VERSION ""

NS_ :

BS_:

BU_: ETH

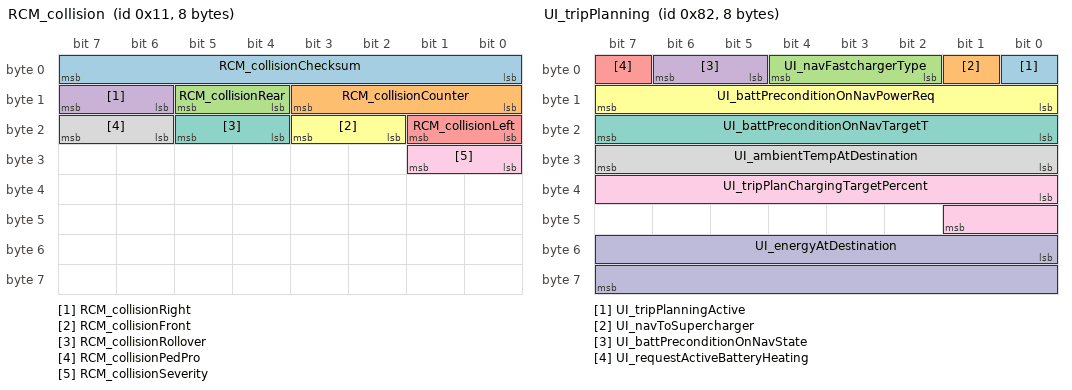
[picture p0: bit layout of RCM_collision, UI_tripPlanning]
BO_ 17 RCM_collision: 8 Vector__XXX
 SG_ RCM_collisionChecksum : 0|8@1+ (1,0) [0|0] "" Vector__XXX
 SG_ RCM_collisionCounter : 8|4@1+ (1,0) [0|0] "" Vector__XXX
 SG_ RCM_collisionRear : 12|2@1+ (1,0) [0|0] "" Vector__XXX
 SG_ RCM_collisionRight : 14|2@1+ (1,0) [0|0] "" Vector__XXX
 SG_ RCM_collisionLeft : 16|2@1+ (1,0) [0|0] "" Vector__XXX
 SG_ RCM_collisionFront : 18|2@1+ (1,0) [0|0] "" Vector__XXX
 SG_ RCM_collisionRollover : 20|2@1+ (1,0) [0|0] "" Vector__XXX
 SG_ RCM_collisionPedPro : 22|2@1+ (1,0) [0|0] "" Vector__XXX
 SG_ RCM_collisionSeverity : 24|2@1+ (1,0) [0|0] "" Vector__XXX

BO_ 79 UI_locationStatus: 8 Vector__XXX
 SG_ UI_latitude : 0|28@1- (1e-06,0) [0|0] "" Vector__XXX
 SG_ UI_longitude : 28|29@1- (1e-06,0) [0|0] "" Vector__XXX
 SG_ UI_gpsAccuracy : 57|7@1+ (0.2,0) [0|0] "" Vector__XXX

BO_ 130 UI_tripPlanning: 8 Vector__XXX
 SG_ UI_tripPlanningActive : 0|1@1+ (1,0) [0|0] "" Vector__XXX
 SG_ UI_navToSupercharger : 1|1@1+ (1,0) [0|0] "" Vector__XXX
 SG_ UI_navFastchargerType : 2|3@1+ (1,0) [0|0] "" Vector__XXX
 SG_ UI_battPreconditionOnNavState : 5|2@1+ (1,0) [0|0] "" Vector__XXX
 SG_ UI_requestActiveBatteryHeating : 7|1@1+ (1,0) [0|0] "" Vector__XXX
 SG_ UI_battPreconditionOnNavPowerReq : 8|8@1- (125,0) [0|0] "" Vector__XXX
 SG_ UI_battPreconditionOnNavTargetT : 16|8@1+ (0.25,0) [0|0] "" Vector__XXX
 SG_ UI_ambientTempAtDestination : 24|8@1- (0.5,0) [0|0] "" Vector__XXX
 SG_ UI_tripPlanChargingTargetPercent : 32|10@1+ (0.1,0) [0|0] "" Vector__XXX
 SG_ UI_energyAtDestination : 48|16@1- (0.01,0) [0|0] "" Vector__XXX

BO_ 258 VCLEFT_doorStatus: 8 Vector__XXX
 SG_ VCLEFT_doorClosureStatusFront : 0|4@1+ (1,0) [0|0] "" Vector__XXX
 SG_ VCLEFT_doorClosureStatusRear : 4|4@1+ (1,0) [0|0] "" Vector__XXX
 SG_ VCLEFT_frontLatchSwitch : 8|1@1+ (1,0) [0|0] "" Vector__XXX
 SG_ VCLEFT_rearLatchSwitch : 9|1@1+ (1,0) [0|0] "" Vector__XXX
 SG_ VCLEFT_frontHandlePulled : 10|1@1+ (1,0) [0|0] "" Vector__XXX
 SG_ VCLEFT_rearHandlePulled : 11|1@1+ (1,0) [0|0] "" Vector__XXX
 SG_ VCLEFT_frontRelActuatorSwitch : 12|1@1+ (1,0) [0|0] "" Vector__XXX
 SG_ VCLEFT_rearRelActuatorSwitch : 13|1@1+ (1,0) [0|0] "" Vector__XXX
 SG_ VCLEFT_frontLatchStatus : 14|4@1+ (1,0) [0|0] "" Vector__XXX
 SG_ VCLEFT_rearLatchStatus : 18|4@1+ (1,0) [0|0] "" Vector__XXX
 SG_ VCLEFT_lastDoorReqSourceFront : 22|3@1+ (1,0) [0|0] "" Vector__XXX
 SG_ VCLEFT_lastDoorReqSourceRear : 25|3@1+ (1,0) [0|0] "" Vector__XXX
 SG_ VCLEFT_frontIntSwitchFaulted : 28|1@1+ (1,0) [0|0] "" Vector__XXX
 SG_ VCLEFT_rearIntSwitchFaulted : 29|1@1+ (1,0) [0|0] "" Vector__XXX
 SG_ VCLEFT_frontIntSwitchPressed : 31|1@1+ (1,0) [0|0] "" Vector__XXX
 SG_ VCLEFT_rearIntSwitchPressed : 32|1@1+ (1,0) [0|0] "" Vector__XXX
 SG_ VCLEFT_mirrorTiltXPosition : 33|8@1+ (0.02,0) [0|0] "" Vector__XXX
 SG_ VCLEFT_mirrorTiltYPosition : 41|8@1+ (0.02,0) [0|0] "" Vector__XXX
 SG_ VCLEFT_mirrorState : 49|3@1+ (1,0) [0|0] "" Vector__XXX
 SG_ VCLEFT_mirrorFoldState : 52|3@1+ (1,0) [0|0] "" Vector__XXX
 SG_ VCLEFT_mirrorRecallState : 55|3@1+ (1,0) [0|0] "" Vector__XXX
 SG_ VCLEFT_mirrorHeatState : 58|3@1+ (1,0) [0|0] "" Vector__XXX
 SG_ VCLEFT_rearHandlePulledPersist : 61|1@1+ (1,0) [0|0] "" Vector__XXX
 SG_ VCLEFT_frontHandlePulledPersist : 62|1@1+ (1,0) [0|0] "" Vector__XXX
 SG_ VCLEFT_mirrorDipped : 63|1@1+ (1,0) [0|0] "" Vector__XXX

BO_ 259 VCRIGHT_doorStatus: 8 Vector__XXX
 SG_ VCRIGHT_doorClosureStatusFront : 0|4@1+ (1,0) [0|0] "" Vector__XXX
 SG_ VCRIGHT_doorClosureStatusRear : 4|4@1+ (1,0) [0|0] "" Vector__XXX
 SG_ VCRIGHT_frontLatchSwitch : 8|1@1+ (1,0) [0|0] "" Vector__XXX
 SG_ VCRIGHT_rearLatchSwitch : 9|1@1+ (1,0) [0|0] "" Vector__XXX
 SG_ VCRIGHT_frontHandlePulled : 10|1@1+ (1,0) [0|0] "" Vector__XXX
 SG_ VCRIGHT_rearHandlePulled : 11|1@1+ (1,0) [0|0] "" Vector__XXX
 SG_ VCRIGHT_frontRelActuatorSwitch : 12|1@1+ (1,0) [0|0] "" Vector__XXX
 SG_ VCRIGHT_rearRelActuatorSwitch : 13|1@1+ (1,0) [0|0] "" Vector__XXX
 SG_ VCRIGHT_frontLatchStatus : 14|4@1+ (1,0) [0|0] "" Vector__XXX
 SG_ VCRIGHT_rearLatchStatus : 18|4@1+ (1,0) [0|0] "" Vector__XXX
 SG_ VCRIGHT_lastDoorReqSourceFront : 22|3@1+ (1,0) [0|0] "" Vector__XXX
 SG_ VCRIGHT_lastDoorReqSourceRear : 25|3@1+ (1,0) [0|0] "" Vector__XXX
 SG_ VCRIGHT_frontIntSwitchFaulted : 28|1@1+ (1,0) [0|0] "" Vector__XXX
 SG_ VCRIGHT_rearIntSwitchFaulted : 29|1@1+ (1,0) [0|0] "" Vector__XXX
 SG_ VCRIGHT_frontHandlePulledPersist : 30|1@1+ (1,0) [0|0] "" Vector__XXX
 SG_ VCRIGHT_frontIntSwitchPressed : 31|1@1+ (1,0) [0|0] "" Vector__XXX
 SG_ VCRIGHT_rearIntSwitchPressed : 32|1@1+ (1,0) [0|0] "" Vector__XXX
 SG_ VCRIGHT_mirrorTiltXPosition : 33|8@1+ (0.02,0) [0|0] "" Vector__XXX
 SG_ VCRIGHT_mirrorTiltYPosition : 41|8@1+ (0.02,0) [0|0] "" Vector__XXX
 SG_ VCRIGHT_mirrorState : 49|3@1+ (1,0) [0|0] "" Vector__XXX
 SG_ VCRIGHT_mirrorFoldState : 52|3@1+ (1,0) [0|0] "" Vector__XXX
 SG_ VCRIGHT_mirrorDipped : 55|1@1+ (1,0) [0|0] "" Vector__XXX
 SG_ VCRIGHT_trunkLatchStatus : 56|4@1+ (1,0) [0|0] "" Vector__XXX
 SG_ VCRIGHT_mirrorRecallState : 60|3@1+ (1,0) [0|0] "" Vector__XXX
 SG_ VCRIGHT_rearHandlePulledPersist : 63|1@1+ (1,0) [0|0] "" Vector__XXX

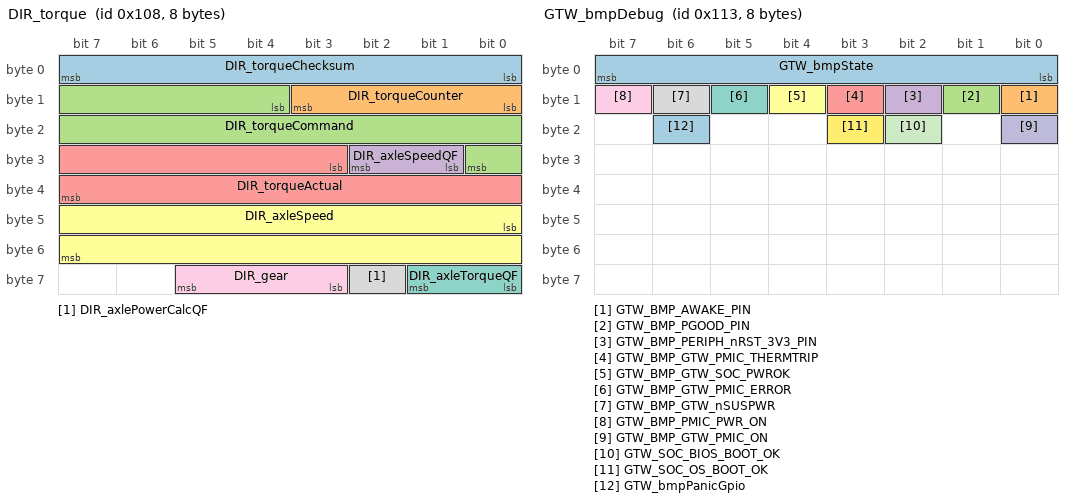
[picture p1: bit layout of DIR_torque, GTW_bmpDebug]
BO_ 264 DIR_torque: 8 Vector__XXX
 SG_ DIR_torqueChecksum : 0|8@1+ (1,0) [0|0] "" Vector__XXX
 SG_ DIR_torqueCounter : 8|4@1+ (1,0) [0|0] "" Vector__XXX
 SG_ DIR_torqueCommand : 12|13@1- (2,0) [0|0] "" Vector__XXX
 SG_ DIR_axleSpeedQF : 25|2@1+ (1,0) [0|0] "" Vector__XXX
 SG_ DIR_torqueActual : 27|13@1- (2,0) [0|0] "" Vector__XXX
 SG_ DIR_axleSpeed : 40|16@1- (0.1,0) [0|0] "" Vector__XXX
 SG_ DIR_axleTorqueQF : 56|2@1+ (1,0) [0|0] "" Vector__XXX
 SG_ DIR_axlePowerCalcQF : 58|1@1+ (1,0) [0|0] "" Vector__XXX
 SG_ DIR_gear : 59|3@1+ (1,0) [0|0] "" Vector__XXX

BO_ 275 GTW_bmpDebug: 8 Vector__XXX
 SG_ GTW_bmpState : 7|8@0+ (1,0) [0|0] "" Vector__XXX
 SG_ GTW_BMP_AWAKE_PIN : 8|1@1+ (1,0) [0|0] "" Vector__XXX
 SG_ GTW_BMP_PGOOD_PIN : 9|1@1+ (1,0) [0|0] "" Vector__XXX
 SG_ GTW_BMP_PERIPH_nRST_3V3_PIN : 10|1@1+ (1,0) [0|0] "" Vector__XXX
 SG_ GTW_BMP_GTW_PMIC_THERMTRIP : 11|1@1+ (1,0) [0|0] "" Vector__XXX
 SG_ GTW_BMP_GTW_SOC_PWROK : 12|1@1+ (1,0) [0|0] "" Vector__XXX
 SG_ GTW_BMP_GTW_PMIC_ERROR : 13|1@1+ (1,0) [0|0] "" Vector__XXX
 SG_ GTW_BMP_GTW_nSUSPWR : 14|1@1+ (1,0) [0|0] "" Vector__XXX
 SG_ GTW_BMP_PMIC_PWR_ON : 15|1@1+ (1,0) [0|0] "" Vector__XXX
 SG_ GTW_BMP_GTW_PMIC_ON : 16|1@1+ (1,0) [0|0] "" Vector__XXX
 SG_ GTW_SOC_BIOS_BOOT_OK : 18|1@1+ (1,0) [0|0] "" Vector__XXX
 SG_ GTW_SOC_OS_BOOT_OK : 19|1@1+ (1,0) [0|0] "" Vector__XXX
 SG_ GTW_bmpPanicGpio : 22|1@0+ (1,0) [0|0] "" Vector__XXX

BO_ 280 DI_systemStatus: 8 Vector__XXX
 SG_ DI_systemStatusChecksum : 0|8@1+ (1,0) [0|0] "" Vector__XXX
 SG_ DI_systemStatusCounter : 8|4@1+ (1,0) [0|0] "" Vector__XXX
 SG_ DI_immobilizerState : 13|3@1+ (1,0) [0|0] "" Vector__XXX
 SG_ DI_systemState : 16|3@1+ (1,0) [0|0] "" Vector__XXX
 SG_ DI_brakePedalState : 19|2@1+ (1,0) [0|0] "" Vector__XXX
 SG_ DI_gear : 21|3@1+ (1,0) [0|0] "" Vector__XXX
 SG_ DI_driveBlocked : 24|3@1+ (1,0) [0|0] "" Vector__XXX
 SG_ DI_hvilSystemStatus : 27|2@1+ (1,0) [0|0] "" Vector__XXX
 SG_ DI_accelPedalPos : 32|8@1+ (0.4,0) [0|0] "" Vector__XXX
 SG_ DI_tractionControlMode : 40|3@1+ (1,0) [0|0] "" Vector__XXX
 SG_ DI_dynoModeAvailable : 43|1@1+ (1,0) [0|0] "" Vector__XXX
 SG_ DI_epbRequest : 44|2@1+ (1,0) [0|0] "" Vector__XXX
 SG_ DI_brakeSource : 46|1@1+ (1,0) [0|0] "" Vector__XXX
 SG_ DI_keepDrivePowerStateRequest : 47|1@1+ (1,0) [0|0] "" Vector__XXX
 SG_ DI_trackModeState : 48|2@1+ (1,0) [0|0] "" Vector__XXX
 SG_ DI_autonomyControlActive : 50|1@1+ (1,0) [0|0] "" Vector__XXX
 SG_ DI_regenLight : 51|1@1+ (1,0) [0|0] "" Vector__XXX
 SG_ DI_vehicleAcceleration : 52|12@1- (0.01,0) [0|0] "" Vector__XXX

BO_ 281 VCSEC_requests2: 8 Vector__XXX
 SG_ VCSEC_hvacRunScreenProtectOnly : 15|1@1+ (1,0) [0|0] "" Vector__XXX
 SG_ VCSEC_chargeHandleRequestModel : 16|4@1+ (1,0) [0|0] "" Vector__XXX
 SG_ VCSEC_recoveryModeRequested : 21|1@1+ (1,0) [0|0] "" Vector__XXX
 SG_ VCSEC_infotainmentResetRequested : 22|1@1+ (1,0) [0|0] "" Vector__XXX
 SG_ VCSEC_mobileToAPRequest : 23|3@1+ (1,0) [0|0] "" Vector__XXX
 SG_ VCSEC_riderKeyPresent : 26|1@1+ (1,0) [0|0] "" Vector__XXX

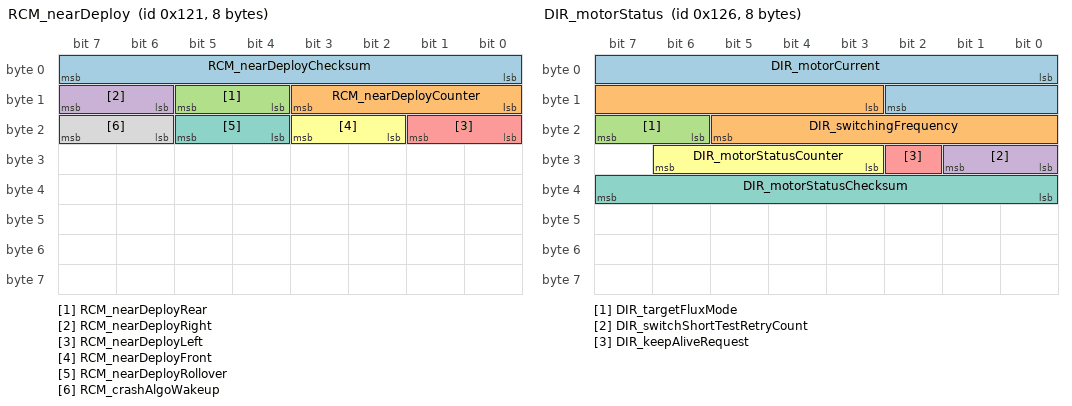
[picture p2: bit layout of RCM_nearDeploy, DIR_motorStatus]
BO_ 289 RCM_nearDeploy: 8 Vector__XXX
 SG_ RCM_nearDeployChecksum : 0|8@1+ (1,0) [0|0] "" Vector__XXX
 SG_ RCM_nearDeployCounter : 8|4@1+ (1,0) [0|0] "" Vector__XXX
 SG_ RCM_nearDeployRear : 12|2@1+ (1,0) [0|0] "" Vector__XXX
 SG_ RCM_nearDeployRight : 14|2@1+ (1,0) [0|0] "" Vector__XXX
 SG_ RCM_nearDeployLeft : 16|2@1+ (1,0) [0|0] "" Vector__XXX
 SG_ RCM_nearDeployFront : 18|2@1+ (1,0) [0|0] "" Vector__XXX
 SG_ RCM_nearDeployRollover : 20|2@1+ (1,0) [0|0] "" Vector__XXX
 SG_ RCM_crashAlgoWakeup : 22|2@1+ (1,0) [0|0] "" Vector__XXX

BO_ 290 VCLEFT_doorStatus2: 8 Vector__XXX
 SG_ VCLEFT_doorStatus2Index M : 0|1@1+ (1,0) [0|0] "" Vector__XXX
 SG_ VCLEFT_frontLatchRelDuty m1 : 8|8@1+ (1,0) [0|0] "" Vector__XXX
 SG_ VCLEFT_rearLatchRelDuty m0 : 8|8@1+ (1,0) [0|0] "" Vector__XXX
 SG_ VCLEFT_BPillarCameraHeaterState m1 : 16|3@1+ (1,0) [0|0] "" Vector__XXX
 SG_ VCLEFT_vehicleInMotion m0 : 16|1@1+ (1,0) [0|0] "" Vector__XXX
 SG_ VCLEFT_frontDoorState m0 : 17|3@1+ (1,0) [0|0] "" Vector__XXX
 SG_ VCLEFT_rearDoorState m0 : 20|3@1+ (1,0) [0|0] "" Vector__XXX
 SG_ VCLEFT_frontHandleRawStatus m0 : 24|3@1+ (1,0) [0|0] "" Vector__XXX
 SG_ VCLEFT_rearHandleRawStatus m0 : 27|3@1+ (1,0) [0|0] "" Vector__XXX
 SG_ VCLEFT_mirrorFoldType m0 : 30|2@1+ (1,0) [0|0] "" Vector__XXX
 SG_ VCLEFT_frontHandleDebounceStatus m0 : 32|3@1+ (1,0) [0|0] "" Vector__XXX
 SG_ VCLEFT_rearHandleDebounceStatus m0 : 35|3@1+ (1,0) [0|0] "" Vector__XXX
 SG_ VCLEFT_frontHandle5vEnable m0 : 38|1@1+ (1,0) [0|0] "" Vector__XXX
 SG_ VCLEFT_rearHandle5vEnable m0 : 39|1@1+ (1,0) [0|0] "" Vector__XXX
 SG_ VCLEFT_BPillarCameraHeaterCurrent m1 : 40|6@1+ (0.02,0) [0|0] "" Vector__XXX
 SG_ VCLEFT_mirrorFoldCurrent m0 : 40|7@1- (0.05,0) [0|0] "" Vector__XXX
 SG_ VCLEFT_mirrorDimmed m0 : 47|1@1+ (1,0) [0|0] "" Vector__XXX
 SG_ VCLEFT_frontHandlePWM m0 : 48|7@1+ (1,0) [0|0] "" Vector__XXX
 SG_ VCLEFT_mirrorTiltXOffset m1 : 48|8@1- (0.02,0) [0|0] "" Vector__XXX
 SG_ VCLEFT_mirrorTiltYOffset m1 : 56|8@1- (0.02,0) [0|0] "" Vector__XXX
 SG_ VCLEFT_rearHandlePWM m0 : 56|7@1+ (1,0) [0|0] "" Vector__XXX

BO_ 291 VCRIGHT_doorStatus2: 8 Vector__XXX
 SG_ VCRIGHT_doorStatus2Index M : 0|1@1+ (1,0) [0|0] "" Vector__XXX
 SG_ VCRIGHT_frontLatchRelDuty m1 : 8|8@1+ (1,0) [0|0] "" Vector__XXX
 SG_ VCRIGHT_rearLatchRelDuty m0 : 8|8@1+ (1,0) [0|0] "" Vector__XXX
 SG_ VCRIGHT_BPillarCameraHeaterState m1 : 16|3@1+ (1,0) [0|0] "" Vector__XXX
 SG_ VCRIGHT_vehicleInMotion m0 : 16|1@1+ (1,0) [0|0] "" Vector__XXX
 SG_ VCRIGHT_frontDoorState m0 : 17|3@1+ (1,0) [0|0] "" Vector__XXX
 SG_ VCRIGHT_rearDoorState m0 : 20|3@1+ (1,0) [0|0] "" Vector__XXX
 SG_ VCRIGHT_mirrorDimmed m0 : 23|1@1+ (1,0) [0|0] "" Vector__XXX
 SG_ VCRIGHT_frontHandleRawStatus m0 : 24|3@1+ (1,0) [0|0] "" Vector__XXX
 SG_ VCRIGHT_rearHandleRawStatus m0 : 27|3@1+ (1,0) [0|0] "" Vector__XXX
 SG_ VCRIGHT_mirrorFoldType m0 : 30|2@1+ (1,0) [0|0] "" Vector__XXX
 SG_ VCRIGHT_frontHandleDebounceStatus m0 : 32|3@1+ (1,0) [0|0] "" Vector__XXX
 SG_ VCRIGHT_rearHandleDebounceStatus m0 : 35|3@1+ (1,0) [0|0] "" Vector__XXX
 SG_ VCRIGHT_frontHandle5vEnable m0 : 38|1@1+ (1,0) [0|0] "" Vector__XXX
 SG_ VCRIGHT_rearHandle5vEnable m0 : 39|1@1+ (1,0) [0|0] "" Vector__XXX
 SG_ VCRIGHT_BPillarCameraHeaterCurrent m1 : 40|6@1+ (0.02,0) [0|0] "" Vector__XXX
 SG_ VCRIGHT_mirrorFoldCurrent m0 : 40|7@1- (0.05,0) [0|0] "" Vector__XXX
 SG_ VCRIGHT_gloveboxOutput m0 : 47|1@1+ (1,0) [0|0] "" Vector__XXX
 SG_ VCRIGHT_mirrorTiltXOffset m1 : 48|8@1- (0.02,0) [0|0] "" Vector__XXX
 SG_ VCRIGHT_rearDefrostCurrentFiltered m0 : 48|7@1+ (1,0) [0|0] "" Vector__XXX
 SG_ VCRIGHT_mirrorTiltYOffset m1 : 56|8@1- (0.02,0) [0|0] "" Vector__XXX
 SG_ VCRIGHT_trunkRatchetSwitch m0 : 61|1@1+ (1,0) [0|0] "" Vector__XXX
 SG_ VCRIGHT_trunkPawlSwitch m0 : 62|1@1+ (1,0) [0|0] "" Vector__XXX
 SG_ VCRIGHT_trunkHomeSwitch m0 : 63|1@1+ (1,0) [0|0] "" Vector__XXX

BO_ 294 DIR_motorStatus: 8 Vector__XXX
 SG_ DIR_motorCurrent : 0|11@1+ (1,0) [0|0] "" Vector__XXX
 SG_ DIR_switchingFrequency : 11|11@1+ (0.01,0) [0|0] "" Vector__XXX
 SG_ DIR_targetFluxMode : 22|2@1+ (1,0) [0|0] "" Vector__XXX
 SG_ DIR_switchShortTestRetryCount : 24|2@1+ (1,0) [0|0] "" Vector__XXX
 SG_ DIR_keepAliveRequest : 26|1@1+ (1,0) [0|0] "" Vector__XXX
 SG_ DIR_motorStatusCounter : 27|4@1+ (1,0) [0|0] "" Vector__XXX
 SG_ DIR_motorStatusChecksum : 32|8@1+ (1,0) [0|0] "" Vector__XXX

BO_ 296 DI_systemLimits: 8 Vector__XXX
 SG_ DI_limitRegenPower : 0|1@1+ (1,0) [0|0] "" Vector__XXX
 SG_ DI_limitIBat : 1|1@1+ (1,0) [0|0] "" Vector__XXX
 SG_ DI_limitVBatLow : 2|1@1+ (1,0) [0|0] "" Vector__XXX
 SG_ DI_limitVBatHigh : 3|1@1+ (1,0) [0|0] "" Vector__XXX
 SG_ DI_limitObstacleDetection : 4|1@1+ (1,0) [0|0] "" Vector__XXX
 SG_ DI_limitSystemLimp : 5|1@1+ (1,0) [0|0] "" Vector__XXX
 SG_ DI_limitSystemGPO : 6|1@1+ (1,0) [0|0] "" Vector__XXX
 SG_ DI_limitShift : 7|1@1+ (1,0) [0|0] "" Vector__XXX
 SG_ DI_limitDriveTorque : 8|1@1+ (1,0) [0|0] "" Vector__XXX
 SG_ DI_limitRegenTorque : 9|1@1+ (1,0) [0|0] "" Vector__XXX
 SG_ DI_limitVehicleSpeed : 10|1@1+ (1,0) [0|0] "" Vector__XXX
 SG_ DI_limitBmsMiaFreeze : 11|1@1+ (1,0) [0|0] "" Vector__XXX
 SG_ DI_limitSystemSpinDownLearning : 12|1@1+ (1,0) [0|0] "" Vector__XXX
 SG_ DI_limitCdp : 13|1@1+ (1,0) [0|0] "" Vector__XXX
 SG_ DI_vehicleSpeedLimitType : 14|2@1+ (1,0) [0|0] "" Vector__XXX
 SG_ DI_vehicleSpeedLimit : 16|9@1+ (1,0) [0|0] "" Vector__XXX
 SG_ DI_vehicleSpeedLimitReason : 25|5@1+ (1,0) [0|0] "" Vector__XXX
 SG_ DI_proximity : 30|1@1+ (1,0) [0|0] "" Vector__XXX
 SG_ DI_limitClosureNotClosed : 31|1@1+ (1,0) [0|0] "" Vector__XXX
 SG_ DI_undersideAbuse : 32|1@1+ (1,0) [0|0] "" Vector__XXX
 SG_ DI_immobilizerAuthLevel : 33|2@1+ (1,0) [0|0] "" Vector__XXX

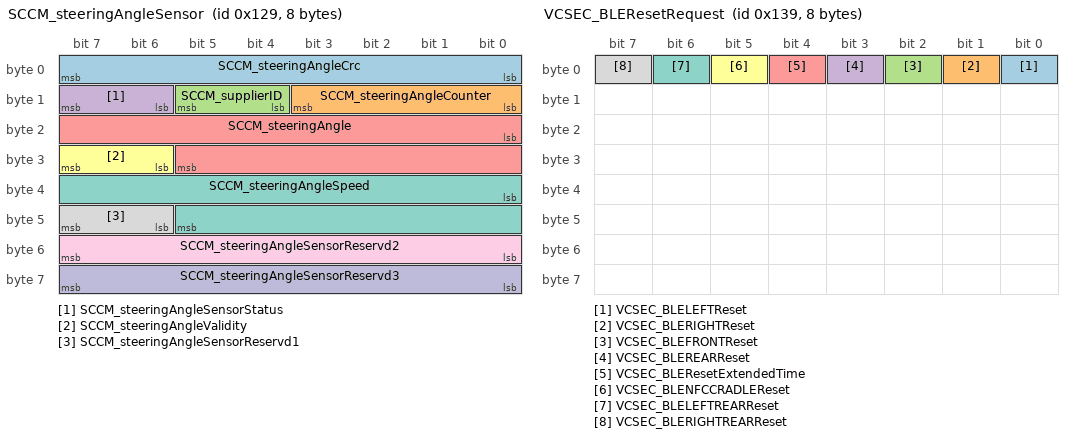
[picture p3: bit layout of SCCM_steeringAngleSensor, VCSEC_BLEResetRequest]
BO_ 297 SCCM_steeringAngleSensor: 8 Vector__XXX
 SG_ SCCM_steeringAngleCrc : 0|8@1+ (1,0) [0|0] "" Vector__XXX
 SG_ SCCM_steeringAngleCounter : 8|4@1+ (1,0) [0|0] "" Vector__XXX
 SG_ SCCM_supplierID : 12|2@1+ (1,0) [0|0] "" Vector__XXX
 SG_ SCCM_steeringAngleSensorStatus : 14|2@1+ (1,0) [0|0] "" Vector__XXX
 SG_ SCCM_steeringAngle : 16|14@1+ (0.1,-819.2) [0|0] "" Vector__XXX
 SG_ SCCM_steeringAngleValidity : 30|2@1+ (1,0) [0|0] "" Vector__XXX
 SG_ SCCM_steeringAngleSpeed : 32|14@1+ (0.5,-4096) [0|0] "" Vector__XXX
 SG_ SCCM_steeringAngleSensorReservd1 : 46|2@1+ (1,0) [0|0] "" Vector__XXX
 SG_ SCCM_steeringAngleSensorReservd2 : 48|8@1+ (1,0) [0|0] "" Vector__XXX
 SG_ SCCM_steeringAngleSensorReservd3 : 56|8@1+ (1,0) [0|0] "" Vector__XXX

BO_ 306 BMS_hvBusStatus: 8 Vector__XXX
 SG_ BMS_dcLinkVoltage : 0|16@1+ (0.01,0) [0|0] "" Vector__XXX
 SG_ BMS_packCurrent : 16|16@1- (0.1,0) [0|0] "" Vector__XXX
 SG_ BMS_currentUnfiltered : 32|16@1- (0.05,-822) [0|0] "" Vector__XXX

BO_ 313 VCSEC_BLEResetRequest: 8 Vector__XXX
 SG_ VCSEC_BLELEFTReset : 0|1@1+ (1,0) [0|0] "" Vector__XXX
 SG_ VCSEC_BLERIGHTReset : 1|1@1+ (1,0) [0|0] "" Vector__XXX
 SG_ VCSEC_BLEFRONTReset : 2|1@1+ (1,0) [0|0] "" Vector__XXX
 SG_ VCSEC_BLEREARReset : 3|1@1+ (1,0) [0|0] "" Vector__XXX
 SG_ VCSEC_BLEResetExtendedTime : 4|1@1+ (1,0) [0|0] "" Vector__XXX
 SG_ VCSEC_BLENFCCRADLEReset : 5|1@1+ (1,0) [0|0] "" Vector__XXX
 SG_ VCSEC_BLELEFTREARReset : 6|1@1+ (1,0) [0|0] "" Vector__XXX
 SG_ VCSEC_BLERIGHTREARReset : 7|1@1+ (1,0) [0|0] "" Vector__XXX

BO_ 322 VCLEFT_liftgateStatus: 8 Vector__XXX
 SG_ VCLEFT_liftgateStatusIndex M : 0|2@1+ (1,0) [0|0] "" Vector__XXX
 SG_ VCLEFT_liftgateState m0 : 3|4@1+ (1,0) [0|0] "" Vector__XXX
 SG_ VCLEFT_liftgateStrutDutyCycle m1 : 3|8@1- (1,0) [0|0] "" Vector__XXX
 SG_ VCLEFT_liftgateStoppingCondition m0 : 10|4@1+ (1,0) [0|0] "" Vector__XXX
 SG_ VCLEFT_liftgateStrutCurrent m1 : 11|10@1- (0.1,0) [0|0] "" Vector__XXX
 SG_ VCLEFT_liftgateMvmntNotAllowedCondition m0 : 14|3@1+ (1,0) [0|0] "" Vector__XXX
 SG_ VCLEFT_liftgatePositionCalibrated m0 : 17|1@1+ (1,0) [0|0] "" Vector__XXX
 SG_ VCLEFT_liftgateUIChimeRequest m0 : 18|3@1+ (1,0) [0|0] "" Vector__XXX
 SG_ VCLEFT_liftgatePhysicalChimeRequest m0 : 21|3@1+ (1,0) [0|0] "" Vector__XXX
 SG_ VCLEFT_liftgatePosition m1 : 21|7@1- (1,46) [0|0] "" Vector__XXX
 SG_ VCLEFT_liftgateEstimatedStrutTemp m0 : 24|8@1+ (1,-60) [0|0] "" Vector__XXX
 SG_ VCLEFT_liftgateSpeed m1 : 28|10@1- (0.1,0) [0|0] "" Vector__XXX
 SG_ VCLEFT_liftgateStaticStrutMode m0 : 32|3@1+ (1,0) [0|0] "" Vector__XXX
 SG_ VCLEFT_liftgateRequestSource m0 : 35|4@1+ (1,0) [0|0] "" Vector__XXX
 SG_ VCLEFT_liftgateHeight m1 : 38|8@1+ (1,0) [0|0] "" Vector__XXX
 SG_ VCLEFT_liftgateNewHeightNudge m0 : 39|1@1+ (1,0) [0|0] "" Vector__XXX
 SG_ VCLEFT_liftgateNewSaveHeight m0 : 40|8@1+ (1,0) [0|0] "" Vector__XXX
 SG_ VCLEFT_liftgateGeofenceState m0 : 48|2@1+ (1,0) [0|0] "" Vector__XXX
 SG_ VCLEFT_liftgateCloseWarnChimeRequest m0 : 56|1@1+ (1,0) [0|0] "" Vector__XXX
 SG_ VCLEFT_liftgateAboveCrossoverAngle m0 : 59|1@1+ (1,0) [0|0] "" Vector__XXX
 SG_ VCLEFT_liftgateLatchRequest m0 : 61|3@1+ (1,0) [0|0] "" Vector__XXX

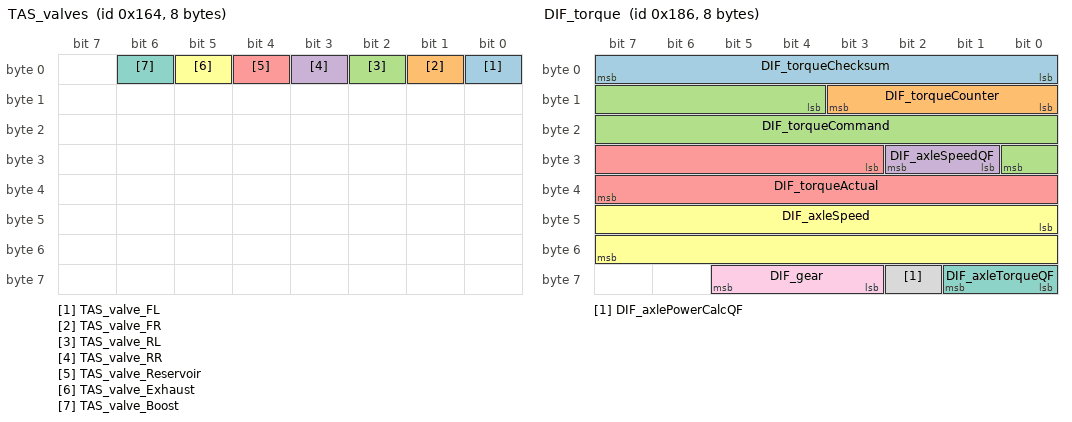
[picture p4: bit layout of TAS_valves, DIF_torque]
BO_ 356 TAS_valves: 8 Vector__XXX
 SG_ TAS_valve_FL : 0|1@1+ (1,0) [0|0] "" Vector__XXX
 SG_ TAS_valve_FR : 1|1@1+ (1,0) [0|0] "" Vector__XXX
 SG_ TAS_valve_RL : 2|1@1+ (1,0) [0|0] "" Vector__XXX
 SG_ TAS_valve_RR : 3|1@1+ (1,0) [0|0] "" Vector__XXX
 SG_ TAS_valve_Reservoir : 4|1@1+ (1,0) [0|0] "" Vector__XXX
 SG_ TAS_valve_Exhaust : 5|1@1+ (1,0) [0|0] "" Vector__XXX
 SG_ TAS_valve_Boost : 6|1@1+ (1,0) [0|0] "" Vector__XXX

BO_ 357 TAS_voltages: 8 Vector__XXX
 SG_ TAS_12V_supply : 0|8@1+ (0.075,0) [0|0] "" Vector__XXX
 SG_ TAS_12V_switched : 8|8@1+ (0.075,0) [0|0] "" Vector__XXX
 SG_ TAS_5V_heightSensors : 16|8@1+ (0.025,0) [0|0] "" Vector__XXX
 SG_ TAS_5V_analogSensors : 24|8@1+ (0.025,0) [0|0] "" Vector__XXX
 SG_ TAS_5V_onboard : 32|8@1+ (0.025,0) [0|0] "" Vector__XXX

BO_ 358 TAS_temperatures: 8 Vector__XXX
 SG_ TAS_tempIndex M : 0|2@1+ (1,0) [0|0] "" Vector__XXX
 SG_ TAS_temp_FL_C m0 : 8|8@1+ (1,-40) [0|0] "" Vector__XXX
 SG_ TAS_temp_K_HSD m2 : 8|8@1+ (1,-40) [0|0] "" Vector__XXX
 SG_ TAS_temp_RL_C m1 : 8|8@1+ (1,-40) [0|0] "" Vector__XXX
 SG_ TAS_temp_FL_R m0 : 16|8@1+ (1,-40) [0|0] "" Vector__XXX
 SG_ TAS_temp_RL_R m1 : 16|8@1+ (1,-40) [0|0] "" Vector__XXX
 SG_ TAS_temp_VBAT_SW m2 : 16|8@1+ (1,-40) [0|0] "" Vector__XXX
 SG_ TAS_temp_FL_K m0 : 24|8@1+ (1,-40) [0|0] "" Vector__XXX
 SG_ TAS_temp_RL_K m1 : 24|8@1+ (1,-40) [0|0] "" Vector__XXX
 SG_ TAS_temp_FR_C m0 : 32|8@1+ (1,-40) [0|0] "" Vector__XXX
 SG_ TAS_temp_RR_C m1 : 32|8@1+ (1,-40) [0|0] "" Vector__XXX
 SG_ TAS_temp_FR_R m0 : 40|8@1+ (1,-40) [0|0] "" Vector__XXX
 SG_ TAS_temp_RR_R m1 : 40|8@1+ (1,-40) [0|0] "" Vector__XXX
 SG_ TAS_temp_FR_K m0 : 48|8@1+ (1,-40) [0|0] "" Vector__XXX
 SG_ TAS_temp_RR_K m1 : 48|8@1+ (1,-40) [0|0] "" Vector__XXX
 SG_ TAS_temp_F_CR_HSD m0 : 56|8@1+ (1,-40) [0|0] "" Vector__XXX
 SG_ TAS_temp_R_CR_HSD m1 : 56|8@1+ (1,-40) [0|0] "" Vector__XXX

BO_ 359 TAS_currentsSpring: 8 Vector__XXX
 SG_ TAS_current_FL_K : 0|8@1+ (0.01,0) [0|0] "" Vector__XXX
 SG_ TAS_current_FR_K : 8|8@1+ (0.01,0) [0|0] "" Vector__XXX
 SG_ TAS_current_RL_K : 16|8@1+ (0.01,0) [0|0] "" Vector__XXX
 SG_ TAS_current_RR_K : 24|8@1+ (0.01,0) [0|0] "" Vector__XXX

BO_ 390 DIF_torque: 8 Vector__XXX
 SG_ DIF_torqueChecksum : 0|8@1+ (1,0) [0|0] "" Vector__XXX
 SG_ DIF_torqueCounter : 8|4@1+ (1,0) [0|0] "" Vector__XXX
 SG_ DIF_torqueCommand : 12|13@1- (2,0) [0|0] "" Vector__XXX
 SG_ DIF_axleSpeedQF : 25|2@1+ (1,0) [0|0] "" Vector__XXX
 SG_ DIF_torqueActual : 27|13@1- (2,0) [0|0] "" Vector__XXX
 SG_ DIF_axleSpeed : 40|16@1- (0.1,0) [0|0] "" Vector__XXX
 SG_ DIF_axleTorqueQF : 56|2@1+ (1,0) [0|0] "" Vector__XXX
 SG_ DIF_axlePowerCalcQF : 58|1@1+ (1,0) [0|0] "" Vector__XXX
 SG_ DIF_gear : 59|3@1+ (1,0) [0|0] "" Vector__XXX

BO_ 405 DIF_limits: 8 Vector__XXX
 SG_ DIF_limitPCBTemp : 0|1@1+ (1,0) [0|0] "" Vector__XXX
 SG_ DIF_limitInverterTemp : 1|1@1+ (1,0) [0|0] "" Vector__XXX
 SG_ DIF_limitStatorTemp : 2|1@1+ (1,0) [0|0] "" Vector__XXX
 SG_ DIF_limitPoleTemp : 3|1@1+ (1,0) [0|0] "" Vector__XXX
 SG_ DIF_limitUnitLimp : 4|1@1+ (1,0) [0|0] "" Vector__XXX
 SG_ DIF_limitDeltaFluidTemp : 5|1@1+ (1,0) [0|0] "" Vector__XXX
 SG_ DIF_limitDischargePower : 6|1@1+ (1,0) [0|0] "" Vector__XXX
 SG_ DIF_limitMotorCurrent : 7|1@1+ (1,0) [0|0] "" Vector__XXX
 SG_ DIF_limitMotorVoltage : 8|1@1+ (1,0) [0|0] "" Vector__XXX
 SG_ DIF_limitTCDrive : 9|1@1+ (1,0) [0|0] "" Vector__XXX
 SG_ DIF_limitTCRegen : 10|1@1+ (1,0) [0|0] "" Vector__XXX
 SG_ DIF_limitBaseSpeed : 11|1@1+ (1,0) [0|0] "" Vector__XXX
 SG_ DIF_limitDcCapTemp : 12|1@1+ (1,0) [0|0] "" Vector__XXX
 SG_ DIF_limitMotorSpeed : 13|1@1+ (1,0) [0|0] "" Vector__XXX
 SG_ DIF_limitDiff : 14|1@1+ (1,0) [0|0] "" Vector__XXX
 SG_ DIF_limitUnitGPO : 15|1@1+ (1,0) [0|0] "" Vector__XXX
 SG_ DIF_limitShockTorque : 16|1@1+ (1,0) [0|0] "" Vector__XXX
 SG_ DIF_limitOilPumpFluidTemp : 17|1@1+ (1,0) [0|0] "" Vector__XXX
 SG_ DIF_limitStatorFrequency : 18|1@1+ (1,0) [0|0] "" Vector__XXX
 SG_ DIF_limitClutch : 19|1@1+ (1,0) [0|0] "" Vector__XXX
 SG_ DIF_limitphaseOutBusbarTemp : 20|1@1+ (1,0) [0|0] "" Vector__XXX
 SG_ DIF_limitphaseOutBusBarWeldTemp : 21|1@1+ (1,0) [0|0] "" Vector__XXX
 SG_ DIF_limitphaseOutLugTemp : 22|1@1+ (1,0) [0|0] "" Vector__XXX
 SG_ DIF_limitdcLinkCapTemp : 23|1@1+ (1,0) [0|0] "" Vector__XXX
 SG_ DIF_limitnegDcBusbarTemp : 24|1@1+ (1,0) [0|0] "" Vector__XXX
 SG_ DIF_limitposDcBusbarTemp : 25|1@1+ (1,0) [0|0] "" Vector__XXX
 SG_ DIF_limitRotorTemp : 26|1@1+ (1,0) [0|0] "" Vector__XXX
 SG_ DIF_limithvDcCableTemp : 27|1@1+ (1,0) [0|0] "" Vector__XXX
 SG_ DIF_limitUnitSpinDownLearning : 28|1@1+ (1,0) [0|0] "" Vector__XXX
 SG_ DIF_limitStatorHousingTemp : 29|1@1+ (1,0) [0|0] "" Vector__XXX
 SG_ DIF_statorTempFromResist : 30|8@1+ (1,-40) [0|0] "" Vector__XXX
 SG_ DIF_magnetFluxError : 38|8@1- (8e-05,0) [0|0] "" Vector__XXX
 SG_ DIF_currentLimit : 46|16@1+ (0.1,0) [0|0] "" Vector__XXX
 SG_ DIF_pstgDisableHW3PS : 62|1@1+ (1,0) [0|0] "" Vector__XXX
 SG_ DIF_pstgDisableSW3PS : 63|1@1+ (1,0) [0|0] "" Vector__XXX

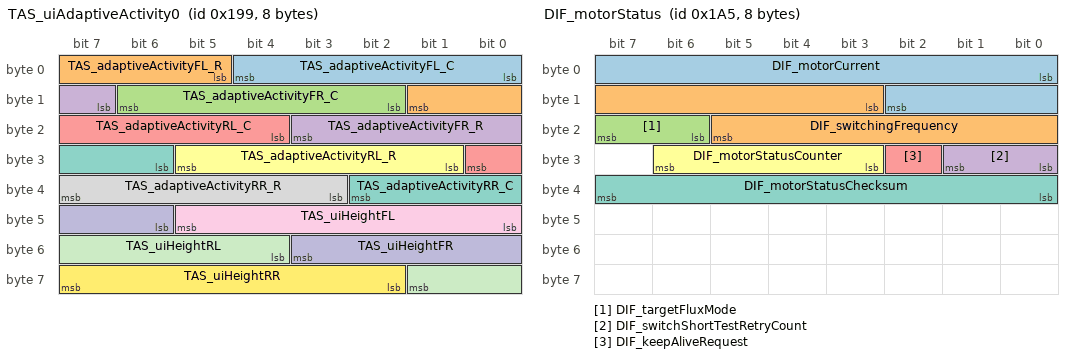
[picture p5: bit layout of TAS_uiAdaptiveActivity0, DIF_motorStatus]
BO_ 409 TAS_uiAdaptiveActivity0: 8 Vector__XXX
 SG_ TAS_adaptiveActivityFL_C : 0|5@1+ (0.04,0) [0|0] "" Vector__XXX
 SG_ TAS_adaptiveActivityFL_R : 5|5@1+ (0.04,0) [0|0] "" Vector__XXX
 SG_ TAS_adaptiveActivityFR_C : 10|5@1+ (0.04,0) [0|0] "" Vector__XXX
 SG_ TAS_adaptiveActivityFR_R : 15|5@1+ (0.04,0) [0|0] "" Vector__XXX
 SG_ TAS_adaptiveActivityRL_C : 20|5@1+ (0.04,0) [0|0] "" Vector__XXX
 SG_ TAS_adaptiveActivityRL_R : 25|5@1+ (0.04,0) [0|0] "" Vector__XXX
 SG_ TAS_adaptiveActivityRR_C : 30|5@1+ (0.04,0) [0|0] "" Vector__XXX
 SG_ TAS_adaptiveActivityRR_R : 35|5@1+ (0.04,0) [0|0] "" Vector__XXX
 SG_ TAS_uiHeightFL : 40|6@1+ (4,-128) [0|0] "" Vector__XXX
 SG_ TAS_uiHeightFR : 46|6@1+ (4,-128) [0|0] "" Vector__XXX
 SG_ TAS_uiHeightRL : 52|6@1+ (4,-128) [0|0] "" Vector__XXX
 SG_ TAS_uiHeightRR : 58|6@1+ (4,-128) [0|0] "" Vector__XXX

BO_ 410 TAS_uiAdaptiveActivity1: 8 Vector__XXX
 SG_ TAS_bodyAccelFL : 0|8@1+ (0.05,-5) [0|0] "" Vector__XXX
 SG_ TAS_bodyAccelFR : 8|8@1+ (0.05,-5) [0|0] "" Vector__XXX
 SG_ TAS_bodyAccelRL : 16|8@1+ (0.05,-5) [0|0] "" Vector__XXX
 SG_ TAS_bodyAccelRR : 24|8@1+ (0.05,-5) [0|0] "" Vector__XXX

BO_ 421 DIF_motorStatus: 8 Vector__XXX
 SG_ DIF_motorCurrent : 0|11@1+ (1,0) [0|0] "" Vector__XXX
 SG_ DIF_switchingFrequency : 11|11@1+ (0.01,0) [0|0] "" Vector__XXX
 SG_ DIF_targetFluxMode : 22|2@1+ (1,0) [0|0] "" Vector__XXX
 SG_ DIF_switchShortTestRetryCount : 24|2@1+ (1,0) [0|0] "" Vector__XXX
 SG_ DIF_keepAliveRequest : 26|1@1+ (1,0) [0|0] "" Vector__XXX
 SG_ DIF_motorStatusCounter : 27|4@1+ (1,0) [0|0] "" Vector__XXX
 SG_ DIF_motorStatusChecksum : 32|8@1+ (1,0) [0|0] "" Vector__XXX

BO_ 443 UI_peripheralPowerRequests: 8 Vector__XXX
 SG_ UI_usbFrontHubPowerStateRequest : 0|2@1+ (1,0) [0|0] "" Vector__XXX

BO_ 455 TASDBG_currentsDamper: 8 Vector__XXX
 SG_ TASDBG_current_FL_C : 0|8@1+ (0.0075,0) [0|0] "" Vector__XXX
 SG_ TASDBG_current_FL_R : 8|8@1+ (0.0075,0) [0|0] "" Vector__XXX
 SG_ TASDBG_current_FR_C : 16|8@1+ (0.0075,0) [0|0] "" Vector__XXX
 SG_ TASDBG_current_FR_R : 24|8@1+ (0.0075,0) [0|0] "" Vector__XXX
 SG_ TASDBG_current_RL_C : 32|8@1+ (0.0075,0) [0|0] "" Vector__XXX
 SG_ TASDBG_current_RL_R : 40|8@1+ (0.0075,0) [0|0] "" Vector__XXX
 SG_ TASDBG_current_RR_C : 48|8@1+ (0.0075,0) [0|0] "" Vector__XXX
 SG_ TASDBG_current_RR_R : 56|8@1+ (0.0075,0) [0|0] "" Vector__XXX

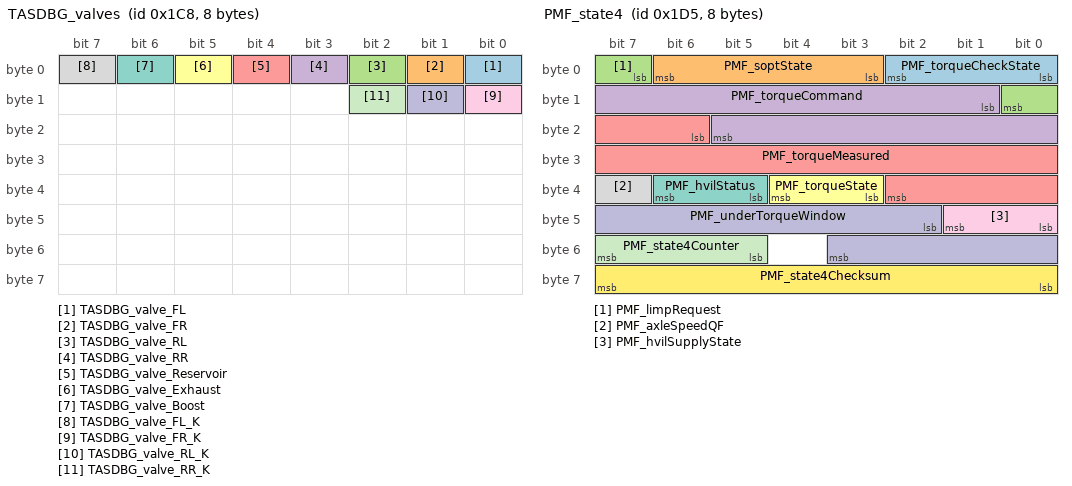
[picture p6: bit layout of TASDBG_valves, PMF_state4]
BO_ 456 TASDBG_valves: 8 Vector__XXX
 SG_ TASDBG_valve_FL : 0|1@1+ (1,0) [0|0] "" Vector__XXX
 SG_ TASDBG_valve_FR : 1|1@1+ (1,0) [0|0] "" Vector__XXX
 SG_ TASDBG_valve_RL : 2|1@1+ (1,0) [0|0] "" Vector__XXX
 SG_ TASDBG_valve_RR : 3|1@1+ (1,0) [0|0] "" Vector__XXX
 SG_ TASDBG_valve_Reservoir : 4|1@1+ (1,0) [0|0] "" Vector__XXX
 SG_ TASDBG_valve_Exhaust : 5|1@1+ (1,0) [0|0] "" Vector__XXX
 SG_ TASDBG_valve_Boost : 6|1@1+ (1,0) [0|0] "" Vector__XXX
 SG_ TASDBG_valve_FL_K : 7|1@1+ (1,0) [0|0] "" Vector__XXX
 SG_ TASDBG_valve_FR_K : 8|1@1+ (1,0) [0|0] "" Vector__XXX
 SG_ TASDBG_valve_RL_K : 9|1@1+ (1,0) [0|0] "" Vector__XXX
 SG_ TASDBG_valve_RR_K : 10|1@1+ (1,0) [0|0] "" Vector__XXX

BO_ 469 PMF_state4: 8 Vector__XXX
 SG_ PMF_torqueCheckState : 0|3@1+ (1,0) [0|0] "" Vector__XXX
 SG_ PMF_soptState : 3|4@1+ (1,0) [0|0] "" Vector__XXX
 SG_ PMF_limpRequest : 7|2@1+ (1,0) [0|0] "" Vector__XXX
 SG_ PMF_torqueCommand : 9|13@1- (2,0) [0|0] "" Vector__XXX
 SG_ PMF_torqueMeasured : 22|13@1- (2,0) [0|0] "" Vector__XXX
 SG_ PMF_torqueState : 35|2@1+ (1,0) [0|0] "" Vector__XXX
 SG_ PMF_hvilStatus : 37|2@1+ (1,0) [0|0] "" Vector__XXX
 SG_ PMF_axleSpeedQF : 39|1@1+ (1,0) [0|0] "" Vector__XXX
 SG_ PMF_hvilSupplyState : 40|2@1+ (1,0) [0|0] "" Vector__XXX
 SG_ PMF_underTorqueWindow : 42|10@1+ (0.005,0) [0|0] "" Vector__XXX
 SG_ PMF_state4Counter : 53|3@1+ (1,0) [0|0] "" Vector__XXX
 SG_ PMF_state4Checksum : 56|8@1+ (1,0) [0|0] "" Vector__XXX

BO_ 470 DIR_limits: 8 Vector__XXX
 SG_ DIR_limitPCBTemp : 0|1@1+ (1,0) [0|0] "" Vector__XXX
 SG_ DIR_limitInverterTemp : 1|1@1+ (1,0) [0|0] "" Vector__XXX
 SG_ DIR_limitStatorTemp : 2|1@1+ (1,0) [0|0] "" Vector__XXX
 SG_ DIR_limitPoleTemp : 3|1@1+ (1,0) [0|0] "" Vector__XXX
 SG_ DIR_limitUnitLimp : 4|1@1+ (1,0) [0|0] "" Vector__XXX
 SG_ DIR_limitDeltaFluidTemp : 5|1@1+ (1,0) [0|0] "" Vector__XXX
 SG_ DIR_limitDischargePower : 6|1@1+ (1,0) [0|0] "" Vector__XXX
 SG_ DIR_limitMotorCurrent : 7|1@1+ (1,0) [0|0] "" Vector__XXX
 SG_ DIR_limitMotorVoltage : 8|1@1+ (1,0) [0|0] "" Vector__XXX
 SG_ DIR_limitTCDrive : 9|1@1+ (1,0) [0|0] "" Vector__XXX
 SG_ DIR_limitTCRegen : 10|1@1+ (1,0) [0|0] "" Vector__XXX
 SG_ DIR_limitBaseSpeed : 11|1@1+ (1,0) [0|0] "" Vector__XXX
 SG_ DIR_limitDcCapTemp : 12|1@1+ (1,0) [0|0] "" Vector__XXX
 SG_ DIR_limitMotorSpeed : 13|1@1+ (1,0) [0|0] "" Vector__XXX
 SG_ DIR_limitDiff : 14|1@1+ (1,0) [0|0] "" Vector__XXX
 SG_ DIR_limitUnitGPO : 15|1@1+ (1,0) [0|0] "" Vector__XXX
 SG_ DIR_limitShockTorque : 16|1@1+ (1,0) [0|0] "" Vector__XXX
 SG_ DIR_limitOilPumpFluidTemp : 17|1@1+ (1,0) [0|0] "" Vector__XXX
 SG_ DIR_limitStatorFrequency : 18|1@1+ (1,0) [0|0] "" Vector__XXX
 SG_ DIR_limitClutch : 19|1@1+ (1,0) [0|0] "" Vector__XXX
 SG_ DIR_limitphaseOutBusbarTemp : 20|1@1+ (1,0) [0|0] "" Vector__XXX
 SG_ DIR_limitphaseOutBusBarWeldTemp : 21|1@1+ (1,0) [0|0] "" Vector__XXX
 SG_ DIR_limitphaseOutLugTemp : 22|1@1+ (1,0) [0|0] "" Vector__XXX
 SG_ DIR_limitdcLinkCapTemp : 23|1@1+ (1,0) [0|0] "" Vector__XXX
 SG_ DIR_limitnegDcBusbarTemp : 24|1@1+ (1,0) [0|0] "" Vector__XXX
 SG_ DIR_limitposDcBusbarTemp : 25|1@1+ (1,0) [0|0] "" Vector__XXX
 SG_ DIR_limitRotorTemp : 26|1@1+ (1,0) [0|0] "" Vector__XXX
 SG_ DIR_limithvDcCableTemp : 27|1@1+ (1,0) [0|0] "" Vector__XXX
 SG_ DIR_limitUnitSpinDownLearning : 28|1@1+ (1,0) [0|0] "" Vector__XXX
 SG_ DIR_limitStatorHousingTemp : 29|1@1+ (1,0) [0|0] "" Vector__XXX
 SG_ DIR_statorTempFromResist : 30|8@1+ (1,-40) [0|0] "" Vector__XXX
 SG_ DIR_magnetFluxError : 38|8@1- (8e-05,0) [0|0] "" Vector__XXX
 SG_ DIR_currentLimit : 46|16@1+ (0.1,0) [0|0] "" Vector__XXX
 SG_ DIR_pstgDisableHW3PS : 62|1@1+ (1,0) [0|0] "" Vector__XXX
 SG_ DIR_pstgDisableSW3PS : 63|1@1+ (1,0) [0|0] "" Vector__XXX

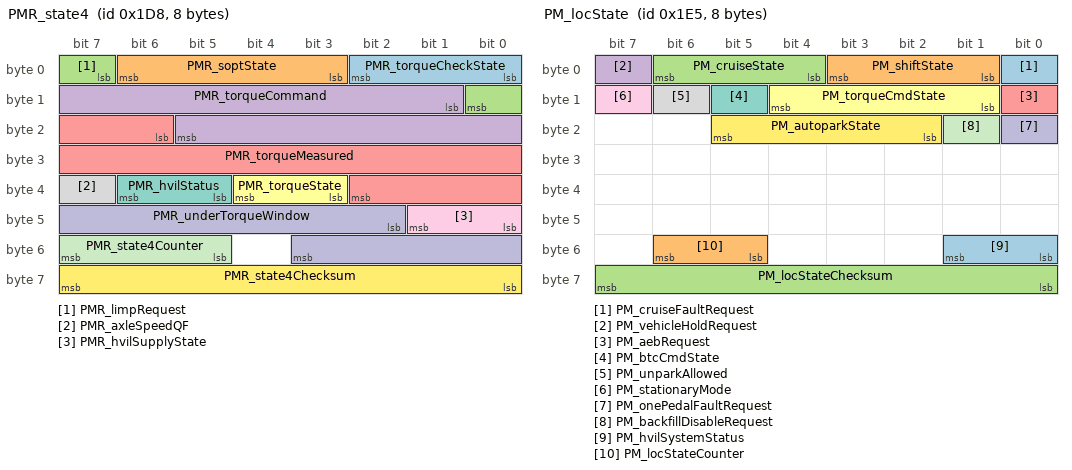
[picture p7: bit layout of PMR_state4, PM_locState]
BO_ 472 PMR_state4: 8 Vector__XXX
 SG_ PMR_torqueCheckState : 0|3@1+ (1,0) [0|0] "" Vector__XXX
 SG_ PMR_soptState : 3|4@1+ (1,0) [0|0] "" Vector__XXX
 SG_ PMR_limpRequest : 7|2@1+ (1,0) [0|0] "" Vector__XXX
 SG_ PMR_torqueCommand : 9|13@1- (2,0) [0|0] "" Vector__XXX
 SG_ PMR_torqueMeasured : 22|13@1- (2,0) [0|0] "" Vector__XXX
 SG_ PMR_torqueState : 35|2@1+ (1,0) [0|0] "" Vector__XXX
 SG_ PMR_hvilStatus : 37|2@1+ (1,0) [0|0] "" Vector__XXX
 SG_ PMR_axleSpeedQF : 39|1@1+ (1,0) [0|0] "" Vector__XXX
 SG_ PMR_hvilSupplyState : 40|2@1+ (1,0) [0|0] "" Vector__XXX
 SG_ PMR_underTorqueWindow : 42|10@1+ (0.005,0) [0|0] "" Vector__XXX
 SG_ PMR_state4Counter : 53|3@1+ (1,0) [0|0] "" Vector__XXX
 SG_ PMR_state4Checksum : 56|8@1+ (1,0) [0|0] "" Vector__XXX

BO_ 473 VCSEC_IsoTpUDPPipeUI: 8 Vector__XXX
 SG_ VCSEC_IsoTpUDPPipeUI0 : 0|8@1+ (1,0) [0|0] "" Vector__XXX
 SG_ VCSEC_IsoTpUDPPipeUI1 : 8|8@1+ (1,0) [0|0] "" Vector__XXX
 SG_ VCSEC_IsoTpUDPPipeUI2 : 16|8@1+ (1,0) [0|0] "" Vector__XXX
 SG_ VCSEC_IsoTpUDPPipeUI3 : 24|8@1+ (1,0) [0|0] "" Vector__XXX
 SG_ VCSEC_IsoTpUDPPipeUI4 : 32|8@1+ (1,0) [0|0] "" Vector__XXX
 SG_ VCSEC_IsoTpUDPPipeUI5 : 40|8@1+ (1,0) [0|0] "" Vector__XXX
 SG_ VCSEC_IsoTpUDPPipeUI6 : 48|8@1+ (1,0) [0|0] "" Vector__XXX
 SG_ VCSEC_IsoTpUDPPipeUI7 : 56|8@1+ (1,0) [0|0] "" Vector__XXX

BO_ 474 VCSEC_IsoTpPipeRemoteUI: 8 Vector__XXX
 SG_ VCSEC_IsoTpRemoteUI0 : 0|8@1+ (1,0) [0|0] "" Vector__XXX
 SG_ VCSEC_IsoTpRemoteUI1 : 8|8@1+ (1,0) [0|0] "" Vector__XXX
 SG_ VCSEC_IsoTpRemoteUI2 : 16|8@1+ (1,0) [0|0] "" Vector__XXX
 SG_ VCSEC_IsoTpRemoteUI3 : 24|8@1+ (1,0) [0|0] "" Vector__XXX
 SG_ VCSEC_IsoTpRemoteUI4 : 32|8@1+ (1,0) [0|0] "" Vector__XXX
 SG_ VCSEC_IsoTpRemoteUI5 : 40|8@1+ (1,0) [0|0] "" Vector__XXX
 SG_ VCSEC_IsoTpRemoteUI6 : 48|8@1+ (1,0) [0|0] "" Vector__XXX
 SG_ VCSEC_IsoTpRemoteUI7 : 56|8@1+ (1,0) [0|0] "" Vector__XXX

BO_ 485 PM_locState: 8 Vector__XXX
 SG_ PM_cruiseFaultRequest : 0|1@1+ (1,0) [0|0] "" Vector__XXX
 SG_ PM_shiftState : 1|3@1+ (1,0) [0|0] "" Vector__XXX
 SG_ PM_cruiseState : 4|3@1+ (1,0) [0|0] "" Vector__XXX
 SG_ PM_vehicleHoldRequest : 7|1@1+ (1,0) [0|0] "" Vector__XXX
 SG_ PM_aebRequest : 8|1@1+ (1,0) [0|0] "" Vector__XXX
 SG_ PM_torqueCmdState : 9|4@1+ (1,0) [0|0] "" Vector__XXX
 SG_ PM_btcCmdState : 13|1@1+ (1,0) [0|0] "" Vector__XXX
 SG_ PM_unparkAllowed : 14|1@1+ (1,0) [0|0] "" Vector__XXX
 SG_ PM_stationaryMode : 15|1@1+ (1,0) [0|0] "" Vector__XXX
 SG_ PM_onePedalFaultRequest : 16|1@1+ (1,0) [0|0] "" Vector__XXX
 SG_ PM_backfillDisableRequest : 17|1@1+ (1,0) [0|0] "" Vector__XXX
 SG_ PM_autoparkState : 18|4@1+ (1,0) [0|0] "" Vector__XXX
 SG_ PM_hvilSystemStatus : 48|2@1+ (1,0) [0|0] "" Vector__XXX
 SG_ PM_locStateCounter : 53|2@1+ (1,0) [0|0] "" Vector__XXX
 SG_ PM_locStateChecksum : 56|8@1+ (1,0) [0|0] "" Vector__XXX

BO_ 504 VCLEFT_intrusionSensorStatus: 8 Vector__XXX
 SG_ VCLEFT_DBG_System_Status : 0|3@1+ (1,0) [0|0] "" Vector__XXX
 SG_ VCLEFT_DBG_Air_Cond_Status : 3|1@1+ (1,0) [0|0] "" Vector__XXX
 SG_ VCLEFT_DBG_Heater_Status : 4|1@1+ (1,0) [0|0] "" Vector__XXX
 SG_ VCLEFT_DBG_Window_Status : 5|1@1+ (1,0) [0|0] "" Vector__XXX
 SG_ VCLEFT_DBG_Suspensions_Status : 6|1@1+ (1,0) [0|0] "" Vector__XXX
 SG_ VCLEFT_DBG_SelfTest_Status : 7|1@1+ (1,0) [0|0] "" Vector__XXX
 SG_ VCLEFT_DBG_Veh_Settings_Status : 8|4@1+ (1,0) [0|0] "" Vector__XXX
 SG_ VCLEFT_DBG_USS_Alarm_Status : 12|1@1+ (1,0) [0|0] "" Vector__XXX
 SG_ VCLEFT_DBG_LM_Alarm_Status : 13|1@1+ (1,0) [0|0] "" Vector__XXX
 SG_ VCLEFT_DBG_Siren_ST_Status : 14|1@1+ (1,0) [0|0] "" Vector__XXX
 SG_ VCLEFT_DBG_Siren_Int_Trigger : 15|1@1+ (1,0) [0|0] "" Vector__XXX
 SG_ VCLEFT_DBG_Invalid_Parameter : 16|1@1+ (1,0) [0|0] "" Vector__XXX
 SG_ VCLEFT_DBG_Siren_is_sounding : 17|1@1+ (1,0) [0|0] "" Vector__XXX
 SG_ VCLEFT_DBG_Reserved_07 : 18|1@1+ (1,0) [0|0] "" Vector__XXX
 SG_ VCLEFT_DBG_Reserved_08 : 19|1@1+ (1,0) [0|0] "" Vector__XXX
 SG_ VCLEFT_DBG_Eeprom_ST_Status : 20|1@1+ (1,0) [0|0] "" Vector__XXX
 SG_ VCLEFT_DBG_USS_SelfTest_Status : 21|1@1+ (1,0) [0|0] "" Vector__XXX
 SG_ VCLEFT_DBG_LM_SelfTest_Status : 22|1@1+ (1,0) [0|0] "" Vector__XXX
 SG_ VCLEFT_DBG_System_Error : 23|1@1+ (1,0) [0|0] "" Vector__XXX
 SG_ VCLEFT_sirenMIA : 24|1@1+ (1,0) [0|0] "" Vector__XXX
 SG_ VCLEFT_intrusionTiltTripped : 25|1@1+ (1,0) [0|0] "" Vector__XXX
 SG_ VCLEFT_intrusionUltraTripped : 26|1@1+ (1,0) [0|0] "" Vector__XXX

BO_ 505 VCSEC_requests: 8 Vector__XXX
 SG_ VCSEC_chargePortRequest : 0|2@1+ (1,0) [0|0] "" Vector__XXX
 SG_ VCSEC_presentHandles : 4|1@1+ (1,0) [0|0] "" Vector__XXX
 SG_ VCSEC_frontLeftClosureRequest : 5|3@1+ (1,0) [0|0] "" Vector__XXX
 SG_ VCSEC_frontRightClosureRequest : 8|3@1+ (1,0) [0|0] "" Vector__XXX
 SG_ VCSEC_rearLeftClosureRequest : 11|3@1+ (1,0) [0|0] "" Vector__XXX
 SG_ VCSEC_rearRightClosureRequest : 14|3@1+ (1,0) [0|0] "" Vector__XXX
 SG_ VCSEC_rearTrunkClosureRequest : 17|3@1+ (1,0) [0|0] "" Vector__XXX
 SG_ VCSEC_frontLeftRequestReason : 20|3@1+ (1,0) [0|0] "" Vector__XXX
 SG_ VCSEC_frontRightRequestReason : 23|3@1+ (1,0) [0|0] "" Vector__XXX
 SG_ VCSEC_rearLeftRequestReason : 26|3@1+ (1,0) [0|0] "" Vector__XXX
 SG_ VCSEC_rearRightRequestReason : 29|3@1+ (1,0) [0|0] "" Vector__XXX
 SG_ VCSEC_rearTrunkRequestReason : 32|3@1+ (1,0) [0|0] "" Vector__XXX
 SG_ VCSEC_rdMapDumpRequested : 35|1@1+ (1,0) [0|0] "" Vector__XXX
 SG_ VCSEC_driveAttemptedWithoutAuth : 36|4@1+ (1,0) [0|0] "" Vector__XXX
 SG_ VCSEC_closeAllStatus : 41|2@1+ (1,0) [0|0] "" Vector__XXX
 SG_ VCSEC_snapshotRequested : 43|4@1+ (1,0) [0|0] "" Vector__XXX
 SG_ VCSEC_chargeportRequestReason : 47|3@1+ (1,0) [0|0] "" Vector__XXX
 SG_ VCSEC_frontTrunkClosureRequest : 51|3@1+ (1,0) [0|0] "" Vector__XXX
 SG_ VCSEC_frontTrunkRequestReason : 54|3@1+ (1,0) [0|0] "" Vector__XXX

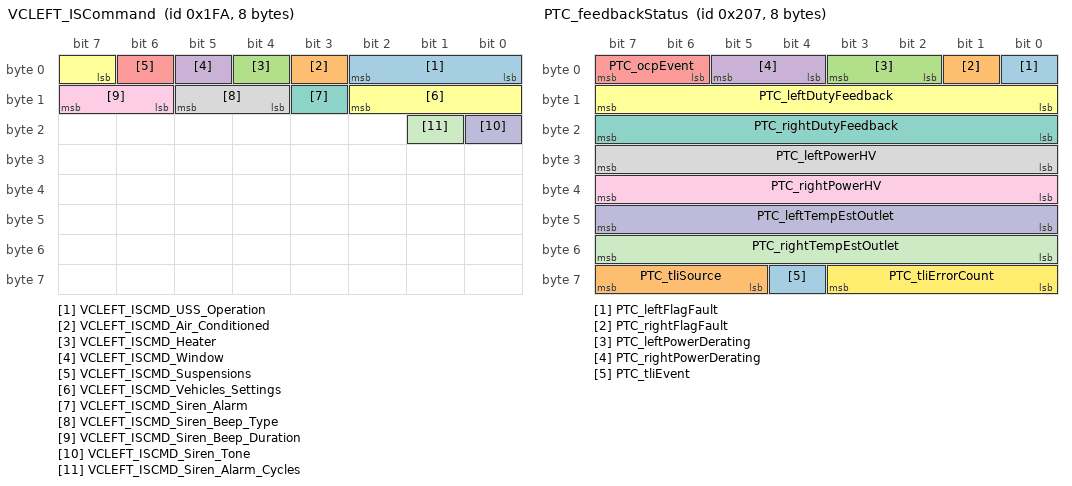
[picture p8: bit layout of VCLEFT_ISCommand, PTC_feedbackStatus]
BO_ 506 VCLEFT_ISCommand: 8 Vector__XXX
 SG_ VCLEFT_ISCMD_USS_Operation : 0|3@1+ (1,0) [0|0] "" Vector__XXX
 SG_ VCLEFT_ISCMD_Air_Conditioned : 3|1@1+ (1,0) [0|0] "" Vector__XXX
 SG_ VCLEFT_ISCMD_Heater : 4|1@1+ (1,0) [0|0] "" Vector__XXX
 SG_ VCLEFT_ISCMD_Window : 5|1@1+ (1,0) [0|0] "" Vector__XXX
 SG_ VCLEFT_ISCMD_Suspensions : 6|1@1+ (1,0) [0|0] "" Vector__XXX
 SG_ VCLEFT_ISCMD_Vehicles_Settings : 7|4@1+ (1,0) [0|0] "" Vector__XXX
 SG_ VCLEFT_ISCMD_Siren_Alarm : 11|1@1+ (1,0) [0|0] "" Vector__XXX
 SG_ VCLEFT_ISCMD_Siren_Beep_Type : 12|2@1+ (1,0) [0|0] "" Vector__XXX
 SG_ VCLEFT_ISCMD_Siren_Beep_Duration : 14|2@1+ (1,0) [0|0] "" Vector__XXX
 SG_ VCLEFT_ISCMD_Siren_Tone : 16|1@1+ (1,0) [0|0] "" Vector__XXX
 SG_ VCLEFT_ISCMD_Siren_Alarm_Cycles : 17|1@1+ (1,0) [0|0] "" Vector__XXX

BO_ 507 VCLEFT_TLCStatus: 8 Vector__XXX
 SG_ VCLEFT_TLCStatusIndex M : 0|2@1+ (1,0) [0|0] "" Vector__XXX
 SG_ VCLEFT_TLCTemperature m1 : 2|8@1- (1,68) [0|0] "" Vector__XXX
 SG_ VCLEFT_TLCLeftTurnCurrent m0 : 8|8@1+ (0.1,0) [0|0] "" Vector__XXX
 SG_ VCLEFT_TLCLeftTurnVoltage m1 : 10|8@1+ (0.1,0) [0|0] "" Vector__XXX
 SG_ VCLEFT_TLCRightTurnCurrent m0 : 16|8@1+ (0.1,0) [0|0] "" Vector__XXX
 SG_ VCLEFT_TLCRightTurnVoltage m1 : 18|8@1+ (0.1,0) [0|0] "" Vector__XXX
 SG_ VCLEFT_TLCTailCurrent m0 : 24|8@1+ (0.1,0) [0|0] "" Vector__XXX
 SG_ VCLEFT_TLCState_LeftTurn m1 : 26|3@1+ (1,0) [0|0] "" Vector__XXX
 SG_ VCLEFT_TLCState_RightTurn m1 : 29|3@1+ (1,0) [0|0] "" Vector__XXX
 SG_ VCLEFT_TLCState_Tail m1 : 32|3@1+ (1,0) [0|0] "" Vector__XXX
 SG_ VCLEFT_TLCStopCurrent m0 : 32|8@1+ (0.1,0) [0|0] "" Vector__XXX
 SG_ VCLEFT_TLCState_Stop m1 : 35|3@1+ (1,0) [0|0] "" Vector__XXX
 SG_ VCLEFT_TLCState_Fog m1 : 38|3@1+ (1,0) [0|0] "" Vector__XXX
 SG_ VCLEFT_TLCFogCurrent m0 : 40|8@1+ (0.1,0) [0|0] "" Vector__XXX
 SG_ VCLEFT_TLCState_Reverse m1 : 41|3@1+ (1,0) [0|0] "" Vector__XXX
 SG_ VCLEFT_TLCReverseCurrent m0 : 48|8@1+ (0.1,0) [0|0] "" Vector__XXX
 SG_ VCLEFT_TLCTotalCurrent m0 : 56|8@1+ (0.1,0) [0|0] "" Vector__XXX

BO_ 508 APP_roadDisturbance: 8 Vector__XXX
 SG_ APP_roadDisturbanceIndex : 0|2@1+ (1,0) [0|0] "" Vector__XXX
 SG_ APP_roadDisturbanceHeight : 2|6@1+ (0.02,-0.64) [0|0] "" Vector__XXX
 SG_ APP_roadDisturbanceX0 : 8|8@1+ (0.5,0) [0|0] "" Vector__XXX
 SG_ APP_roadDisturbanceX1 : 16|8@1+ (0.5,0) [0|0] "" Vector__XXX
 SG_ APP_roadDisturbanceY0 : 24|8@1+ (0.1,-12.8) [0|0] "" Vector__XXX
 SG_ APP_roadDisturbanceY1 : 32|8@1+ (0.1,-12.8) [0|0] "" Vector__XXX
 SG_ APP_suspensionLevelRequest : 40|4@1+ (1,0) [0|0] "" Vector__XXX

BO_ 513 VCFRONT_loggingAndVitals10Hz: 8 Vector__XXX
 SG_ VCFRONT_loggingAndVitals10HzIndex M : 0|3@1+ (1,0) [0|0] "" Vector__XXX
 SG_ VCFRONT_chillerExvFlow m2 : 3|8@1+ (0.5,0) [0|0] "" Vector__XXX
 SG_ VCFRONT_chillerExvFlowTarget m3 : 3|8@1+ (0.5,0) [0|0] "" Vector__XXX
 SG_ VCFRONT_fanDemand m1 : 3|7@1+ (1,0) [0|0] "" Vector__XXX
 SG_ VCFRONT_pumpBatteryRPMActual m0 : 8|8@1+ (30,0) [0|0] "" Vector__XXX
 SG_ VCFRONT_compressorState m1 : 10|2@1+ (1,0) [0|0] "" Vector__XXX
 SG_ VCFRONT_evapExvFlow m2 : 11|8@1+ (0.5,0) [0|0] "" Vector__XXX
 SG_ VCFRONT_evapExvFlowTarget m3 : 11|8@1+ (0.5,0) [0|0] "" Vector__XXX
 SG_ VCFRONT_compDemandEvap m1 : 12|7@1+ (1,0) [0|0] "" Vector__XXX
 SG_ VCFRONT_pumpPowertrainRPMActual m0 : 16|8@1+ (30,0) [0|0] "" Vector__XXX
 SG_ VCFRONT_exvState m1 : 19|4@1+ (1,0) [0|0] "" Vector__XXX
 SG_ VCFRONT_recircExvFlow m2 : 19|8@1+ (0.5,0) [0|0] "" Vector__XXX
 SG_ VCFRONT_recircExvFlowTarget m3 : 19|8@1+ (0.5,0) [0|0] "" Vector__XXX
 SG_ VCFRONT_solenoidEvapState m1 : 23|2@1+ (1,0) [0|0] "" Vector__XXX
 SG_ VCFRONT_radiatorFanRPMActual m0 : 24|8@1+ (40,0) [0|0] "" Vector__XXX
 SG_ VCFRONT_compDemandChiller m1 : 25|7@1+ (1,0) [0|0] "" Vector__XXX
 SG_ VCFRONT_lccExvFlow m2 : 27|8@1+ (0.5,0) [0|0] "" Vector__XXX
 SG_ VCFRONT_lccExvFlowTarget m3 : 27|8@1+ (0.5,0) [0|0] "" Vector__XXX
 SG_ VCFRONT_coolantValveMode m1 : 32|2@1+ (1,0) [0|0] "" Vector__XXX
 SG_ VCFRONT_exvFlowTarget m0 : 32|8@1+ (0.5,0) [0|0] "" Vector__XXX
 SG_ VCFRONT_compFaultSeverity m1 : 34|2@1+ (1,0) [0|0] "" Vector__XXX
 SG_ VCFRONT_cclExvFlow m2 : 35|8@1+ (0.5,0) [0|0] "" Vector__XXX
 SG_ VCFRONT_cclExvFlowTarget m3 : 35|8@1+ (0.5,0) [0|0] "" Vector__XXX
 SG_ VCFRONT_solenoidEngaged m1 : 36|1@1+ (1,0) [0|0] "" Vector__XXX
 SG_ VCFRONT_hpHighSideHX m1 : 37|2@1+ (1,0) [0|0] "" Vector__XXX
 SG_ VCFRONT_hpLowSideHX m1 : 39|2@1+ (1,0) [0|0] "" Vector__XXX
 SG_ VCFRONT_activeLouverOpenPosTarg m0 : 40|7@1+ (1,0) [0|0] "" Vector__XXX
 SG_ VCFRONT_hpDominantLoad m1 : 41|3@1+ (1,0) [0|0] "" Vector__XXX
 SG_ VCFRONT_ccrExvFlow m2 : 43|8@1+ (0.5,0) [0|0] "" Vector__XXX
 SG_ VCFRONT_ccrExvFlowTarget m3 : 43|8@1+ (0.5,0) [0|0] "" Vector__XXX
 SG_ VCFRONT_hpBlendType m1 : 44|2@1+ (1,0) [0|0] "" Vector__XXX
 SG_ VCFRONT_hpQuietModeEnabled m1 : 46|1@1+ (1,0) [0|0] "" Vector__XXX
 SG_ VCFRONT_hpCabinLoadType m1 : 47|2@1+ (1,0) [0|0] "" Vector__XXX
 SG_ VCFRONT_pressureRefrigLiquid m0 : 47|9@1+ (0.08,0) [0|0] "" Vector__XXX
 SG_ VCFRONT_hpBatteryLoadType m1 : 49|2@1+ (1,0) [0|0] "" Vector__XXX
 SG_ VCFRONT_chillerExvState m2 : 51|4@1+ (1,0) [0|0] "" Vector__XXX
 SG_ VCFRONT_hpReqCoolantMode m1 : 51|3@1+ (1,0) [0|0] "" Vector__XXX
 SG_ VCFRONT_lccExvState m3 : 51|4@1+ (1,0) [0|0] "" Vector__XXX
 SG_ VCFRONT_hpReqTransScavenge m1 : 54|1@1+ (1,0) [0|0] "" Vector__XXX
 SG_ VCFRONT_cclExvState m3 : 55|4@1+ (1,0) [0|0] "" Vector__XXX
 SG_ VCFRONT_compLiqPumpOutState m1 : 55|3@1+ (1,0) [0|0] "" Vector__XXX
 SG_ VCFRONT_evapExvState m2 : 55|4@1+ (1,0) [0|0] "" Vector__XXX
 SG_ VCFRONT_compSleepRequest m0 : 56|1@1+ (1,0) [0|0] "" Vector__XXX
 SG_ VCFRONT_thermalHvPowerBudget m0 : 57|7@1+ (0.2,0) [0|0] "" Vector__XXX
 SG_ VCFRONT_frunkStateDBG m1 : 58|4@1+ (1,0) [0|0] "" Vector__XXX
 SG_ VCFRONT_ccrExvState m3 : 59|4@1+ (1,0) [0|0] "" Vector__XXX
 SG_ VCFRONT_recircExvState m2 : 59|4@1+ (1,0) [0|0] "" Vector__XXX
 SG_ VCFRONT_frunkSwitchGroupState m1 : 62|2@1+ (1,0) [0|0] "" Vector__XXX

BO_ 516 PCS_chgStatus: 8 Vector__XXX
 SG_ PCS_chgMainState : 0|4@1+ (1,0) [0|0] "" Vector__XXX
 SG_ PCS_powerTransferStatus : 4|2@1+ (1,0) [0|0] "" Vector__XXX
 SG_ PCS_gridConfig : 6|2@1+ (1,0) [0|0] "" Vector__XXX
 SG_ PCS_chgPHAEnable : 8|1@1+ (1,0) [0|0] "" Vector__XXX
 SG_ PCS_chgPHBEnable : 9|1@1+ (1,0) [0|0] "" Vector__XXX
 SG_ PCS_hvInletConductorEnergizedAc : 10|1@1+ (1,0) [0|0] "" Vector__XXX
 SG_ PCS_chgHighPowerActive : 11|1@1+ (1,0) [0|0] "" Vector__XXX
 SG_ PCS_chgPHCEnable : 12|1@1+ (1,0) [0|0] "" Vector__XXX
 SG_ PCS_chgInstantAcPowerAvailable : 16|8@1+ (0.1,0) [0|0] "" Vector__XXX
 SG_ PCS_chgMaxAcPowerAvailable : 24|8@1+ (0.1,0) [0|0] "" Vector__XXX
 SG_ PCS_chgPHALineCurrentRequest : 32|8@1+ (0.1,0) [0|0] "" Vector__XXX
 SG_ PCS_chgPHBLineCurrentRequest : 40|8@1+ (0.1,0) [0|0] "" Vector__XXX
 SG_ PCS_chgPHCLineCurrentRequest : 48|8@1+ (0.1,0) [0|0] "" Vector__XXX
 SG_ PCS_chgPwmEnableLine : 56|1@1+ (1,0) [0|0] "" Vector__XXX
 SG_ PCS_powerTransferShutdownRequest : 57|2@1+ (1,0) [0|0] "" Vector__XXX
 SG_ PCS_hwVariantType : 59|2@1+ (1,0) [0|0] "" Vector__XXX
 SG_ PCS_dcacBidirectionalAllowed : 61|1@1+ (1,0) [0|0] "" Vector__XXX

BO_ 519 PTC_feedbackStatus: 8 Vector__XXX
 SG_ PTC_leftFlagFault : 0|1@1+ (1,0) [0|0] "" Vector__XXX
 SG_ PTC_rightFlagFault : 1|1@1+ (1,0) [0|0] "" Vector__XXX
 SG_ PTC_leftPowerDerating : 2|2@1+ (1,0) [0|0] "" Vector__XXX
 SG_ PTC_rightPowerDerating : 4|2@1+ (1,0) [0|0] "" Vector__XXX
 SG_ PTC_ocpEvent : 6|2@1+ (1,0) [0|0] "" Vector__XXX
 SG_ PTC_leftDutyFeedback : 8|8@1+ (0.5,0) [0|0] "" Vector__XXX
 SG_ PTC_rightDutyFeedback : 16|8@1+ (0.5,0) [0|0] "" Vector__XXX
 SG_ PTC_leftPowerHV : 24|8@1+ (30,0) [0|0] "" Vector__XXX
 SG_ PTC_rightPowerHV : 32|8@1+ (30,0) [0|0] "" Vector__XXX
 SG_ PTC_leftTempEstOutlet : 40|8@1+ (1,-40) [0|0] "" Vector__XXX
 SG_ PTC_rightTempEstOutlet : 48|8@1+ (1,-40) [0|0] "" Vector__XXX
 SG_ PTC_tliErrorCount : 56|4@1+ (1,0) [0|0] "" Vector__XXX
 SG_ PTC_tliEvent : 60|1@1+ (1,0) [0|0] "" Vector__XXX
 SG_ PTC_tliSource : 61|3@1+ (1,0) [0|0] "" Vector__XXX

BO_ 522 HVP_contactorState: 8 Vector__XXX
 SG_ HVP_packContNegativeState : 0|3@1+ (1,0) [0|0] "" Vector__XXX
 SG_ HVP_packContPositiveState : 3|3@1+ (1,0) [0|0] "" Vector__XXX
 SG_ HVP_fcContPositiveAuxOpen : 6|1@1+ (1,0) [0|0] "" Vector__XXX
 SG_ HVP_fcContNegativeAuxOpen : 7|1@1+ (1,0) [0|0] "" Vector__XXX
 SG_ HVP_packContactorSetState : 8|4@1+ (1,0) [0|0] "" Vector__XXX
 SG_ HVP_fcContNegativeState : 12|3@1+ (1,0) [0|0] "" Vector__XXX
 SG_ HVP_contactorsBlocked : 15|1@1+ (1,0) [0|0] "" Vector__XXX
 SG_ HVP_fcContPositiveState : 16|3@1+ (1,0) [0|0] "" Vector__XXX
 SG_ HVP_fcContactorSetState : 19|4@1+ (1,0) [0|0] "" Vector__XXX
 SG_ HVP_fcCtrsRequestStatus : 24|2@1+ (1,0) [0|0] "" Vector__XXX
 SG_ HVP_fcCtrsResetRequestRequired : 26|1@1+ (1,0) [0|0] "" Vector__XXX
 SG_ HVP_fcCtrsOpenNowRequested : 27|1@1+ (1,0) [0|0] "" Vector__XXX
 SG_ HVP_fcCtrsOpenRequested : 28|1@1+ (1,0) [0|0] "" Vector__XXX
 SG_ HVP_fcCtrsClosingAllowed : 29|1@1+ (1,0) [0|0] "" Vector__XXX
 SG_ HVP_packCtrsRequestStatus : 30|2@1+ (1,0) [0|0] "" Vector__XXX
 SG_ HVP_packCtrsResetRequestRequired : 32|1@1+ (1,0) [0|0] "" Vector__XXX
 SG_ HVP_packCtrsOpenNowRequested : 33|1@1+ (1,0) [0|0] "" Vector__XXX
 SG_ HVP_packCtrsOpenRequested : 34|1@1+ (1,0) [0|0] "" Vector__XXX
 SG_ HVP_packCtrsClosingAllowed : 35|1@1+ (1,0) [0|0] "" Vector__XXX
 SG_ HVP_dcLinkAllowedToEnergize : 36|1@1+ (1,0) [0|0] "" Vector__XXX
 SG_ HVP_pyroTestInProgress : 37|1@1+ (1,0) [0|0] "" Vector__XXX
 SG_ HVP_hvilDiag : 40|4@1+ (1,0) [0|0] "" Vector__XXX
 SG_ HVP_fcLinkAllowedToEnergize : 44|2@1+ (1,0) [0|0] "" Vector__XXX

BO_ 523 TAS_axleData: 8 Vector__XXX
 SG_ TAS_axleIndex M : 0|1@1+ (1,0) [0|0] "" Vector__XXX
 SG_ TAS_rawHeightFL m0 : 4|10@1+ (1,-512) [0|0] "" Vector__XXX
 SG_ TAS_rawHeightRL m1 : 4|10@1+ (1,-512) [0|0] "" Vector__XXX
 SG_ TAS_staticHeightEstimateFL m0 : 14|10@1+ (1,-512) [0|0] "" Vector__XXX
 SG_ TAS_staticHeightEstimateRL m1 : 14|10@1+ (1,-512) [0|0] "" Vector__XXX
 SG_ TAS_componentPressureFL m0 : 24|8@1+ (0.1,0) [0|0] "" Vector__XXX
 SG_ TAS_componentPressureRL m1 : 24|8@1+ (0.1,0) [0|0] "" Vector__XXX
 SG_ TAS_rawHeightFR m0 : 32|10@1+ (1,-512) [0|0] "" Vector__XXX
 SG_ TAS_rawHeightRR m1 : 32|10@1+ (1,-512) [0|0] "" Vector__XXX
 SG_ TAS_staticHeightEstimateFR m0 : 42|10@1+ (1,-512) [0|0] "" Vector__XXX
 SG_ TAS_staticHeightEstimateRR m1 : 42|10@1+ (1,-512) [0|0] "" Vector__XXX
 SG_ TAS_componentPressureFR m0 : 52|8@1+ (0.1,0) [0|0] "" Vector__XXX
 SG_ TAS_componentPressureRR m1 : 52|8@1+ (0.1,0) [0|0] "" Vector__XXX

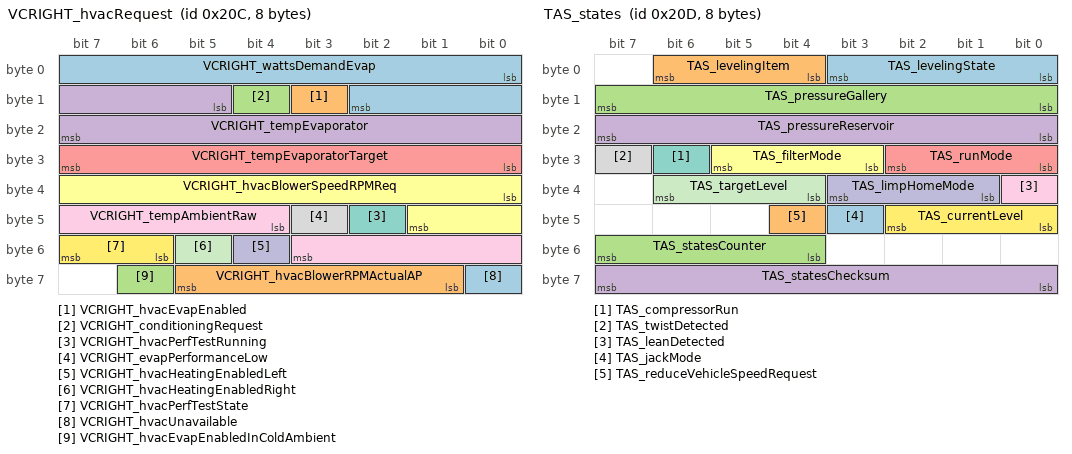
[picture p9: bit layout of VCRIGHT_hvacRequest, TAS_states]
BO_ 524 VCRIGHT_hvacRequest: 8 Vector__XXX
 SG_ VCRIGHT_wattsDemandEvap : 0|11@1+ (5,0) [0|0] "" Vector__XXX
 SG_ VCRIGHT_hvacEvapEnabled : 11|1@1+ (1,0) [0|0] "" Vector__XXX
 SG_ VCRIGHT_conditioningRequest : 12|1@1+ (1,0) [0|0] "" Vector__XXX
 SG_ VCRIGHT_tempEvaporator : 13|11@1+ (0.1,-40) [0|0] "" Vector__XXX
 SG_ VCRIGHT_tempEvaporatorTarget : 24|8@1+ (0.2,0) [0|0] "" Vector__XXX
 SG_ VCRIGHT_hvacBlowerSpeedRPMReq : 32|10@1+ (5,0) [0|0] "" Vector__XXX
 SG_ VCRIGHT_hvacPerfTestRunning : 42|1@1+ (1,0) [0|0] "" Vector__XXX
 SG_ VCRIGHT_evapPerformanceLow : 43|1@1+ (1,0) [0|0] "" Vector__XXX
 SG_ VCRIGHT_tempAmbientRaw : 44|8@1+ (0.5,-40) [0|0] "" Vector__XXX
 SG_ VCRIGHT_hvacHeatingEnabledLeft : 52|1@1+ (1,0) [0|0] "" Vector__XXX
 SG_ VCRIGHT_hvacHeatingEnabledRight : 53|1@1+ (1,0) [0|0] "" Vector__XXX
 SG_ VCRIGHT_hvacPerfTestState : 54|2@1+ (1,0) [0|0] "" Vector__XXX
 SG_ VCRIGHT_hvacUnavailable : 56|1@1+ (1,0) [0|0] "" Vector__XXX
 SG_ VCRIGHT_hvacBlowerRPMActualAP : 57|5@1+ (200,0) [0|0] "" Vector__XXX
 SG_ VCRIGHT_hvacEvapEnabledInColdAmbient : 62|1@1+ (1,0) [0|0] "" Vector__XXX

BO_ 525 TAS_states: 8 Vector__XXX
 SG_ TAS_levelingState : 0|4@1+ (1,0) [0|0] "" Vector__XXX
 SG_ TAS_levelingItem : 4|3@1+ (1,0) [0|0] "" Vector__XXX
 SG_ TAS_pressureGallery : 8|8@1+ (0.1,0) [0|0] "" Vector__XXX
 SG_ TAS_pressureReservoir : 16|8@1+ (0.1,0) [0|0] "" Vector__XXX
 SG_ TAS_runMode : 24|3@1+ (1,0) [0|0] "" Vector__XXX
 SG_ TAS_filterMode : 27|3@1+ (1,0) [0|0] "" Vector__XXX
 SG_ TAS_compressorRun : 30|1@1+ (1,0) [0|0] "" Vector__XXX
 SG_ TAS_twistDetected : 31|1@1+ (1,0) [0|0] "" Vector__XXX
 SG_ TAS_leanDetected : 32|1@1+ (1,0) [0|0] "" Vector__XXX
 SG_ TAS_limpHomeMode : 33|3@1+ (1,0) [0|0] "" Vector__XXX
 SG_ TAS_targetLevel : 36|3@1+ (1,0) [0|0] "" Vector__XXX
 SG_ TAS_currentLevel : 40|3@1+ (1,0) [0|0] "" Vector__XXX
 SG_ TAS_jackMode : 43|1@1+ (1,0) [0|0] "" Vector__XXX
 SG_ TAS_reduceVehicleSpeedRequest : 44|1@1+ (1,0) [0|0] "" Vector__XXX
 SG_ TAS_statesCounter : 52|4@1+ (1,0) [0|0] "" Vector__XXX
 SG_ TAS_statesChecksum : 56|8@1+ (1,0) [0|0] "" Vector__XXX

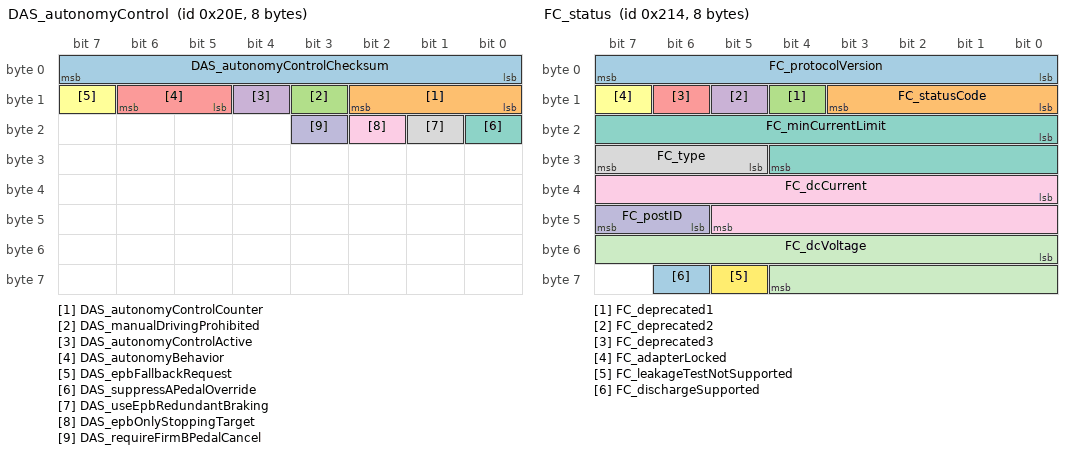
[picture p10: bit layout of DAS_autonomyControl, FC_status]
BO_ 526 DAS_autonomyControl: 8 Vector__XXX
 SG_ DAS_autonomyControlChecksum : 0|8@1+ (1,0) [0|0] "" Vector__XXX
 SG_ DAS_autonomyControlCounter : 8|3@1+ (1,0) [0|0] "" Vector__XXX
 SG_ DAS_manualDrivingProhibited : 11|1@1+ (1,0) [0|0] "" Vector__XXX
 SG_ DAS_autonomyControlActive : 12|1@1+ (1,0) [0|0] "" Vector__XXX
 SG_ DAS_autonomyBehavior : 13|2@1+ (1,0) [0|0] "" Vector__XXX
 SG_ DAS_epbFallbackRequest : 15|1@1+ (1,0) [0|0] "" Vector__XXX
 SG_ DAS_suppressAPedalOverride : 16|1@1+ (1,0) [0|0] "" Vector__XXX
 SG_ DAS_useEpbRedundantBraking : 17|1@1+ (1,0) [0|0] "" Vector__XXX
 SG_ DAS_epbOnlyStoppingTarget : 18|1@1+ (1,0) [0|0] "" Vector__XXX
 SG_ DAS_requireFirmBPedalCancel : 19|1@1+ (1,0) [0|0] "" Vector__XXX

BO_ 529 RCM_status: 8 Vector__XXX
 SG_ RCM_statusChecksum : 0|8@1+ (1,0) [0|0] "" Vector__XXX
 SG_ RCM_statusCounter : 8|4@1+ (1,0) [0|0] "" Vector__XXX
 SG_ RCM_armStatus : 12|2@1+ (1,0) [0|0] "" Vector__XXX
 SG_ RCM_warningIndicatorState : 14|2@1+ (1,0) [0|0] "" Vector__XXX
 SG_ RCM_passAirbagIndicatorRequest : 16|2@1+ (1,0) [0|0] "" Vector__XXX
 SG_ RCM_airbagCutoffStatus : 18|2@1+ (1,0) [0|0] "" Vector__XXX
 SG_ RCM_alrSwitchStatus : 20|2@1+ (1,0) [0|0] "" Vector__XXX
 SG_ RCM_vinLearnFlag : 22|2@1+ (1,0) [0|0] "" Vector__XXX
 SG_ RCM_seatTrackPositionDrvr : 24|2@1+ (1,0) [0|0] "" Vector__XXX
 SG_ RCM_seatTrackPositionPass : 26|2@1+ (1,0) [0|0] "" Vector__XXX
 SG_ RCM_edr1State : 28|2@1+ (1,0) [0|0] "" Vector__XXX
 SG_ RCM_edr2State : 30|2@1+ (1,0) [0|0] "" Vector__XXX
 SG_ RCM_keepPowerReason : 32|4@1+ (1,0) [0|0] "" Vector__XXX
 SG_ RCM_imuOffsetLearnState : 36|2@1+ (1,0) [0|0] "" Vector__XXX
 SG_ RCM_edr3State : 38|2@1+ (1,0) [0|0] "" Vector__XXX
 SG_ RCM_driverOrientationInitStatus : 40|3@1+ (1,0) [0|0] "" Vector__XXX
 SG_ RCM_occupantClassificationSource : 43|1@1+ (1,0) [0|0] "" Vector__XXX
 SG_ RCM_pedProEDR1State : 44|2@1+ (1,0) [0|0] "" Vector__XXX
 SG_ RCM_pedProEDR2State : 46|2@1+ (1,0) [0|0] "" Vector__XXX

BO_ 530 BMS_status: 8 Vector__XXX
 SG_ BMS_hvacPowerRequest : 0|1@1+ (1,0) [0|0] "" Vector__XXX
 SG_ BMS_notEnoughPowerForDrive : 1|1@1+ (1,0) [0|0] "" Vector__XXX
 SG_ BMS_notEnoughPowerForSupport : 2|1@1+ (1,0) [0|0] "" Vector__XXX
 SG_ BMS_preconditionAllowed : 3|1@1+ (1,0) [0|0] "" Vector__XXX
 SG_ BMS_updateAllowed : 4|1@1+ (1,0) [0|0] "" Vector__XXX
 SG_ BMS_cpMiaOnHvs : 5|1@1+ (1,0) [0|0] "" Vector__XXX
 SG_ BMS_pcsPwmEnabled : 6|1@1+ (1,0) [0|0] "" Vector__XXX
 SG_ BMS_contactorState : 8|3@1+ (1,0) [0|0] "" Vector__XXX
 SG_ BMS_userChargeStatus : 11|3@1+ (1,0) [0|0] "" Vector__XXX
 SG_ BMS_batteryInputPower : 14|16@1+ (0.05,0) [0|0] "" Vector__XXX
 SG_ BMS_chargeRequest : 30|1@1+ (1,0) [0|0] "" Vector__XXX
 SG_ BMS_state : 32|4@1+ (1,0) [0|0] "" Vector__XXX
 SG_ BMS_diLimpRequest : 36|1@1+ (1,0) [0|0] "" Vector__XXX
 SG_ BMS_okToShipByAir : 37|1@1+ (1,0) [0|0] "" Vector__XXX
 SG_ BMS_okToShipByLand : 38|1@1+ (1,0) [0|0] "" Vector__XXX
 SG_ BMS_chgPowerAvailable : 39|12@1+ (0.125,0) [0|0] "" Vector__XXX
 SG_ BMS_chargeRetryCount : 52|3@1+ (1,0) [0|0] "" Vector__XXX
 SG_ BMS_conditioningRequest : 55|1@1+ (1,0) [0|0] "" Vector__XXX
 SG_ BMS_smStateRequest : 56|4@1+ (1,0) [0|0] "" Vector__XXX
 SG_ BMS_hvState : 60|3@1+ (1,0) [0|0] "" Vector__XXX

BO_ 531 UI_cruiseControl: 8 Vector__XXX
 SG_ UI_cruiseSpeedCommand : 0|3@1+ (1,0) [0|0] "" Vector__XXX
 SG_ UI_smartSummonRequest : 3|1@1+ (1,0) [0|0] "" Vector__XXX
 SG_ UI_cruiseControlCounter : 4|4@1+ (1,0) [0|0] "" Vector__XXX
 SG_ UI_cruiseControlChecksum : 8|8@1+ (1,0) [0|0] "" Vector__XXX

BO_ 532 FC_status: 8 Vector__XXX
 SG_ FC_protocolVersion : 0|8@1+ (1,0) [0|0] "" Vector__XXX
 SG_ FC_statusCode : 8|4@1+ (1,0) [0|0] "" Vector__XXX
 SG_ FC_deprecated1 : 12|1@1+ (1,0) [0|0] "" Vector__XXX
 SG_ FC_deprecated2 : 13|1@1+ (1,0) [0|0] "" Vector__XXX
 SG_ FC_deprecated3 : 14|1@1+ (1,0) [0|0] "" Vector__XXX
 SG_ FC_adapterLocked : 15|1@1+ (1,0) [0|0] "" Vector__XXX
 SG_ FC_minCurrentLimit : 16|13@1+ (0.1,0) [0|0] "" Vector__XXX
 SG_ FC_type : 29|3@1+ (1,0) [0|0] "" Vector__XXX
 SG_ FC_dcCurrent : 32|14@1- (0.0732421875,0) [0|0] "" Vector__XXX
 SG_ FC_postID : 46|2@1+ (1,0) [0|0] "" Vector__XXX
 SG_ FC_dcVoltage : 48|13@1+ (0.07324218755,0) [0|0] "" Vector__XXX
 SG_ FC_leakageTestNotSupported : 61|1@1+ (1,0) [0|0] "" Vector__XXX
 SG_ FC_dischargeSupported : 62|1@1+ (1,0) [0|0] "" Vector__XXX

BO_ 533 FC_status2: 8 Vector__XXX
 SG_ FC_externalIsolationResistance : 0|8@1+ (40,0) [0|0] "" Vector__XXX

BO_ 535 FC_status3: 8 Vector__XXX
 SG_ FC_status3DataSelect M : 0|7@1+ (1,0) [0|0] "" Vector__XXX
 SG_ FC_status3DummySig : 7|1@1+ (1,0) [0|0] "" Vector__XXX
 SG_ FC_billingEnergy m1 : 8|16@1+ (0.0152590219,0) [0|0] "" Vector__XXX
 SG_ FC_class m0 : 8|8@1+ (1,0) [0|0] "" Vector__XXX
 SG_ FC_brand m0 : 16|4@1+ (1,0) [0|0] "" Vector__XXX
 SG_ FC_coolingType m0 : 20|4@1+ (1,0) [0|0] "" Vector__XXX
 SG_ FC_evseDeratingReason m1 : 24|5@1+ (1,0) [0|0] "" Vector__XXX
 SG_ FC_uiStopType m0 : 24|4@1+ (1,0) [0|0] "" Vector__XXX
 SG_ FC_emergencyShutdownSupported m0 : 28|1@1+ (1,0) [0|0] "" Vector__XXX
 SG_ FC_evRelocationRecommended m1 : 29|1@1+ (1,0) [0|0] "" Vector__XXX
 SG_ FC_generation m0 : 32|8@1+ (1,0) [0|0] "" Vector__XXX

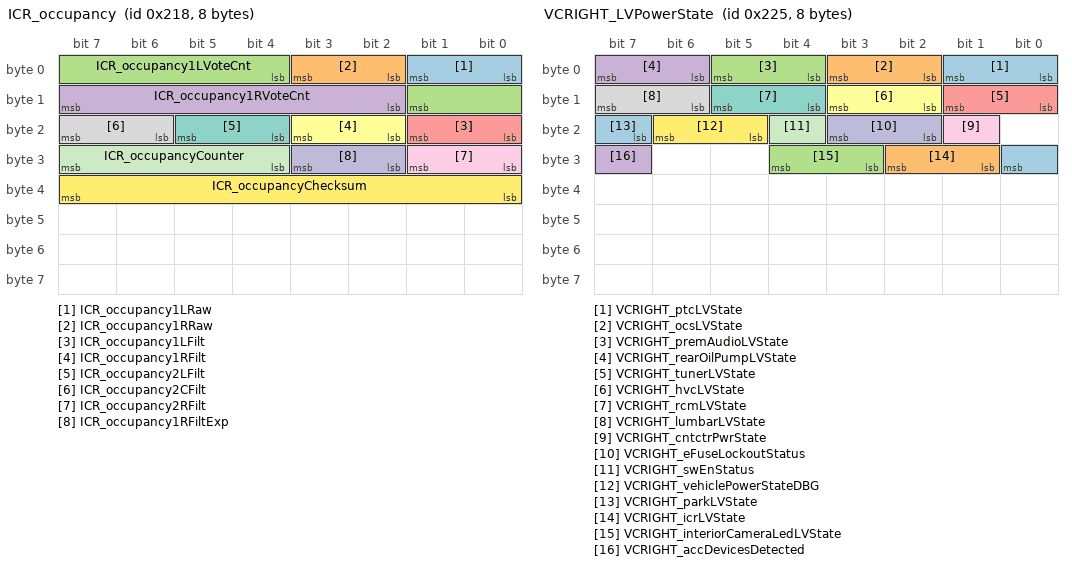
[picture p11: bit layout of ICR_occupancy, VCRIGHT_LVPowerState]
BO_ 536 ICR_occupancy: 8 Vector__XXX
 SG_ ICR_occupancy1LRaw : 0|2@1+ (1,0) [0|0] "" Vector__XXX
 SG_ ICR_occupancy1RRaw : 2|2@1+ (1,0) [0|0] "" Vector__XXX
 SG_ ICR_occupancy1LVoteCnt : 4|6@1- (1,0) [0|0] "" Vector__XXX
 SG_ ICR_occupancy1RVoteCnt : 10|6@1- (1,0) [0|0] "" Vector__XXX
 SG_ ICR_occupancy1LFilt : 16|2@1+ (1,0) [0|0] "" Vector__XXX
 SG_ ICR_occupancy1RFilt : 18|2@1+ (1,0) [0|0] "" Vector__XXX
 SG_ ICR_occupancy2LFilt : 20|2@1+ (1,0) [0|0] "" Vector__XXX
 SG_ ICR_occupancy2CFilt : 22|2@1+ (1,0) [0|0] "" Vector__XXX
 SG_ ICR_occupancy2RFilt : 24|2@1+ (1,0) [0|0] "" Vector__XXX
 SG_ ICR_occupancy1RFiltExp : 26|2@1+ (1,0) [0|0] "" Vector__XXX
 SG_ ICR_occupancyCounter : 28|4@1+ (1,0) [0|0] "" Vector__XXX
 SG_ ICR_occupancyChecksum : 32|8@1+ (1,0) [0|0] "" Vector__XXX

BO_ 537 VCSEC_TPMSData: 8 Vector__XXX
 SG_ VCSEC_TPMSDataIndex M : 0|3@1+ (1,0) [0|0] "" Vector__XXX
 SG_ VCSEC_TPMSAutonomyStatus m5 : 3|2@1+ (1,0) [0|0] "" Vector__XXX
 SG_ VCSEC_TPMSCapabilityPressureInAdv0 m0 : 3|1@1+ (1,0) [0|0] "" Vector__XXX
 SG_ VCSEC_TPMSCapabilityPressureInAdv1 m1 : 3|1@1+ (1,0) [0|0] "" Vector__XXX
 SG_ VCSEC_TPMSCapabilityPressureInAdv2 m2 : 3|1@1+ (1,0) [0|0] "" Vector__XXX
 SG_ VCSEC_TPMSCapabilityPressureInAdv3 m3 : 3|1@1+ (1,0) [0|0] "" Vector__XXX
 SG_ VCSEC_TPMSCapabilityConfigurablePressure0 m0 : 4|1@1+ (1,0) [0|0] "" Vector__XXX
 SG_ VCSEC_TPMSCapabilityConfigurablePressure1 m1 : 4|1@1+ (1,0) [0|0] "" Vector__XXX
 SG_ VCSEC_TPMSCapabilityConfigurablePressure2 m2 : 4|1@1+ (1,0) [0|0] "" Vector__XXX
 SG_ VCSEC_TPMSCapabilityConfigurablePressure3 m3 : 4|1@1+ (1,0) [0|0] "" Vector__XXX
 SG_ VCSEC_TPMSAutonomyStatusMIATimeS m5 : 5|9@1+ (1,0) [0|0] "" Vector__XXX
 SG_ VCSEC_TPMSPressureRateOfChange0 m0 : 5|10@1- (0.02,0) [0|0] "" Vector__XXX
 SG_ VCSEC_TPMSPressureRateOfChange1 m1 : 5|10@1- (0.02,0) [0|0] "" Vector__XXX
 SG_ VCSEC_TPMSPressureRateOfChange2 m2 : 5|10@1- (0.02,0) [0|0] "" Vector__XXX
 SG_ VCSEC_TPMSPressureRateOfChange3 m3 : 5|10@1- (0.02,0) [0|0] "" Vector__XXX
 SG_ VCSEC_TPMSRecommendedColdPressureFront m4 : 8|8@1+ (0.025,0) [0|0] "" Vector__XXX
 SG_ VCSEC_TPMSPressure0 m0 : 15|9@1+ (0.025,0) [0|0] "" Vector__XXX
 SG_ VCSEC_TPMSPressure1 m1 : 15|9@1+ (0.025,0) [0|0] "" Vector__XXX
 SG_ VCSEC_TPMSPressure2 m2 : 15|9@1+ (0.025,0) [0|0] "" Vector__XXX
 SG_ VCSEC_TPMSPressure3 m3 : 15|9@1+ (0.025,0) [0|0] "" Vector__XXX
 SG_ VCSEC_TPMSLastKnownPressureFL m5 : 16|8@1+ (0.025,0) [0|0] "" Vector__XXX
 SG_ VCSEC_TPMSRecommendedColdPressureRear m4 : 16|8@1+ (0.025,0) [0|0] "" Vector__XXX
 SG_ VCSEC_TPMSFeature0 m4 : 24|3@1+ (1,0) [0|0] "" Vector__XXX
 SG_ VCSEC_TPMSLastKnownPressureFR m5 : 24|8@1+ (0.025,0) [0|0] "" Vector__XXX
 SG_ VCSEC_TPMSTemperature0 m0 : 24|8@1+ (1,-40) [0|0] "" Vector__XXX
 SG_ VCSEC_TPMSTemperature1 m1 : 24|8@1+ (1,-40) [0|0] "" Vector__XXX
 SG_ VCSEC_TPMSTemperature2 m2 : 24|8@1+ (1,-40) [0|0] "" Vector__XXX
 SG_ VCSEC_TPMSTemperature3 m3 : 24|8@1+ (1,-40) [0|0] "" Vector__XXX
 SG_ VCSEC_TPMSFeature1 m4 : 27|3@1+ (1,0) [0|0] "" Vector__XXX
 SG_ VCSEC_TPMSBatVoltage0 m0 : 32|8@1+ (0.01,1.5) [0|0] "" Vector__XXX
 SG_ VCSEC_TPMSBatVoltage1 m1 : 32|8@1+ (0.01,1.5) [0|0] "" Vector__XXX
 SG_ VCSEC_TPMSBatVoltage2 m2 : 32|8@1+ (0.01,1.5) [0|0] "" Vector__XXX
 SG_ VCSEC_TPMSBatVoltage3 m3 : 32|8@1+ (0.01,1.5) [0|0] "" Vector__XXX
 SG_ VCSEC_TPMSFeature0Count m4 : 32|4@1+ (1,0) [0|0] "" Vector__XXX
 SG_ VCSEC_TPMSLastKnownPressureRL m5 : 32|8@1+ (0.025,0) [0|0] "" Vector__XXX
 SG_ VCSEC_TPMSFeature0TimeS m4 : 36|11@1+ (1,0) [0|0] "" Vector__XXX
 SG_ VCSEC_TPMSLastKnownPressureRR m5 : 40|8@1+ (0.025,0) [0|0] "" Vector__XXX
 SG_ VCSEC_TPMSLocation0 m0 : 40|3@1+ (1,0) [0|0] "" Vector__XXX
 SG_ VCSEC_TPMSLocation1 m1 : 40|3@1+ (1,0) [0|0] "" Vector__XXX
 SG_ VCSEC_TPMSLocation2 m2 : 40|3@1+ (1,0) [0|0] "" Vector__XXX
 SG_ VCSEC_TPMSLocation3 m3 : 40|3@1+ (1,0) [0|0] "" Vector__XXX
 SG_ VCSEC_TPMSTemperatureCompensatedPressure0 m0 : 43|9@1+ (0.025,0) [0|0] "" Vector__XXX
 SG_ VCSEC_TPMSTemperatureCompensatedPressure1 m1 : 43|9@1+ (0.025,0) [0|0] "" Vector__XXX
 SG_ VCSEC_TPMSTemperatureCompensatedPressure2 m2 : 43|9@1+ (0.025,0) [0|0] "" Vector__XXX
 SG_ VCSEC_TPMSTemperatureCompensatedPressure3 m3 : 43|9@1+ (0.025,0) [0|0] "" Vector__XXX

BO_ 538 TAS_uiControl: 8 Vector__XXX
 SG_ TAS_yellowWarningLamp : 0|1@1+ (1,0) [0|0] "" Vector__XXX
 SG_ TAS_redWarningLamp : 1|1@1+ (1,0) [0|0] "" Vector__XXX
 SG_ TAS_veryLowAllowed : 2|1@1+ (1,0) [0|0] "" Vector__XXX
 SG_ TAS_lowAllowed : 3|1@1+ (1,0) [0|0] "" Vector__XXX
 SG_ TAS_standardAllowed : 4|1@1+ (1,0) [0|0] "" Vector__XXX
 SG_ TAS_highAllowed : 5|1@1+ (1,0) [0|0] "" Vector__XXX
 SG_ TAS_veryHighAllowed : 6|1@1+ (1,0) [0|0] "" Vector__XXX
 SG_ TAS_extractAllowed : 7|1@1+ (1,0) [0|0] "" Vector__XXX
 SG_ TAS_showSpinner : 9|1@1+ (1,0) [0|0] "" Vector__XXX
 SG_ TAS_adaptiveRideModeOverride : 10|2@1+ (1,0) [0|0] "" Vector__XXX
 SG_ TAS_levelSelectEnabled : 12|1@1+ (1,0) [0|0] "" Vector__XXX
 SG_ TAS_jackModeToggleEnabled : 13|1@1+ (1,0) [0|0] "" Vector__XXX
 SG_ TAS_adaptiveRideSelectEnabled : 14|1@1+ (1,0) [0|0] "" Vector__XXX
 SG_ TAS_launchModeState : 16|3@1+ (1,0) [0|0] "" Vector__XXX
 SG_ TAS_restrictUpLevelingFalcons : 19|1@1+ (1,0) [0|0] "" Vector__XXX
 SG_ TAS_restrictUpLevelingTrunk : 20|1@1+ (1,0) [0|0] "" Vector__XXX
 SG_ TAS_restrictDownLevelingDoors : 21|1@1+ (1,0) [0|0] "" Vector__XXX
 SG_ TAS_restrictLevelingChargeCable : 22|1@1+ (1,0) [0|0] "" Vector__XXX
 SG_ TAS_restrictLevelingSystemCheck : 23|1@1+ (1,0) [0|0] "" Vector__XXX
 SG_ TAS_restrictLevelingTransport : 24|1@1+ (1,0) [0|0] "" Vector__XXX
 SG_ TAS_restrictLevelingShowroom : 25|1@1+ (1,0) [0|0] "" Vector__XXX
 SG_ TAS_uiControlCounter : 28|4@1+ (1,0) [0|0] "" Vector__XXX
 SG_ TAS_uiControlChecksum : 32|8@1+ (1,0) [0|0] "" Vector__XXX

BO_ 541 CP_evseStatus: 8 Vector__XXX
 SG_ CP_evseAccept : 0|1@1+ (1,0) [0|0] "" Vector__XXX
 SG_ CP_evseRequest : 1|1@1+ (1,0) [0|0] "" Vector__XXX
 SG_ CP_proximity : 2|2@1+ (1,0) [0|0] "" Vector__XXX
 SG_ CP_pilot : 4|3@1+ (1,0) [0|0] "" Vector__XXX
 SG_ CP_digitalCommsEstablished : 7|1@1+ (1,0) [0|0] "" Vector__XXX
 SG_ CP_pilotCurrent : 8|8@1+ (0.5,0) [0|0] "" Vector__XXX
 SG_ CP_cableType : 16|3@1+ (1,0) [0|0] "" Vector__XXX
 SG_ CP_iecPilotState : 19|4@1+ (1,0) [0|0] "" Vector__XXX
 SG_ CP_plcSupported : 23|1@1+ (1,0) [0|0] "" Vector__XXX
 SG_ CP_cableCurrentLimit : 24|7@1+ (1,0) [0|0] "" Vector__XXX
 SG_ CP_teslaSwcanState : 34|4@1+ (1,0) [0|0] "" Vector__XXX
 SG_ CP_evseChargeType_UI : 38|2@1+ (1,0) [0|0] "" Vector__XXX
 SG_ CP_gbState : 40|4@1+ (1,0) [0|0] "" Vector__XXX
 SG_ CP_gbdcStopChargeReason : 44|4@1+ (1,0) [0|0] "" Vector__XXX
 SG_ CP_gbdcFailureReason : 48|2@1+ (1,0) [0|0] "" Vector__XXX
 SG_ CP_gbdcChargeAttempts : 50|2@1+ (1,0) [0|0] "" Vector__XXX
 SG_ CP_acChargeState : 52|3@1+ (1,0) [0|0] "" Vector__XXX
 SG_ CP_acChargeType : 56|2@1+ (1,0) [0|0] "" Vector__XXX
 SG_ CP_teslaDcState : 58|4@1+ (1,0) [0|0] "" Vector__XXX

BO_ 545 VCFRONT_LVPowerState: 8 Vector__XXX
 SG_ VCFRONT_LVPowerStateIndex M : 0|5@1+ (1,0) [0|0] "" Vector__XXX
 SG_ VCFRONT_vehiclePowerState : 5|2@1+ (1,0) [0|0] "" Vector__XXX
 SG_ VCFRONT_cpLVRequest m1 : 8|2@1+ (1,0) [0|0] "" Vector__XXX
 SG_ VCFRONT_parkLVState m0 : 8|2@1+ (1,0) [0|0] "" Vector__XXX
 SG_ VCFRONT_epasLVState m1 : 10|2@1+ (1,0) [0|0] "" Vector__XXX
 SG_ VCFRONT_espLVState m0 : 10|2@1+ (1,0) [0|0] "" Vector__XXX
 SG_ VCFRONT_hvcLVRequest m1 : 12|2@1+ (1,0) [0|0] "" Vector__XXX
 SG_ VCFRONT_radcLVState m0 : 12|2@1+ (1,0) [0|0] "" Vector__XXX
 SG_ VCFRONT_hvacCompLVState m0 : 14|2@1+ (1,0) [0|0] "" Vector__XXX
 SG_ VCFRONT_tasLVState m1 : 14|2@1+ (1,0) [0|0] "" Vector__XXX
 SG_ VCFRONT_pcsLVState m1 : 16|2@1+ (1,0) [0|0] "" Vector__XXX
 SG_ VCFRONT_ptcLVRequest m0 : 16|2@1+ (1,0) [0|0] "" Vector__XXX
 SG_ VCFRONT_CMPDLVState m1 : 18|2@1+ (1,0) [0|0] "" Vector__XXX
 SG_ VCFRONT_sccmLVRequest m0 : 18|2@1+ (1,0) [0|0] "" Vector__XXX
 SG_ VCFRONT_hcmlLVState m1 : 20|2@1+ (1,0) [0|0] "" Vector__XXX
 SG_ VCFRONT_tpmsLVRequest m0 : 20|2@1+ (1,0) [0|0] "" Vector__XXX
 SG_ VCFRONT_hcmrLVState m1 : 22|2@1+ (1,0) [0|0] "" Vector__XXX
 SG_ VCFRONT_rcmLVRequest m0 : 22|2@1+ (1,0) [0|0] "" Vector__XXX
 SG_ VCFRONT_MCUAudioLVState m1 : 24|2@1+ (1,0) [0|0] "" Vector__XXX
 SG_ VCFRONT_iBoosterLVState m0 : 24|2@1+ (1,0) [0|0] "" Vector__XXX
 SG_ VCFRONT_espValveLVState m1 : 26|2@1+ (1,0) [0|0] "" Vector__XXX
 SG_ VCFRONT_tunerLVRequest m0 : 26|2@1+ (1,0) [0|0] "" Vector__XXX
 SG_ VCFRONT_MCUGraphicsLVState m1 : 28|2@1+ (1,0) [0|0] "" Vector__XXX
 SG_ VCFRONT_amplifierLVRequest m0 : 28|2@1+ (1,0) [0|0] "" Vector__XXX
 SG_ VCFRONT_das1HighCurrentLVState m0 : 30|2@1+ (1,0) [0|0] "" Vector__XXX
 SG_ VC_dcdcSupportRequest m1 : 30|1@1+ (1,0) [0|0] "" Vector__XXX
 SG_ VC_hvStateRequest m1 : 31|3@1+ (1,0) [0|0] "" Vector__XXX
 SG_ VCFRONT_das2HighCurrentLVState m0 : 32|2@1+ (1,0) [0|0] "" Vector__XXX
 SG_ VCFRONT_dirLVRequest m0 : 34|2@1+ (1,0) [0|0] "" Vector__XXX
 SG_ VC_autonomyBehavior m1 : 34|2@1+ (1,0) [0|0] "" Vector__XXX
 SG_ VCFRONT_difLVState m0 : 36|2@1+ (1,0) [0|0] "" Vector__XXX
 SG_ VCFRONT_oilPumpFrontLVState m0 : 38|2@1+ (1,0) [0|0] "" Vector__XXX
 SG_ VC_persistAccPowerRequestOverridden m1 : 39|1@1+ (1,0) [0|0] "" Vector__XXX
 SG_ VCFRONT_oilPumpRearLVRequest m0 : 40|2@1+ (1,0) [0|0] "" Vector__XXX
 SG_ VC_accPortPowerRequest m1 : 40|1@1+ (1,0) [0|0] "" Vector__XXX
 SG_ VC_persistAccPortPowerState m1 : 41|3@1+ (1,0) [0|0] "" Vector__XXX
 SG_ VCFRONT_ocsLVRequest m0 : 42|2@1+ (1,0) [0|0] "" Vector__XXX
 SG_ VCFRONT_vcleftHiCurrentLVState m0 : 44|2@1+ (1,0) [0|0] "" Vector__XXX
 SG_ VCFRONT_vcrightHiCurrentLVState m0 : 46|2@1+ (1,0) [0|0] "" Vector__XXX
 SG_ VC_noAccDeviceDetectedWhileIdle m1 : 46|1@1+ (1,0) [0|0] "" Vector__XXX
 SG_ VCFRONT_uiHiCurrentLVState m0 : 48|2@1+ (1,0) [0|0] "" Vector__XXX
 SG_ VCFRONT_inAccessoryPlus : 50|1@1+ (1,0) [0|0] "" Vector__XXX
 SG_ VCFRONT_LVShuttingDown : 51|1@1+ (1,0) [0|0] "" Vector__XXX
 SG_ VCFRONT_LVPowerStateCounter : 52|4@1+ (1,0) [0|0] "" Vector__XXX
 SG_ VCFRONT_LVPowerStateChecksum : 56|8@1+ (1,0) [0|0] "" Vector__XXX

BO_ 546 TAS_compTemp: 8 Vector__XXX
 SG_ TAS_compTempSensor : 0|8@1+ (1,-40) [0|0] "" Vector__XXX
 SG_ TAS_compTempModel : 8|8@1+ (1,-40) [0|0] "" Vector__XXX

BO_ 548 PCS_dcdcStatus: 8 Vector__XXX
 SG_ PCS_dcdcPrechargeStatus : 0|2@1+ (1,0) [0|0] "" Vector__XXX
 SG_ PCS_dcdcLvSupportStatus : 2|2@1+ (1,0) [0|0] "" Vector__XXX
 SG_ PCS_dcdcHvBusDischargeStatus : 4|2@1+ (1,0) [0|0] "" Vector__XXX
 SG_ PCS_coldSleepAllowed : 8|1@1+ (1,0) [0|0] "" Vector__XXX
 SG_ PCS_dcdcPchgHVBusLowRDetected : 9|1@1+ (1,0) [0|0] "" Vector__XXX
 SG_ PCS_dcdcSubState : 10|5@1+ (1,0) [0|0] "" Vector__XXX
 SG_ PCS_dcdcFaulted : 15|1@1+ (1,0) [0|0] "" Vector__XXX
 SG_ PCS_okToBePowerCycled : 27|1@1+ (1,0) [0|0] "" Vector__XXX
 SG_ PCS_dcdcOutputIsLimited : 28|1@1+ (1,0) [0|0] "" Vector__XXX
 SG_ PCS_dcdcMaxOutputCurrentAllowed : 29|12@1+ (0.1,0) [0|0] "" Vector__XXX
 SG_ PCS_dcdcPrechargeRtyCnt : 41|3@1+ (1,0) [0|0] "" Vector__XXX
 SG_ PCS_dcdcLvSupportRtyCnt : 44|4@1+ (1,0) [0|0] "" Vector__XXX
 SG_ PCS_dcdcDischargeRtyCnt : 48|4@1+ (1,0) [0|0] "" Vector__XXX
 SG_ PCS_dcdcPwmEnableLine : 52|1@1+ (1,0) [0|0] "" Vector__XXX
 SG_ PCS_dcdcSupportingFixedLvTarget : 53|1@1+ (1,0) [0|0] "" Vector__XXX
 SG_ PCS_ecuLogUploadRequest : 54|2@1+ (1,0) [0|0] "" Vector__XXX
 SG_ PCS_dcdcPrechargeRestartCnt : 56|3@1+ (1,0) [0|0] "" Vector__XXX
 SG_ PCS_dcdcInitialPrechargeSubState : 59|5@1+ (1,0) [0|0] "" Vector__XXX

BO_ 549 VCRIGHT_LVPowerState: 8 Vector__XXX
 SG_ VCRIGHT_ptcLVState : 0|2@1+ (1,0) [0|0] "" Vector__XXX
 SG_ VCRIGHT_ocsLVState : 2|2@1+ (1,0) [0|0] "" Vector__XXX
 SG_ VCRIGHT_premAudioLVState : 4|2@1+ (1,0) [0|0] "" Vector__XXX
 SG_ VCRIGHT_rearOilPumpLVState : 6|2@1+ (1,0) [0|0] "" Vector__XXX
 SG_ VCRIGHT_tunerLVState : 8|2@1+ (1,0) [0|0] "" Vector__XXX
 SG_ VCRIGHT_hvcLVState : 10|2@1+ (1,0) [0|0] "" Vector__XXX
 SG_ VCRIGHT_rcmLVState : 12|2@1+ (1,0) [0|0] "" Vector__XXX
 SG_ VCRIGHT_lumbarLVState : 14|2@1+ (1,0) [0|0] "" Vector__XXX
 SG_ VCRIGHT_cntctrPwrState : 17|1@1+ (1,0) [0|0] "" Vector__XXX
 SG_ VCRIGHT_eFuseLockoutStatus : 18|2@1+ (1,0) [0|0] "" Vector__XXX
 SG_ VCRIGHT_swEnStatus : 20|1@1+ (1,0) [0|0] "" Vector__XXX
 SG_ VCRIGHT_vehiclePowerStateDBG : 21|2@1+ (1,0) [0|0] "" Vector__XXX
 SG_ VCRIGHT_parkLVState : 23|2@1+ (1,0) [0|0] "" Vector__XXX
 SG_ VCRIGHT_icrLVState : 25|2@1+ (1,0) [0|0] "" Vector__XXX
 SG_ VCRIGHT_interiorCameraLedLVState : 27|2@1+ (1,0) [0|0] "" Vector__XXX
 SG_ VCRIGHT_accDevicesDetected : 31|1@1+ (1,0) [0|0] "" Vector__XXX

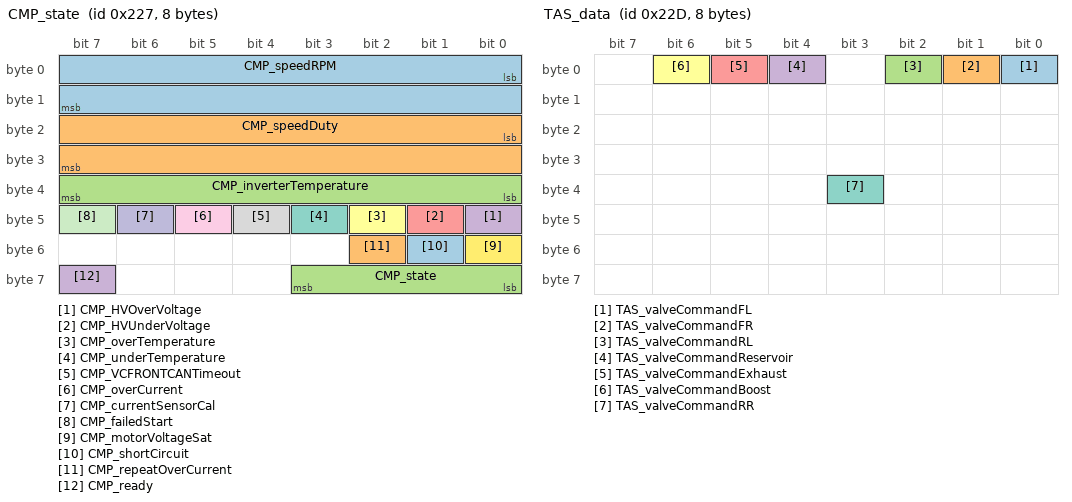
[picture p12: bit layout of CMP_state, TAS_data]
BO_ 551 CMP_state: 8 Vector__XXX
 SG_ CMP_speedRPM : 0|16@1+ (1,0) [0|0] "" Vector__XXX
 SG_ CMP_speedDuty : 16|16@1+ (0.1,0) [0|0] "" Vector__XXX
 SG_ CMP_inverterTemperature : 32|8@1+ (1,-40) [0|0] "" Vector__XXX
 SG_ CMP_HVOverVoltage : 40|1@1+ (1,0) [0|0] "" Vector__XXX
 SG_ CMP_HVUnderVoltage : 41|1@1+ (1,0) [0|0] "" Vector__XXX
 SG_ CMP_overTemperature : 42|1@1+ (1,0) [0|0] "" Vector__XXX
 SG_ CMP_underTemperature : 43|1@1+ (1,0) [0|0] "" Vector__XXX
 SG_ CMP_VCFRONTCANTimeout : 44|1@1+ (1,0) [0|0] "" Vector__XXX
 SG_ CMP_overCurrent : 45|1@1+ (1,0) [0|0] "" Vector__XXX
 SG_ CMP_currentSensorCal : 46|1@1+ (1,0) [0|0] "" Vector__XXX
 SG_ CMP_failedStart : 47|1@1+ (1,0) [0|0] "" Vector__XXX
 SG_ CMP_motorVoltageSat : 48|1@1+ (1,0) [0|0] "" Vector__XXX
 SG_ CMP_shortCircuit : 49|1@1+ (1,0) [0|0] "" Vector__XXX
 SG_ CMP_repeatOverCurrent : 50|1@1+ (1,0) [0|0] "" Vector__XXX
 SG_ CMP_state : 56|4@1+ (1,0) [0|0] "" Vector__XXX
 SG_ CMP_ready : 63|1@1+ (1,0) [0|0] "" Vector__XXX

BO_ 552 EPBR_internalStatus: 8 Vector__XXX
 SG_ EPBR_unitStatus : 0|5@1+ (1,0) [0|0] "" Vector__XXX
 SG_ EPBR_unitFaultStatus : 5|2@1+ (1,0) [0|0] "" Vector__XXX
 SG_ EPBR_summonState : 8|3@1+ (1,0) [0|0] "" Vector__XXX
 SG_ EPBR_disconnected : 11|1@1+ (1,0) [0|0] "" Vector__XXX
 SG_ EPBR_pistonTouchingRotor : 12|1@1+ (1,0) [0|0] "" Vector__XXX
 SG_ EPBR_csmFaultReason : 13|5@1+ (1,0) [0|0] "" Vector__XXX
 SG_ EPBR_esmOperationTrigger : 18|6@1+ (1,0) [0|0] "" Vector__XXX
 SG_ EPBR_summonFaultReason : 24|5@1+ (1,0) [0|0] "" Vector__XXX
 SG_ EPBR_localServiceModeActive : 29|1@1+ (1,0) [0|0] "" Vector__XXX
 SG_ EPBR_localCdpState : 30|2@1+ (1,0) [0|0] "" Vector__XXX
 SG_ EPBR_chimeRequestLocal : 33|3@1+ (1,0) [0|0] "" Vector__XXX
 SG_ EPBR_telltaleLocal : 39|3@1+ (1,0) [0|0] "" Vector__XXX
 SG_ EPBR_driverIsLeavingLocal : 42|1@1+ (1,0) [0|0] "" Vector__XXX
 SG_ EPBR_driverIsLeavingAnySpeedLocal : 43|1@1+ (1,0) [0|0] "" Vector__XXX
 SG_ EPBR_internalCDPRequest : 44|1@1+ (1,0) [0|0] "" Vector__XXX
 SG_ EPBR_esmSpeedClass : 45|3@1+ (1,0) [0|0] "" Vector__XXX
 SG_ EPBR_learnedEpbConfig : 48|4@1+ (1,0) [0|0] "" Vector__XXX
 SG_ EPBR_internalStatusCounter : 52|4@1+ (1,0) [0|0] "" Vector__XXX
 SG_ EPBR_internalStatusChecksum : 56|8@1+ (1,0) [0|0] "" Vector__XXX

BO_ 553 SCCM_rightStalk: 8 Vector__XXX
 SG_ SCCM_rightStalkCrc : 0|8@1+ (1,0) [0|0] "" Vector__XXX
 SG_ SCCM_rightStalkCounter : 8|4@1+ (1,0) [0|0] "" Vector__XXX
 SG_ SCCM_rightStalkStatus : 12|3@1+ (1,0) [0|0] "" Vector__XXX
 SG_ SCCM_rightStalkReserved1 : 15|1@1+ (1,0) [0|0] "" Vector__XXX
 SG_ SCCM_parkButtonStatus : 16|2@1+ (1,0) [0|0] "" Vector__XXX
 SG_ SCCM_rightStalkReserved2 : 18|6@1+ (1,0) [0|0] "" Vector__XXX

BO_ 554 HVP_hvsControl: 8 Vector__XXX
 SG_ HVP_dcLinkVoltageRequest : 0|16@1- (0.1,0) [0|0] "" Vector__XXX
 SG_ HVP_pcsControlRequest : 16|2@1+ (1,0) [0|0] "" Vector__XXX
 SG_ HVP_pcsChargeHwEnabled : 18|1@1+ (1,0) [0|0] "" Vector__XXX
 SG_ HVP_pcsDcdcHwEnabled : 19|1@1+ (1,0) [0|0] "" Vector__XXX
 SG_ HVP_dcLinkVoltageFiltered : 20|11@1- (1,0) [0|0] "" Vector__XXX

BO_ 555 DAS_matrixHighBeamRequest: 8 Vector__XXX
 SG_ DAS_azimuthSegmentLightRequests : 0|64@1+ (1,0) [0|0] "" Vector__XXX

BO_ 557 TAS_data: 8 Vector__XXX
 SG_ TAS_valveCommandFL : 0|1@1+ (1,0) [0|0] "" Vector__XXX
 SG_ TAS_valveCommandFR : 1|1@1+ (1,0) [0|0] "" Vector__XXX
 SG_ TAS_valveCommandRL : 2|1@1+ (1,0) [0|0] "" Vector__XXX
 SG_ TAS_valveCommandReservoir : 4|1@1+ (1,0) [0|0] "" Vector__XXX
 SG_ TAS_valveCommandExhaust : 5|1@1+ (1,0) [0|0] "" Vector__XXX
 SG_ TAS_valveCommandBoost : 6|1@1+ (1,0) [0|0] "" Vector__XXX
 SG_ TAS_valveCommandRR : 35|1@1+ (1,0) [0|0] "" Vector__XXX

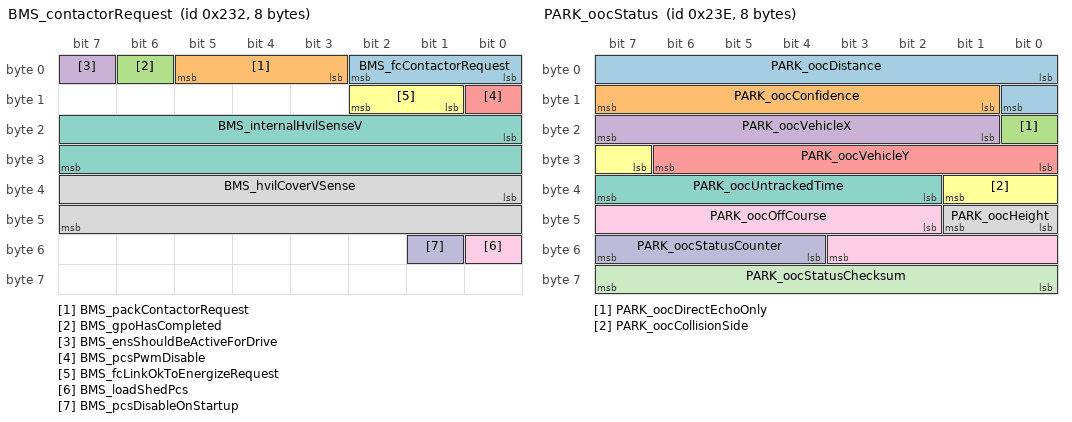
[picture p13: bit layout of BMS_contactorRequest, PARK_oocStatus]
BO_ 562 BMS_contactorRequest: 8 Vector__XXX
 SG_ BMS_fcContactorRequest : 0|3@1+ (1,0) [0|0] "" Vector__XXX
 SG_ BMS_packContactorRequest : 3|3@1+ (1,0) [0|0] "" Vector__XXX
 SG_ BMS_gpoHasCompleted : 6|1@1+ (1,0) [0|0] "" Vector__XXX
 SG_ BMS_ensShouldBeActiveForDrive : 7|1@1+ (1,0) [0|0] "" Vector__XXX
 SG_ BMS_pcsPwmDisable : 8|1@1+ (1,0) [0|0] "" Vector__XXX
 SG_ BMS_fcLinkOkToEnergizeRequest : 9|2@1+ (1,0) [0|0] "" Vector__XXX
 SG_ BMS_internalHvilSenseV : 16|16@1+ (0.001,0) [0|0] "" Vector__XXX
 SG_ BMS_hvilCoverVSense : 32|16@1+ (0.001,0) [0|0] "" Vector__XXX
 SG_ BMS_loadShedPcs : 48|1@1+ (1,0) [0|0] "" Vector__XXX
 SG_ BMS_pcsDisableOnStartup : 49|1@1+ (1,0) [0|0] "" Vector__XXX

BO_ 564 DCDC_power: 8 Vector__XXX
 SG_ DCDC_instantLvOutputPowerEstimated m0 : 0|12@1- (10,0) [0|0] "" Vector__XXX
 SG_ DCDC_transientLvOutputPowerLimit m1 : 0|10@1+ (10,0) [0|0] "" Vector__XXX
 SG_ DCDC_severeUvLvOutputPowerLimit m1 : 10|10@1+ (10,0) [0|0] "" Vector__XXX
 SG_ DCDC_filteredLvOutputPowerEstimated m0 : 12|12@1- (10,0) [0|0] "" Vector__XXX
 SG_ DCDC_severeOvLvInputPowerLimit m1 : 20|10@1+ (10,0) [0|0] "" Vector__XXX
 SG_ DCDC_continuousLvOutputPowerLimit m0 : 24|10@1+ (10,0) [0|0] "" Vector__XXX
 SG_ DCDC_minTargetContLvOutputPowerLimit m1 : 30|10@1+ (10,0) [0|0] "" Vector__XXX
 SG_ DCDC_instantLvOutputPowerLimit m0 : 34|10@1+ (10,0) [0|0] "" Vector__XXX
 SG_ DCDC_packSideContLvOutputPowerLimit m1 : 40|10@1+ (10,0) [0|0] "" Vector__XXX
 SG_ DCDC_auxiliaryStageSaturationWarning m0 : 44|1@1+ (1,0) [0|0] "" Vector__XXX
 SG_ DCDC_type m0 : 45|2@1+ (1,0) [0|0] "" Vector__XXX
 SG_ DCDC_powerMuxIndex M : 50|2@1+ (1,0) [0|0] "" Vector__XXX
 SG_ DCDC_powerCounter : 52|4@1+ (1,0) [0|0] "" Vector__XXX
 SG_ DCDC_powerChecksum : 56|8@1+ (1,0) [0|0] "" Vector__XXX

BO_ 568 UI_driverAssistMapData: 8 Vector__XXX
 SG_ UI_mapSpeedLimitDependency : 0|3@1+ (1,0) [0|0] "" Vector__XXX
 SG_ UI_roadClass : 3|3@1+ (1,0) [0|0] "" Vector__XXX
 SG_ UI_inSuperchargerGeofence : 6|1@1+ (1,0) [0|0] "" Vector__XXX
 SG_ UI_mapSpeedUnits : 7|1@1+ (1,0) [0|0] "" Vector__XXX
 SG_ UI_mapSpeedLimit : 8|5@1+ (1,0) [0|0] "" Vector__XXX
 SG_ UI_mapSpeedLimitType : 13|3@1+ (1,0) [0|0] "" Vector__XXX
 SG_ UI_countryCode : 16|10@1+ (1,0) [0|0] "" Vector__XXX
 SG_ UI_streetCount : 26|2@1+ (1,0) [0|0] "" Vector__XXX
 SG_ UI_gpsRoadMatch : 28|1@1+ (1,0) [0|0] "" Vector__XXX
 SG_ UI_navRouteActive : 29|1@1+ (1,0) [0|0] "" Vector__XXX
 SG_ UI_parallelAutoparkEnabled : 30|1@1+ (1,0) [0|0] "" Vector__XXX
 SG_ UI_perpendicularAutoparkEnabled : 31|1@1+ (1,0) [0|0] "" Vector__XXX
 SG_ UI_nextBranchDist : 32|5@1+ (10,0) [0|0] "" Vector__XXX
 SG_ UI_controlledAccess : 37|1@1+ (1,0) [0|0] "" Vector__XXX
 SG_ UI_nextBranchLeftOffRamp : 38|1@1+ (1,0) [0|0] "" Vector__XXX
 SG_ UI_nextBranchRightOffRamp : 39|1@1+ (1,0) [0|0] "" Vector__XXX
 SG_ UI_rejectLeftLane : 40|1@1+ (1,0) [0|0] "" Vector__XXX
 SG_ UI_rejectRightLane : 41|1@1+ (1,0) [0|0] "" Vector__XXX
 SG_ UI_rejectHPP : 42|1@1+ (1,0) [0|0] "" Vector__XXX
 SG_ UI_rejectNav : 43|1@1+ (1,0) [0|0] "" Vector__XXX
 SG_ UI_rejectLeftFreeSpace : 44|1@1+ (1,0) [0|0] "" Vector__XXX
 SG_ UI_rejectRightFreeSpace : 45|1@1+ (1,0) [0|0] "" Vector__XXX
 SG_ UI_rejectAutosteer : 46|1@1+ (1,0) [0|0] "" Vector__XXX
 SG_ UI_rejectHandsOn : 47|1@1+ (1,0) [0|0] "" Vector__XXX
 SG_ UI_acceptBottsDots : 48|1@1+ (1,0) [0|0] "" Vector__XXX
 SG_ UI_autosteerRestricted : 49|1@1+ (1,0) [0|0] "" Vector__XXX
 SG_ UI_pmmEnabled : 50|1@1+ (1,0) [0|0] "" Vector__XXX
 SG_ UI_scaEnabled : 51|1@1+ (1,0) [0|0] "" Vector__XXX
 SG_ UI_mapDataCounter : 52|4@1+ (1,0) [0|0] "" Vector__XXX
 SG_ UI_mapDataChecksum : 56|8@1+ (1,0) [0|0] "" Vector__XXX

BO_ 570 VCSEC_TPMSStatus: 8 Vector__XXX
 SG_ VCSEC_TPMSStatusIndex M : 0|6@1+ (1,0) [0|0] "" Vector__XXX
 SG_ VCSEC_TPMSSystemState : 6|1@1+ (1,0) [0|0] "" Vector__XXX
 SG_ VCSEC_BLESuccessfulConnEventCount0 m4 : 8|15@1+ (1,0) [0|0] "" Vector__XXX
 SG_ VCSEC_BLESuccessfulConnEventCount1 m6 : 8|15@1+ (1,0) [0|0] "" Vector__XXX
 SG_ VCSEC_BLESuccessfulConnEventCount2 m8 : 8|15@1+ (1,0) [0|0] "" Vector__XXX
 SG_ VCSEC_BLESuccessfulConnEventCount3 m10 : 8|15@1+ (1,0) [0|0] "" Vector__XXX
 SG_ VCSEC_BLEUnsuccessfulConnEventRate0 m5 : 8|10@1+ (0.08,0) [0|0] "" Vector__XXX
 SG_ VCSEC_BLEUnsuccessfulConnEventRate1 m7 : 8|10@1+ (0.08,0) [0|0] "" Vector__XXX
 SG_ VCSEC_BLEUnsuccessfulConnEventRate2 m9 : 8|10@1+ (0.08,0) [0|0] "" Vector__XXX
 SG_ VCSEC_BLEUnsuccessfulConnEventRate3 m11 : 8|10@1+ (0.08,0) [0|0] "" Vector__XXX
 SG_ VCSEC_TPMSFilteredBatVoltage0 m37 : 8|8@1+ (0.01,1.5) [0|0] "" Vector__XXX
 SG_ VCSEC_TPMSLastLocationSensor0 m35 : 8|3@1+ (1,0) [0|0] "" Vector__XXX
 SG_ VCSEC_TPMSSensor0Hash m33 : 8|28@1+ (1,0) [0|0] "" Vector__XXX
 SG_ VCSEC_TPMSSensor2Hash m34 : 8|28@1+ (1,0) [0|0] "" Vector__XXX
 SG_ VCSEC_TPMSSensorMACAddress0 m0 : 8|48@1+ (1,0) [0|0] "" Vector__XXX
 SG_ VCSEC_TPMSSensorMACAddress1 m1 : 8|48@1+ (1,0) [0|0] "" Vector__XXX
 SG_ VCSEC_TPMSSensorMACAddress2 m2 : 8|48@1+ (1,0) [0|0] "" Vector__XXX
 SG_ VCSEC_TPMSSensorMACAddress3 m3 : 8|48@1+ (1,0) [0|0] "" Vector__XXX
 SG_ VCSEC_TPMSSensorParameterState m32 : 8|2@1+ (1,0) [0|0] "" Vector__XXX
 SG_ VCSEC_TPMSSensorTIAppCRC0 m12 : 8|32@1+ (1,0) [0|0] "" Vector__XXX
 SG_ VCSEC_TPMSSensorTIAppCRC1 m13 : 8|32@1+ (1,0) [0|0] "" Vector__XXX
 SG_ VCSEC_TPMSSensorTIAppCRC2 m14 : 8|32@1+ (1,0) [0|0] "" Vector__XXX
 SG_ VCSEC_TPMSSensorTIAppCRC3 m15 : 8|32@1+ (1,0) [0|0] "" Vector__XXX
 SG_ VCSEC_TPMSTemperatureCompensatedBatVoltage0 m36 : 8|8@1+ (0.01,1.5) [0|0] "" Vector__XXX
 SG_ VCSEC_TPMSTotalResetsDueToPowerOn0 m24 : 8|8@1+ (1,0) [0|0] "" Vector__XXX
 SG_ VCSEC_TPMSTotalResetsDueToPowerOn1 m26 : 8|8@1+ (1,0) [0|0] "" Vector__XXX
 SG_ VCSEC_TPMSTotalResetsDueToPowerOn2 m28 : 8|8@1+ (1,0) [0|0] "" Vector__XXX
 SG_ VCSEC_TPMSTotalResetsDueToPowerOn3 m30 : 8|8@1+ (1,0) [0|0] "" Vector__XXX
 SG_ VCSEC_TPMSTotalResetsDueToWarmReset0 m25 : 8|8@1+ (1,0) [0|0] "" Vector__XXX
 SG_ VCSEC_TPMSTotalResetsDueToWarmReset1 m27 : 8|8@1+ (1,0) [0|0] "" Vector__XXX
 SG_ VCSEC_TPMSTotalResetsDueToWarmReset2 m29 : 8|8@1+ (1,0) [0|0] "" Vector__XXX
 SG_ VCSEC_TPMSTotalResetsDueToWarmReset3 m31 : 8|8@1+ (1,0) [0|0] "" Vector__XXX
 SG_ VCSEC_TPMStotalAwakeTime0 m20 : 8|32@1+ (1,0) [0|0] "" Vector__XXX
 SG_ VCSEC_TPMStotalAwakeTime1 m21 : 8|32@1+ (1,0) [0|0] "" Vector__XXX
 SG_ VCSEC_TPMStotalAwakeTime2 m22 : 8|32@1+ (1,0) [0|0] "" Vector__XXX
 SG_ VCSEC_TPMStotalAwakeTime3 m23 : 8|32@1+ (1,0) [0|0] "" Vector__XXX
 SG_ VCSEC_TPMStotalCPUTime0 m16 : 8|32@1+ (1,0) [0|0] "" Vector__XXX
 SG_ VCSEC_TPMStotalCPUTime1 m17 : 8|32@1+ (1,0) [0|0] "" Vector__XXX
 SG_ VCSEC_TPMStotalCPUTime2 m18 : 8|32@1+ (1,0) [0|0] "" Vector__XXX
 SG_ VCSEC_TPMStotalCPUTime3 m19 : 8|32@1+ (1,0) [0|0] "" Vector__XXX
 SG_ VCSEC_TPMSLastLocationSensor1 m35 : 11|3@1+ (1,0) [0|0] "" Vector__XXX
 SG_ VCSEC_TPMSFilteredBatVoltage2 m37 : 16|8@1+ (0.01,1.5) [0|0] "" Vector__XXX
 SG_ VCSEC_TPMSLastLocationSensor2 m35 : 16|3@1+ (1,0) [0|0] "" Vector__XXX
 SG_ VCSEC_TPMSTemperatureCompensatedBatVoltage1 m36 : 16|8@1+ (0.01,1.5) [0|0] "" Vector__XXX
 SG_ VCSEC_TPMSTotalResetsDueToPinReset0 m24 : 16|8@1+ (1,0) [0|0] "" Vector__XXX
 SG_ VCSEC_TPMSTotalResetsDueToPinReset1 m26 : 16|8@1+ (1,0) [0|0] "" Vector__XXX
 SG_ VCSEC_TPMSTotalResetsDueToPinReset2 m28 : 16|8@1+ (1,0) [0|0] "" Vector__XXX
 SG_ VCSEC_TPMSTotalResetsDueToPinReset3 m30 : 16|8@1+ (1,0) [0|0] "" Vector__XXX
 SG_ VCSEC_TPMSTotalResetsDueToWakeupFromShutdown0 m25 : 16|8@1+ (1,0) [0|0] "" Vector__XXX
 SG_ VCSEC_TPMSTotalResetsDueToWakeupFromShutdown1 m27 : 16|8@1+ (1,0) [0|0] "" Vector__XXX
 SG_ VCSEC_TPMSTotalResetsDueToWakeupFromShutdown2 m29 : 16|8@1+ (1,0) [0|0] "" Vector__XXX
 SG_ VCSEC_TPMSTotalResetsDueToWakeupFromShutdown3 m31 : 16|8@1+ (1,0) [0|0] "" Vector__XXX
 SG_ VCSEC_TPMSLastLocationSensor3 m35 : 19|3@1+ (1,0) [0|0] "" Vector__XXX
 SG_ VCSEC_BLEMissedConnEventCount0 m4 : 24|14@1+ (1,0) [0|0] "" Vector__XXX
 SG_ VCSEC_BLEMissedConnEventCount1 m6 : 24|14@1+ (1,0) [0|0] "" Vector__XXX
 SG_ VCSEC_BLEMissedConnEventCount2 m8 : 24|14@1+ (1,0) [0|0] "" Vector__XXX
 SG_ VCSEC_BLEMissedConnEventCount3 m10 : 24|14@1+ (1,0) [0|0] "" Vector__XXX
 SG_ VCSEC_TPMSFilteredBatVoltage1 m37 : 24|8@1+ (0.01,1.5) [0|0] "" Vector__XXX
 SG_ VCSEC_TPMSTemperatureCompensatedBatVoltage2 m36 : 24|8@1+ (0.01,1.5) [0|0] "" Vector__XXX
 SG_ VCSEC_TPMSTotalResetsDueToVDDSLoss0 m24 : 24|8@1+ (1,0) [0|0] "" Vector__XXX
 SG_ VCSEC_TPMSTotalResetsDueToVDDSLoss1 m26 : 24|8@1+ (1,0) [0|0] "" Vector__XXX
 SG_ VCSEC_TPMSTotalResetsDueToVDDSLoss2 m28 : 24|8@1+ (1,0) [0|0] "" Vector__XXX
 SG_ VCSEC_TPMSTotalResetsDueToVDDSLoss3 m30 : 24|8@1+ (1,0) [0|0] "" Vector__XXX
 SG_ VCSEC_TPMSTotalResetsDueToWakeupFromTCKNoise0 m25 : 24|8@1+ (1,0) [0|0] "" Vector__XXX
 SG_ VCSEC_TPMSTotalResetsDueToWakeupFromTCKNoise1 m27 : 24|8@1+ (1,0) [0|0] "" Vector__XXX
 SG_ VCSEC_TPMSTotalResetsDueToWakeupFromTCKNoise2 m29 : 24|8@1+ (1,0) [0|0] "" Vector__XXX
 SG_ VCSEC_TPMSTotalResetsDueToWakeupFromTCKNoise3 m31 : 24|8@1+ (1,0) [0|0] "" Vector__XXX
 SG_ VCSEC_TPMSFilteredBatVoltage3 m37 : 32|8@1+ (0.01,1.5) [0|0] "" Vector__XXX
 SG_ VCSEC_TPMSTemperatureCompensatedBatVoltage3 m36 : 32|8@1+ (0.01,1.5) [0|0] "" Vector__XXX
 SG_ VCSEC_TPMSTotalResetsDueToDCI0 m25 : 32|8@1+ (1,0) [0|0] "" Vector__XXX
 SG_ VCSEC_TPMSTotalResetsDueToDCI1 m27 : 32|8@1+ (1,0) [0|0] "" Vector__XXX
 SG_ VCSEC_TPMSTotalResetsDueToDCI2 m29 : 32|8@1+ (1,0) [0|0] "" Vector__XXX
 SG_ VCSEC_TPMSTotalResetsDueToDCI3 m31 : 32|8@1+ (1,0) [0|0] "" Vector__XXX
 SG_ VCSEC_TPMSTotalResetsDueToVDDLoss0 m24 : 32|8@1+ (1,0) [0|0] "" Vector__XXX
 SG_ VCSEC_TPMSTotalResetsDueToVDDLoss1 m26 : 32|8@1+ (1,0) [0|0] "" Vector__XXX
 SG_ VCSEC_TPMSTotalResetsDueToVDDLoss2 m28 : 32|8@1+ (1,0) [0|0] "" Vector__XXX
 SG_ VCSEC_TPMSTotalResetsDueToVDDLoss3 m30 : 32|8@1+ (1,0) [0|0] "" Vector__XXX
 SG_ VCSEC_TPMSSensor1Hash m33 : 36|28@1+ (1,0) [0|0] "" Vector__XXX
 SG_ VCSEC_TPMSSensor3Hash m34 : 36|28@1+ (1,0) [0|0] "" Vector__XXX
 SG_ VCSEC_BLECRCErrorConnEventCount0 m4 : 40|14@1+ (1,0) [0|0] "" Vector__XXX
 SG_ VCSEC_BLECRCErrorConnEventCount1 m6 : 40|14@1+ (1,0) [0|0] "" Vector__XXX
 SG_ VCSEC_BLECRCErrorConnEventCount2 m8 : 40|14@1+ (1,0) [0|0] "" Vector__XXX
 SG_ VCSEC_BLECRCErrorConnEventCount3 m10 : 40|14@1+ (1,0) [0|0] "" Vector__XXX
 SG_ VCSEC_TPMSAuthenticateSensorState0 m16 : 40|3@1+ (1,0) [0|0] "" Vector__XXX
 SG_ VCSEC_TPMSAuthenticateSensorState1 m17 : 40|3@1+ (1,0) [0|0] "" Vector__XXX
 SG_ VCSEC_TPMSAuthenticateSensorState2 m18 : 40|3@1+ (1,0) [0|0] "" Vector__XXX
 SG_ VCSEC_TPMSAuthenticateSensorState3 m19 : 40|3@1+ (1,0) [0|0] "" Vector__XXX
 SG_ VCSEC_TPMSSensorMLXAppCRC0 m12 : 40|24@1+ (1,0) [0|0] "" Vector__XXX
 SG_ VCSEC_TPMSSensorMLXAppCRC1 m13 : 40|24@1+ (1,0) [0|0] "" Vector__XXX
 SG_ VCSEC_TPMSSensorMLXAppCRC2 m14 : 40|24@1+ (1,0) [0|0] "" Vector__XXX
 SG_ VCSEC_TPMSSensorMLXAppCRC3 m15 : 40|24@1+ (1,0) [0|0] "" Vector__XXX
 SG_ VCSEC_TPMSTotalResetsDueToCoreLockup0 m25 : 40|8@1+ (1,0) [0|0] "" Vector__XXX
 SG_ VCSEC_TPMSTotalResetsDueToCoreLockup1 m27 : 40|8@1+ (1,0) [0|0] "" Vector__XXX
 SG_ VCSEC_TPMSTotalResetsDueToCoreLockup2 m29 : 40|8@1+ (1,0) [0|0] "" Vector__XXX
 SG_ VCSEC_TPMSTotalResetsDueToCoreLockup3 m31 : 40|8@1+ (1,0) [0|0] "" Vector__XXX
 SG_ VCSEC_TPMSTotalResetsDueToVDDRLoss0 m24 : 40|8@1+ (1,0) [0|0] "" Vector__XXX
 SG_ VCSEC_TPMSTotalResetsDueToVDDRLoss1 m26 : 40|8@1+ (1,0) [0|0] "" Vector__XXX
 SG_ VCSEC_TPMSTotalResetsDueToVDDRLoss2 m28 : 40|8@1+ (1,0) [0|0] "" Vector__XXX
 SG_ VCSEC_TPMSTotalResetsDueToVDDRLoss3 m30 : 40|8@1+ (1,0) [0|0] "" Vector__XXX
 SG_ VCSEC_TPMSTrimAdjusted0 m20 : 40|1@1+ (1,0) [0|0] "" Vector__XXX
 SG_ VCSEC_TPMSTrimAdjusted1 m21 : 40|1@1+ (1,0) [0|0] "" Vector__XXX
 SG_ VCSEC_TPMSTrimAdjusted2 m22 : 40|1@1+ (1,0) [0|0] "" Vector__XXX
 SG_ VCSEC_TPMSTrimAdjusted3 m23 : 40|1@1+ (1,0) [0|0] "" Vector__XXX
 SG_ VCSEC_TPMSGenealogySensorState0 m20 : 41|3@1+ (1,0) [0|0] "" Vector__XXX
 SG_ VCSEC_TPMSGenealogySensorState1 m21 : 41|3@1+ (1,0) [0|0] "" Vector__XXX
 SG_ VCSEC_TPMSGenealogySensorState2 m22 : 41|3@1+ (1,0) [0|0] "" Vector__XXX
 SG_ VCSEC_TPMSGenealogySensorState3 m23 : 41|3@1+ (1,0) [0|0] "" Vector__XXX
 SG_ VCSEC_TPMSAuthenticateFailureReason0 m16 : 43|3@1+ (1,0) [0|0] "" Vector__XXX
 SG_ VCSEC_TPMSAuthenticateFailureReason1 m17 : 43|3@1+ (1,0) [0|0] "" Vector__XXX
 SG_ VCSEC_TPMSAuthenticateFailureReason2 m18 : 43|3@1+ (1,0) [0|0] "" Vector__XXX
 SG_ VCSEC_TPMSAuthenticateFailureReason3 m19 : 43|3@1+ (1,0) [0|0] "" Vector__XXX
 SG_ VCSEC_TPMSSensorType0 m20 : 44|3@1+ (1,0) [0|0] "" Vector__XXX
 SG_ VCSEC_TPMSSensorType1 m21 : 44|3@1+ (1,0) [0|0] "" Vector__XXX
 SG_ VCSEC_TPMSSensorType2 m22 : 44|3@1+ (1,0) [0|0] "" Vector__XXX
 SG_ VCSEC_TPMSSensorType3 m23 : 44|3@1+ (1,0) [0|0] "" Vector__XXX
 SG_ VCSEC_TPMSDetailedAuthenticationStatus0 m16 : 48|4@1+ (1,0) [0|0] "" Vector__XXX
 SG_ VCSEC_TPMSDetailedAuthenticationStatus1 m17 : 48|4@1+ (1,0) [0|0] "" Vector__XXX
 SG_ VCSEC_TPMSDetailedAuthenticationStatus2 m18 : 48|4@1+ (1,0) [0|0] "" Vector__XXX
 SG_ VCSEC_TPMSDetailedAuthenticationStatus3 m19 : 48|4@1+ (1,0) [0|0] "" Vector__XXX
 SG_ VCSEC_TPMSTotalResetsDueToClockLoss0 m24 : 48|8@1+ (1,0) [0|0] "" Vector__XXX
 SG_ VCSEC_TPMSTotalResetsDueToClockLoss1 m26 : 48|8@1+ (1,0) [0|0] "" Vector__XXX
 SG_ VCSEC_TPMSTotalResetsDueToClockLoss2 m28 : 48|8@1+ (1,0) [0|0] "" Vector__XXX
 SG_ VCSEC_TPMSTotalResetsDueToClockLoss3 m30 : 48|8@1+ (1,0) [0|0] "" Vector__XXX
 SG_ VCSEC_TPMSTotalResetsDueToWatchdog0 m25 : 48|8@1+ (1,0) [0|0] "" Vector__XXX
 SG_ VCSEC_TPMSTotalResetsDueToWatchdog1 m27 : 48|8@1+ (1,0) [0|0] "" Vector__XXX
 SG_ VCSEC_TPMSTotalResetsDueToWatchdog2 m29 : 48|8@1+ (1,0) [0|0] "" Vector__XXX
 SG_ VCSEC_TPMSTotalResetsDueToWatchdog3 m31 : 48|8@1+ (1,0) [0|0] "" Vector__XXX
 SG_ VCSEC_BLEOtherFailuresCount0 m4 : 56|5@1+ (1,0) [0|0] "" Vector__XXX
 SG_ VCSEC_BLEOtherFailuresCount1 m6 : 56|5@1+ (1,0) [0|0] "" Vector__XXX
 SG_ VCSEC_BLEOtherFailuresCount2 m8 : 56|5@1+ (1,0) [0|0] "" Vector__XXX
 SG_ VCSEC_BLEOtherFailuresCount3 m10 : 56|5@1+ (1,0) [0|0] "" Vector__XXX
 SG_ VCSEC_TPMSTotalResetsDueToSystemReset0 m24 : 56|8@1+ (1,0) [0|0] "" Vector__XXX
 SG_ VCSEC_TPMSTotalResetsDueToSystemReset1 m26 : 56|8@1+ (1,0) [0|0] "" Vector__XXX
 SG_ VCSEC_TPMSTotalResetsDueToSystemReset2 m28 : 56|8@1+ (1,0) [0|0] "" Vector__XXX
 SG_ VCSEC_TPMSTotalResetsDueToSystemReset3 m30 : 56|8@1+ (1,0) [0|0] "" Vector__XXX
 SG_ VCSEC_TPMSTotalResetsDueToUnknown0 m25 : 56|8@1+ (1,0) [0|0] "" Vector__XXX
 SG_ VCSEC_TPMSTotalResetsDueToUnknown1 m27 : 56|8@1+ (1,0) [0|0] "" Vector__XXX
 SG_ VCSEC_TPMSTotalResetsDueToUnknown2 m29 : 56|8@1+ (1,0) [0|0] "" Vector__XXX
 SG_ VCSEC_TPMSTotalResetsDueToUnknown3 m31 : 56|8@1+ (1,0) [0|0] "" Vector__XXX

BO_ 574 PARK_oocStatus: 8 Vector__XXX
 SG_ PARK_oocDistance : 0|9@1+ (1,0) [0|0] "" Vector__XXX
 SG_ PARK_oocConfidence : 9|7@1+ (1,0) [0|0] "" Vector__XXX
 SG_ PARK_oocDirectEchoOnly : 16|1@1+ (1,0) [0|0] "" Vector__XXX
 SG_ PARK_oocVehicleX : 17|7@1+ (4,-114) [0|0] "" Vector__XXX
 SG_ PARK_oocVehicleY : 24|7@1+ (2,-128) [0|0] "" Vector__XXX
 SG_ PARK_oocCollisionSide : 31|3@1+ (1,0) [0|0] "" Vector__XXX
 SG_ PARK_oocUntrackedTime : 34|6@1+ (0.1,0) [0|0] "" Vector__XXX
 SG_ PARK_oocHeight : 40|2@1+ (1,0) [0|0] "" Vector__XXX
 SG_ PARK_oocOffCourse : 42|10@1+ (1,-512) [0|0] "" Vector__XXX
 SG_ PARK_oocStatusCounter : 52|4@1+ (1,0) [0|0] "" Vector__XXX
 SG_ PARK_oocStatusChecksum : 56|8@1+ (1,0) [0|0] "" Vector__XXX

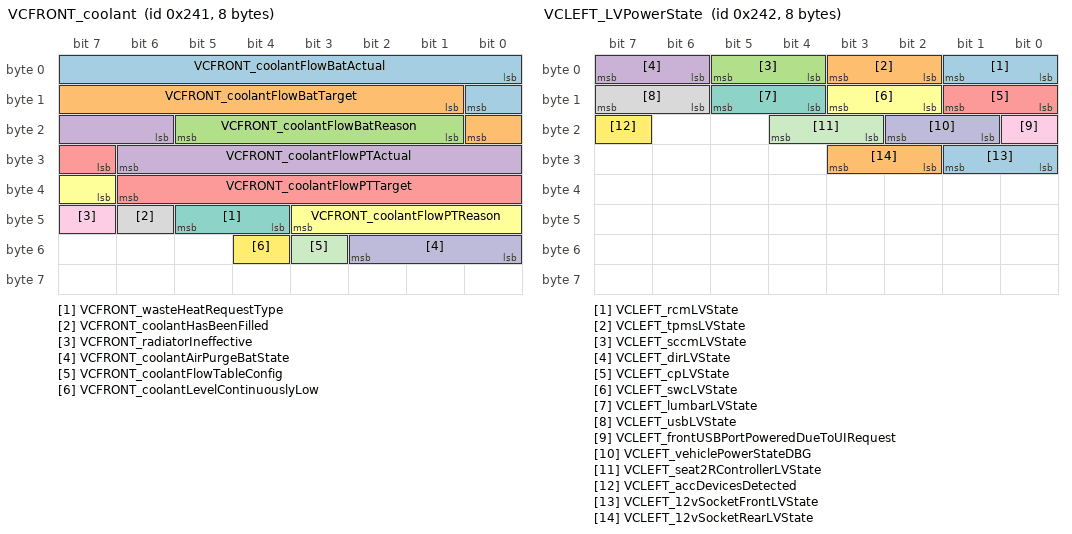
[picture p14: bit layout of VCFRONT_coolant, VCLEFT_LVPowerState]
BO_ 577 VCFRONT_coolant: 8 Vector__XXX
 SG_ VCFRONT_coolantFlowBatActual : 0|9@1+ (0.1,0) [0|0] "" Vector__XXX
 SG_ VCFRONT_coolantFlowBatTarget : 9|8@1+ (0.2,0) [0|0] "" Vector__XXX
 SG_ VCFRONT_coolantFlowBatReason : 17|5@1+ (1,0) [0|0] "" Vector__XXX
 SG_ VCFRONT_coolantFlowPTActual : 22|9@1+ (0.1,0) [0|0] "" Vector__XXX
 SG_ VCFRONT_coolantFlowPTTarget : 31|8@1+ (0.2,0) [0|0] "" Vector__XXX
 SG_ VCFRONT_coolantFlowPTReason : 39|5@1+ (1,0) [0|0] "" Vector__XXX
 SG_ VCFRONT_wasteHeatRequestType : 44|2@1+ (1,0) [0|0] "" Vector__XXX
 SG_ VCFRONT_coolantHasBeenFilled : 46|1@1+ (1,0) [0|0] "" Vector__XXX
 SG_ VCFRONT_radiatorIneffective : 47|1@1+ (1,0) [0|0] "" Vector__XXX
 SG_ VCFRONT_coolantAirPurgeBatState : 48|3@1+ (1,0) [0|0] "" Vector__XXX
 SG_ VCFRONT_coolantFlowTableConfig : 51|1@1+ (1,0) [0|0] "" Vector__XXX
 SG_ VCFRONT_coolantLevelContinuouslyLow : 52|1@1+ (1,0) [0|0] "" Vector__XXX

BO_ 578 VCLEFT_LVPowerState: 8 Vector__XXX
 SG_ VCLEFT_rcmLVState : 0|2@1+ (1,0) [0|0] "" Vector__XXX
 SG_ VCLEFT_tpmsLVState : 2|2@1+ (1,0) [0|0] "" Vector__XXX
 SG_ VCLEFT_sccmLVState : 4|2@1+ (1,0) [0|0] "" Vector__XXX
 SG_ VCLEFT_dirLVState : 6|2@1+ (1,0) [0|0] "" Vector__XXX
 SG_ VCLEFT_cpLVState : 8|2@1+ (1,0) [0|0] "" Vector__XXX
 SG_ VCLEFT_swcLVState : 10|2@1+ (1,0) [0|0] "" Vector__XXX
 SG_ VCLEFT_lumbarLVState : 12|2@1+ (1,0) [0|0] "" Vector__XXX
 SG_ VCLEFT_usbLVState : 14|2@1+ (1,0) [0|0] "" Vector__XXX
 SG_ VCLEFT_frontUSBPortPoweredDueToUIRequest : 16|1@1+ (1,0) [0|0] "" Vector__XXX
 SG_ VCLEFT_vehiclePowerStateDBG : 17|2@1+ (1,0) [0|0] "" Vector__XXX
 SG_ VCLEFT_seat2RControllerLVState : 19|2@1+ (1,0) [0|0] "" Vector__XXX
 SG_ VCLEFT_accDevicesDetected : 23|1@1+ (1,0) [0|0] "" Vector__XXX
 SG_ VCLEFT_12vSocketFrontLVState : 24|2@1+ (1,0) [0|0] "" Vector__XXX
 SG_ VCLEFT_12vSocketRearLVState : 26|2@1+ (1,0) [0|0] "" Vector__XXX

BO_ 579 VCRIGHT_hvacStatus: 8 Vector__XXX
 SG_ VCRIGHT_hvacStatusIndex M : 0|3@1+ (1,0) [0|0] "" Vector__XXX
 SG_ VCRIGHT_hvacFrontRightSeatHeatStatus m3 : 4|2@1+ (1,0) [0|0] "" Vector__XXX
 SG_ VCRIGHT_hvacSeatFrontLeftTempTarget m3 : 6|8@1+ (0.5,-40) [0|0] "" Vector__XXX
 SG_ VCRIGHT_autoSwingAvailable m4 : 9|1@1+ (1,0) [0|0] "" Vector__XXX
 SG_ VCRIGHT_enableTripleCameraFanPowerInSleep m2 : 9|1@1+ (1,0) [0|0] "" Vector__XXX
 SG_ VCRIGHT_foggingControllerResetReason m5 : 9|15@1+ (1,0) [0|0] "" Vector__XXX
 SG_ VCRIGHT_hvacRecircDoorPercent m1 : 10|6@1+ (1.6,0) [0|0] "" Vector__XXX
 SG_ VCRIGHT_tempDuctLeftUpper m4 : 10|8@1+ (0.5,-22) [0|0] "" Vector__XXX
 SG_ VCRIGHT_tempDuctRightUpper m2 : 10|8@1+ (0.5,-22) [0|0] "" Vector__XXX
 SG_ VCRIGHT_warmingUpStatus m0 : 10|5@1+ (3,7) [0|0] "" Vector__XXX
 SG_ VCRIGHT_hvacManualToAutoNotify m3 : 14|3@1+ (1,0) [0|0] "" Vector__XXX
 SG_ VCRIGHT_coolingDownStatus m0 : 15|5@1+ (3,7) [0|0] "" Vector__XXX
 SG_ VCRIGHT_tempDuctLeft m1 : 16|8@1+ (0.5,-22) [0|0] "" Vector__XXX
 SG_ VCRIGHT_hvacRequestsFullAuto m3 : 17|3@1+ (1,0) [0|0] "" Vector__XXX
 SG_ VCRIGHT_hpSplitTempsEnabled m2 : 18|1@1+ (1,0) [0|0] "" Vector__XXX
 SG_ VCRIGHT_hvacFrontLeftSeatHeatStatus m4 : 18|2@1+ (1,0) [0|0] "" Vector__XXX
 SG_ VCRIGHT_hvacEvapInletTempEstimate m2 : 19|10@1+ (0.13,-40) [0|0] "" Vector__XXX
 SG_ VCRIGHT_childModeHVACState m0 : 20|2@1+ (1,0) [0|0] "" Vector__XXX
 SG_ VCRIGHT_hvacQdotLeft m4 : 20|14@1+ (1,-8191) [0|0] "" Vector__XXX
 SG_ VCRIGHT_passengerPresentHvacCycle m3 : 21|1@1+ (1,0) [0|0] "" Vector__XXX
 SG_ VCRIGHT_dogModeState m0 : 22|4@1+ (1,0) [0|0] "" Vector__XXX
 SG_ VCRIGHT_hvacRequestsAutoIntake m3 : 22|1@1+ (1,0) [0|0] "" Vector__XXX
 SG_ VCRIGHT_hvacMassflowRefrigSystem m1 : 24|8@1+ (1,0) [0|0] "" Vector__XXX
 SG_ VCRIGHT_steeringWheelHeatStatus m3 : 24|2@1+ (1,0) [0|0] "" Vector__XXX
 SG_ VCRIGHT_autoDefogStatus m3 : 26|2@1+ (1,0) [0|0] "" Vector__XXX
 SG_ VCRIGHT_hvacCabinTempEstValid m0 : 26|1@1+ (1,0) [0|0] "" Vector__XXX
 SG_ VCRIGHT_COPNotRunningReasonFiltered m0 : 27|3@1+ (1,0) [0|0] "" Vector__XXX
 SG_ VCRIGHT_tempMonitorNotNominal m2 : 29|1@1+ (1,0) [0|0] "" Vector__XXX
 SG_ VCRIGHT_hvacCabinAtTempTarget m2 : 30|1@1+ (1,0) [0|0] "" Vector__XXX
 SG_ VCRIGHT_hvacCabinTempEst m0 : 30|11@1+ (0.1,-40) [0|0] "" Vector__XXX
 SG_ VCRIGHT_solarElevation m3 : 31|9@1- (0.5,0) [0|0] "" Vector__XXX
 SG_ VCRIGHT_blowerTorqueIndex m5 : 32|7@1+ (1,0) [0|0] "" Vector__XXX
 SG_ VCRIGHT_hvacAirflowReason m2 : 32|5@1+ (1,0) [0|0] "" Vector__XXX
 SG_ VCRIGHT_tempDuctRight m1 : 32|8@1+ (0.5,-22) [0|0] "" Vector__XXX
 SG_ VCRIGHT_hvacQdotRight m4 : 34|14@1+ (1,-8191) [0|0] "" Vector__XXX
 SG_ VCRIGHT_autoHvacBlowerShouldLimit m2 : 37|1@1+ (1,0) [0|0] "" Vector__XXX
 SG_ VCRIGHT_minsToSunrise m3 : 40|8@1+ (10,0) [0|0] "" Vector__XXX
 SG_ VCRIGHT_solarLoadOnVehicle m2 : 40|8@1+ (4,0) [0|0] "" Vector__XXX
 SG_ VCRIGHT_hvacAirDistributionMode m0 : 41|3@1+ (1,0) [0|0] "" Vector__XXX
 SG_ VCRIGHT_hvacBlowerSegment m0 : 44|4@1+ (1,0) [0|0] "" Vector__XXX
 SG_ VCRIGHT_hvacDuctTargetLeft m1 : 48|8@1+ (0.5,-40) [0|0] "" Vector__XXX
 SG_ VCRIGHT_hvacRecirc m0 : 48|2@1+ (1,0) [0|0] "" Vector__XXX
 SG_ VCRIGHT_minsToSunset m3 : 48|8@1+ (10,0) [0|0] "" Vector__XXX
 SG_ VCRIGHT_refrigDistCommanded m2 : 48|1@1+ (1,0) [0|0] "" Vector__XXX
 SG_ VCRIGHT_tempDuctLeftLower m4 : 48|8@1+ (0.5,-22) [0|0] "" Vector__XXX
 SG_ VCRIGHT_hvacACRunning m0 : 50|1@1+ (1,0) [0|0] "" Vector__XXX
 SG_ VCRIGHT_hvacPowerState m0 : 51|3@1+ (1,0) [0|0] "" Vector__XXX
 SG_ VCRIGHT_hvacRefHighPowerRequest m2 : 53|1@1+ (1,0) [0|0] "" Vector__XXX
 SG_ VCRIGHT_hvacVentStatus m0 : 54|2@1+ (1,0) [0|0] "" Vector__XXX
 SG_ VCRIGHT_windshieldCameraHeaterDutyRequest m2 : 54|5@1+ (5,0) [0|0] "" Vector__XXX
 SG_ VCRIGHT_hvacDuctTargetRight m1 : 56|8@1+ (0.5,-40) [0|0] "" Vector__XXX
 SG_ VCRIGHT_hvacLimitedReasonRight m3 : 56|3@1+ (1,0) [0|0] "" Vector__XXX
 SG_ VCRIGHT_hvacSecondRowState m0 : 56|3@1+ (1,0) [0|0] "" Vector__XXX
 SG_ VCRIGHT_tempDuctRightLower m4 : 56|8@1+ (0.5,-22) [0|0] "" Vector__XXX
 SG_ VCRIGHT_extendedHvacPerfTestSupportState m2 : 59|4@1+ (1,0) [0|0] "" Vector__XXX
 SG_ VCRIGHT_hvacLimitedReasonLeft m3 : 59|3@1+ (1,0) [0|0] "" Vector__XXX
 SG_ VCRIGHT_hvacSystemNominal m0 : 59|1@1+ (1,0) [0|0] "" Vector__XXX
 SG_ VCRIGHT_hvacModelInitStatus m0 : 60|4@1+ (1,0) [0|0] "" Vector__XXX
 SG_ VCRIGHT_hvacOverheatProtActive m3 : 63|1@1+ (1,0) [0|0] "" Vector__XXX

BO_ 580 FC_limits: 8 Vector__XXX
 SG_ FC_powerLimit : 0|13@1+ (0.062255859376,0) [0|0] "" Vector__XXX
 SG_ FC_currentLimit : 16|13@1+ (0.0732421875,0) [0|0] "" Vector__XXX
 SG_ FC_maxVoltageLimit : 32|13@1+ (0.07324218755,0) [0|0] "" Vector__XXX
 SG_ FC_minVoltageLimit : 48|13@1+ (0.0732421875,0) [0|0] "" Vector__XXX

BO_ 583 CMP_HVStatus: 8 Vector__XXX
 SG_ CMP_inputHVVoltage : 0|16@1+ (0.1,0) [0|0] "" Vector__XXX
 SG_ CMP_inputLVVoltage : 16|8@1+ (0.1,0) [0|0] "" Vector__XXX
 SG_ CMP_inputHVCurrent : 24|16@1+ (0.1,0) [0|0] "" Vector__XXX
 SG_ CMP_inputHVPower : 40|16@1+ (1,0) [0|0] "" Vector__XXX

BO_ 585 SCCM_leftStalk: 8 Vector__XXX
 SG_ SCCM_leftStalkCrc : 0|8@1+ (1,0) [0|0] "" Vector__XXX
 SG_ SCCM_leftStalkCounter : 8|4@1+ (1,0) [0|0] "" Vector__XXX
 SG_ SCCM_highBeamStalkStatus : 12|2@1+ (1,0) [0|0] "" Vector__XXX
 SG_ SCCM_washWipeButtonStatus : 14|2@1+ (1,0) [0|0] "" Vector__XXX
 SG_ SCCM_turnIndicatorStalkStatus : 16|4@1+ (1,0) [0|0] "" Vector__XXX
 SG_ SCCM_turnIndicatorStalkAngle : 20|12@1+ (0.1,-180) [0|0] "" Vector__XXX

BO_ 586 HVP_cpControl: 8 Vector__XXX
 SG_ HVP_cpDoorDriveEnable : 0|1@1+ (1,0) [0|0] "" Vector__XXX
 SG_ HVP_cpLatchDriveHwEnabled : 1|1@1+ (1,0) [0|0] "" Vector__XXX
 SG_ HVP_cpFaultLine : 2|1@1+ (1,0) [0|0] "" Vector__XXX

BO_ 594 BMS_powerAvailable: 8 Vector__XXX
 SG_ BMS_maxRegenPower : 0|16@1+ (0.01,0) [0|0] "" Vector__XXX
 SG_ BMS_maxDischargePower : 16|16@1+ (0.013,0) [0|0] "" Vector__XXX
 SG_ BMS_maxStationaryHeatPower : 32|10@1+ (0.01,0) [0|0] "" Vector__XXX
 SG_ BMS_powerLimitsState : 42|1@1+ (1,0) [0|0] "" Vector__XXX
 SG_ BMS_totalHvPowerBudget : 43|9@1+ (0.1,0) [0|0] "" Vector__XXX
 SG_ BMS_notEnoughPowerForHeatPump : 52|1@1+ (1,0) [0|0] "" Vector__XXX

BO_ 595 UI_ventPanelControlRequest: 8 Vector__XXX
 SG_ UI_ventPanelControlRequestIndex M : 0|1@1+ (1,0) [0|0] "" Vector__XXX
 SG_ UI_ventPanelLeftPositionX m0 : 8|8@1+ (0.5,0) [0|0] "" Vector__XXX
 SG_ UI_ventPanelLeftPositionY m0 : 16|8@1+ (0.5,0) [0|0] "" Vector__XXX
 SG_ UI_ventPanelLeftLateralSplit m0 : 24|8@1+ (0.5,0) [0|0] "" Vector__XXX
 SG_ UI_ventPanelRightPositionX m0 : 32|8@1+ (0.5,0) [0|0] "" Vector__XXX
 SG_ UI_ventPanelRightPositionY m0 : 40|8@1+ (0.5,0) [0|0] "" Vector__XXX
 SG_ UI_ventPanelRightLateralSplit m0 : 48|8@1+ (0.5,0) [0|0] "" Vector__XXX
 SG_ UI_ventPanelLeftLateralMode m0 : 56|2@1+ (1,0) [0|0] "" Vector__XXX
 SG_ UI_ventPanelRightLateralMode m0 : 58|2@1+ (1,0) [0|0] "" Vector__XXX
 SG_ UI_hvacReqActiveVents m0 : 60|2@1+ (1,0) [0|0] "" Vector__XXX

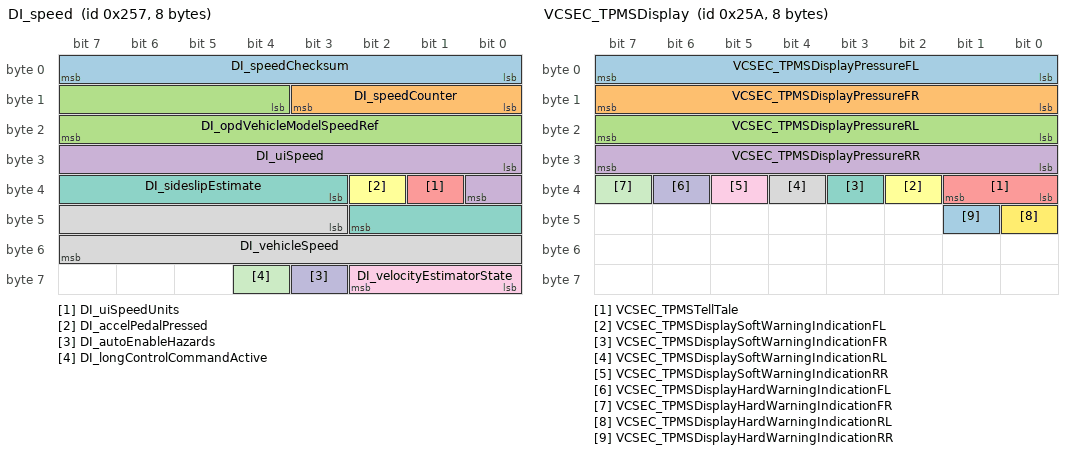
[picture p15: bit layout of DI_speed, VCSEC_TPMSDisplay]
BO_ 599 DI_speed: 8 Vector__XXX
 SG_ DI_speedChecksum : 0|8@1+ (1,0) [0|0] "" Vector__XXX
 SG_ DI_speedCounter : 8|4@1+ (1,0) [0|0] "" Vector__XXX
 SG_ DI_opdVehicleModelSpeedRef : 12|12@1+ (0.08,-40) [0|0] "" Vector__XXX
 SG_ DI_uiSpeed : 24|9@1+ (1,0) [0|0] "" Vector__XXX
 SG_ DI_uiSpeedUnits : 33|1@1+ (1,0) [0|0] "" Vector__XXX
 SG_ DI_accelPedalPressed : 34|1@1+ (1,0) [0|0] "" Vector__XXX
 SG_ DI_sideslipEstimate : 35|8@1- (0.0025,0) [0|0] "" Vector__XXX
 SG_ DI_vehicleSpeed : 43|13@1+ (0.08,-40) [0|0] "" Vector__XXX
 SG_ DI_velocityEstimatorState : 56|3@1+ (1,0) [0|0] "" Vector__XXX
 SG_ DI_autoEnableHazards : 59|1@1+ (1,0) [0|0] "" Vector__XXX
 SG_ DI_longControlCommandActive : 60|1@1+ (1,0) [0|0] "" Vector__XXX

BO_ 602 VCSEC_TPMSDisplay: 8 Vector__XXX
 SG_ VCSEC_TPMSDisplayPressureFL : 0|8@1+ (0.025,0) [0|0] "" Vector__XXX
 SG_ VCSEC_TPMSDisplayPressureFR : 8|8@1+ (0.025,0) [0|0] "" Vector__XXX
 SG_ VCSEC_TPMSDisplayPressureRL : 16|8@1+ (0.025,0) [0|0] "" Vector__XXX
 SG_ VCSEC_TPMSDisplayPressureRR : 24|8@1+ (0.025,0) [0|0] "" Vector__XXX
 SG_ VCSEC_TPMSTellTale : 32|2@1+ (1,0) [0|0] "" Vector__XXX
 SG_ VCSEC_TPMSDisplaySoftWarningIndicationFL : 34|1@1+ (1,0) [0|0] "" Vector__XXX
 SG_ VCSEC_TPMSDisplaySoftWarningIndicationFR : 35|1@1+ (1,0) [0|0] "" Vector__XXX
 SG_ VCSEC_TPMSDisplaySoftWarningIndicationRL : 36|1@1+ (1,0) [0|0] "" Vector__XXX
 SG_ VCSEC_TPMSDisplaySoftWarningIndicationRR : 37|1@1+ (1,0) [0|0] "" Vector__XXX
 SG_ VCSEC_TPMSDisplayHardWarningIndicationFL : 38|1@1+ (1,0) [0|0] "" Vector__XXX
 SG_ VCSEC_TPMSDisplayHardWarningIndicationFR : 39|1@1+ (1,0) [0|0] "" Vector__XXX
 SG_ VCSEC_TPMSDisplayHardWarningIndicationRL : 40|1@1+ (1,0) [0|0] "" Vector__XXX
 SG_ VCSEC_TPMSDisplayHardWarningIndicationRR : 41|1@1+ (1,0) [0|0] "" Vector__XXX

BO_ 603 APP_status: 8 Vector__XXX
 SG_ APP_watchdogState : 0|3@1+ (1,0) [0|0] "" Vector__XXX
 SG_ APP_fusedState : 3|2@1+ (1,0) [0|0] "" Vector__XXX
 SG_ APP_cameraHeaterRequest : 5|1@1+ (1,0) [0|0] "" Vector__XXX
 SG_ APP_factorySummonStatus : 6|4@1+ (1,0) [0|0] "" Vector__XXX
 SG_ APP_clipRecordingStatus : 10|3@1+ (1,0) [0|0] "" Vector__XXX
 SG_ APP_allowApActivationWithBrake : 13|1@1+ (1,0) [0|0] "" Vector__XXX
 SG_ APP_summonUnavailableReason : 14|5@1+ (1,0) [0|0] "" Vector__XXX
 SG_ APP_fsdSuspendState : 19|2@1+ (1,0) [0|0] "" Vector__XXX
 SG_ APP_fsdRevokeStrikeoutCount : 21|3@1+ (1,0) [0|0] "" Vector__XXX
 SG_ APP_teslaVisionSupported : 24|2@1+ (1,0) [0|0] "" Vector__XXX
 SG_ APP_teslaVisionUnsupportedReason : 26|3@1+ (1,0) [0|0] "" Vector__XXX
 SG_ APP_fsdRevokeCount : 29|3@1+ (1,0) [0|0] "" Vector__XXX
 SG_ APP_excessiveAccelPedalWarning : 32|1@1+ (1,0) [0|0] "" Vector__XXX
 SG_ APP_unifiedObjectStackSupported : 33|2@1+ (1,0) [0|0] "" Vector__XXX
 SG_ APP_sendingBUCStream : 35|1@1+ (1,0) [0|0] "" Vector__XXX
 SG_ APP_DDAWSystemStatus : 37|3@1+ (1,0) [0|0] "" Vector__XXX
 SG_ APP_socOperatingMode : 40|2@1+ (1,0) [0|0] "" Vector__XXX
 SG_ APP_summonVersionIdentifier : 42|2@1+ (1,0) [0|0] "" Vector__XXX
 SG_ APP_sentryState : 44|3@1+ (1,0) [0|0] "" Vector__XXX
 SG_ APP_autoparkVersionIdentifier : 47|2@1+ (1,0) [0|0] "" Vector__XXX
 SG_ APP_autonomySystemHealth : 49|1@1+ (1,0) [0|0] "" Vector__XXX
 SG_ APP_uiEthFailoverDisabled : 50|1@1+ (1,0) [0|0] "" Vector__XXX
 SG_ APP_suspendResumeAvailable : 51|1@1+ (1,0) [0|0] "" Vector__XXX
 SG_ APP_statusCounter : 52|4@1+ (1,0) [0|0] "" Vector__XXX
 SG_ APP_statusChecksum : 56|8@1+ (1,0) [0|0] "" Vector__XXX

BO_ 605 CP_status: 8 Vector__XXX
 SG_ CP_type : 0|2@1+ (1,0) [0|0] "" Vector__XXX
 SG_ CP_insertEnableLine : 2|1@1+ (1,0) [0|0] "" Vector__XXX
 SG_ CP_latchState : 3|2@1+ (1,0) [0|0] "" Vector__XXX
 SG_ CP_permanentPowerRequest : 5|1@1+ (1,0) [0|0] "" Vector__XXX
 SG_ CP_chargeDoorOpen : 6|1@1+ (1,0) [0|0] "" Vector__XXX
 SG_ CP_doorControlState : 8|3@1+ (1,0) [0|0] "" Vector__XXX
 SG_ CP_doorButtonPressed : 11|1@1+ (1,0) [0|0] "" Vector__XXX
 SG_ CP_swcanRelayClosed : 12|1@1+ (1,0) [0|0] "" Vector__XXX
 SG_ CP_inhibitOta : 13|1@1+ (1,0) [0|0] "" Vector__XXX
 SG_ CP_chargeCableState : 14|2@1+ (1,0) [0|0] "" Vector__XXX
 SG_ CP_latchControlState : 16|3@1+ (1,0) [0|0] "" Vector__XXX
 SG_ CP_ledColor : 19|4@1+ (1,0) [0|0] "" Vector__XXX
 SG_ CP_UHF_handleFound : 23|1@1+ (1,0) [0|0] "" Vector__XXX
 SG_ CP_faultLineSensed : 24|1@1+ (1,0) [0|0] "" Vector__XXX
 SG_ CP_doorPresenceState : 25|3@1+ (1,0) [0|0] "" Vector__XXX
 SG_ CP_inductiveSensorState : 28|3@1+ (1,0) [0|0] "" Vector__XXX
 SG_ CP_chargeDoorOpenUI : 31|1@1+ (1,0) [0|0] "" Vector__XXX
 SG_ CP_vehicleUnlockRequest : 32|1@1+ (1,0) [0|0] "" Vector__XXX
 SG_ CP_coldWeatherMode : 33|1@1+ (1,0) [0|0] "" Vector__XXX
 SG_ CP_latchEngaged : 34|1@1+ (1,0) [0|0] "" Vector__XXX
 SG_ CP_inletHeaterUiState : 37|3@1+ (1,0) [0|0] "" Vector__XXX
 SG_ CP_userEvseModelType : 40|4@1+ (1,0) [0|0] "" Vector__XXX
 SG_ CP_evseGridFormHardwareType : 44|4@1+ (1,0) [0|0] "" Vector__XXX

BO_ 609 VCFRONT_12VBatteryStatus: 8 Vector__XXX
 SG_ VCFRONT_12VBatteryStatusIndex M : 0|3@1+ (1,0) [0|0] "" Vector__XXX
 SG_ VCFRONT_12VBatteryTargetVoltage m2 : 3|13@1+ (0.01,0) [0|0] "" Vector__XXX
 SG_ VCFRONT_IBSFault m0 : 3|1@1+ (1,0) [0|0] "" Vector__XXX
 SG_ VCFRONT_IBSVoltageFiltered m3 : 3|14@1+ (0.005443676098,0) [0|0] "" Vector__XXX
 SG_ VCFRONT_batterySupportRequest m1 : 3|1@1+ (1,0) [0|0] "" Vector__XXX
 SG_ VCFRONT_targetCurrent m5 : 3|11@1+ (0.125,-127) [0|0] "" Vector__XXX
 SG_ VCFRONT_voltageProfile m4 : 3|2@1+ (1,0) [0|0] "" Vector__XXX
 SG_ VCFRONT_12VOverchargeCounter m0 : 4|4@1+ (1,0) [0|0] "" Vector__XXX
 SG_ VCFRONT_batterySMState m1 : 4|4@1+ (1,0) [0|0] "" Vector__XXX
 SG_ VCFRONT_IBSAmpHours m4 : 5|14@1- (0.005,0) [0|0] "" Vector__XXX
 SG_ VCFRONT_eFuseRecoveryStateDBG m1 : 8|3@1+ (1,0) [0|0] "" Vector__XXX
 SG_ VCFRONT_voltageDropCounter m0 : 8|4@1+ (1,0) [0|0] "" Vector__XXX
 SG_ VCFRONT_batteryLINScheduleDBG m1 : 11|3@1+ (1,0) [0|0] "" Vector__XXX
 SG_ VCFRONT_isVehicleSupported m0 : 12|1@1+ (1,0) [0|0] "" Vector__XXX
 SG_ VCFRONT_shortedCellFaultCounter m0 : 13|3@1+ (1,0) [0|0] "" Vector__XXX
 SG_ VCFRONT_PCSMia m5 : 14|1@1+ (1,0) [0|0] "" Vector__XXX
 SG_ VCFRONT_resistanceEstimationTestCounter m1 : 14|2@1+ (1,0) [0|0] "" Vector__XXX
 SG_ VCFRONT_chargeNeeded m5 : 15|1@1+ (1,0) [0|0] "" Vector__XXX
 SG_ VCFRONT_IBSCurrent m1 : 16|16@1- (0.005,0) [0|0] "" Vector__XXX
 SG_ VCFRONT_IBSCurrentFiltered m0 : 16|16@1- (0.005,0) [0|0] "" Vector__XXX
 SG_ VCFRONT_IBSTemperature m2 : 16|11@1+ (0.1,-24) [0|0] "" Vector__XXX
 SG_ VCFRONT_voltageControlLoopIntegrationVal m5 : 16|14@1+ (0.006,0) [0|0] "" Vector__XXX
 SG_ VCFRONT_LVBMS_LVBusVoltageSourceDBG m3 : 17|2@1+ (1,0) [0|0] "" Vector__XXX
 SG_ VCFRONT_IBSVoltageRawDBG m4 : 19|14@1+ (0.005443676098,0) [0|0] "" Vector__XXX
 SG_ VCFRONT_LVBMS_LVPackCurrentSourceDBG m3 : 19|2@1+ (1,0) [0|0] "" Vector__XXX
 SG_ VCFRONT_LVBatterySupportRqrdTrigger m3 : 24|14@1+ (1,0) [0|0] "" Vector__XXX
 SG_ VCFRONT_currentSensorMismatchLeakyBktPctDBG m2 : 27|7@1+ (2,0) [0|0] "" Vector__XXX
 SG_ VCFRONT_currentControlLoopIntegrationVal m5 : 30|14@1+ (0.006,0) [0|0] "" Vector__XXX
 SG_ VCFRONT_IBSVoltage m1 : 32|14@1+ (0.005443676098,0) [0|0] "" Vector__XXX
 SG_ VCFRONT_silentWakeIBSCurrent m0 : 32|12@1+ (0.125,-511.875) [0|0] "" Vector__XXX
 SG_ VCFRONT_LVBatteryLINCommsDetectedDBG m4 : 33|1@1+ (1,0) [0|0] "" Vector__XXX
 SG_ VCFRONT_voltageSensorMismatchLeakyBktPctDBG m4 : 34|7@1+ (2,0) [0|0] "" Vector__XXX
 SG_ VCFRONT_LVBatteryEnergyRemainingPCT m2 : 37|7@1+ (1,0) [0|0] "" Vector__XXX
 SG_ VCFRONT_goodForPCSPowerCycleLeakyBktDBG m3 : 40|5@1+ (0.0005,0) [0|0] "" Vector__XXX
 SG_ VCFRONT_LVBusControlMode m4 : 41|4@1+ (1,0) [0|0] "" Vector__XXX
 SG_ VCFRONT_LVBatteryStatusForDrive m2 : 44|2@1+ (1,0) [0|0] "" Vector__XXX
 SG_ VCFRONT_firstChargeOTA m0 : 44|1@1+ (1,0) [0|0] "" Vector__XXX
 SG_ VCFRONT_LVBusControlsFutile m3 : 45|1@1+ (1,0) [0|0] "" Vector__XXX
 SG_ VCFRONT_firstChargePOR m0 : 45|1@1+ (1,0) [0|0] "" Vector__XXX
 SG_ VCFRONT_good12VforUpdate : 46|1@1+ (1,0) [0|0] "" Vector__XXX
 SG_ VCFRONT_LVLoadRequest : 47|1@1+ (1,0) [0|0] "" Vector__XXX
 SG_ VCFRONT_LVBatteryType m2 : 48|3@1+ (1,0) [0|0] "" Vector__XXX
 SG_ VCFRONT_resistanceEstimationTestValid m3 : 48|1@1+ (1,0) [0|0] "" Vector__XXX
 SG_ VCFRONT_reverseBatteryFault m1 : 48|1@1+ (1,0) [0|0] "" Vector__XXX
 SG_ VCFRONT_voltageFloorReachedCounter m0 : 48|4@1+ (1,0) [0|0] "" Vector__XXX
 SG_ VCFRONT_LVBatterySupported m1 : 49|1@1+ (1,0) [0|0] "" Vector__XXX
 SG_ VCFRONT_resistanceEstimationTestsExpended m3 : 49|1@1+ (1,0) [0|0] "" Vector__XXX
 SG_ VCFRONT_LVBatteryCannotSupportVehicle m1 : 50|1@1+ (1,0) [0|0] "" Vector__XXX
 SG_ VCFRONT_LVBatteryFctryLimOverrideOk m4 : 50|1@1+ (1,0) [0|0] "" Vector__XXX
 SG_ VCFRONT_goodLVChargeForUpdate m3 : 50|1@1+ (1,0) [0|0] "" Vector__XXX
 SG_ VCFRONT_LVBatterySPICommsDetectedDBG m4 : 51|1@1+ (1,0) [0|0] "" Vector__XXX
 SG_ VCFRONT_goodTemp12VforUpdate m1 : 51|1@1+ (1,0) [0|0] "" Vector__XXX
 SG_ VCFRONT_opportunisticDCRTestNeeded m3 : 51|1@1+ (1,0) [0|0] "" Vector__XXX
 SG_ VCFRONT_resistanceEstimationNeeded m2 : 51|1@1+ (1,0) [0|0] "" Vector__XXX
 SG_ VCFRONT_12VBatteryStatusCounter : 52|4@1+ (1,0) [0|0] "" Vector__XXX
 SG_ VCFRONT_12VBatteryStatusChecksum : 56|8@1+ (1,0) [0|0] "" Vector__XXX

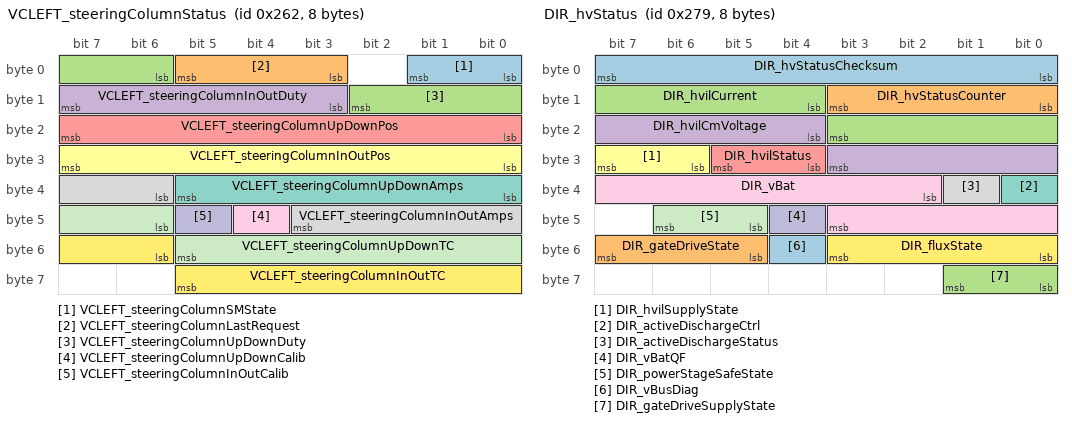
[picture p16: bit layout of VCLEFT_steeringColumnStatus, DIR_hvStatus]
BO_ 610 VCLEFT_steeringColumnStatus: 8 Vector__XXX
 SG_ VCLEFT_steeringColumnSMState : 0|2@1+ (1,0) [0|0] "" Vector__XXX
 SG_ VCLEFT_steeringColumnLastRequest : 3|3@1+ (1,0) [0|0] "" Vector__XXX
 SG_ VCLEFT_steeringColumnUpDownDuty : 6|5@1- (7,0) [0|0] "" Vector__XXX
 SG_ VCLEFT_steeringColumnInOutDuty : 11|5@1- (7,0) [0|0] "" Vector__XXX
 SG_ VCLEFT_steeringColumnUpDownPos : 16|8@1- (1,103) [0|0] "" Vector__XXX
 SG_ VCLEFT_steeringColumnInOutPos : 24|8@1- (1,103) [0|0] "" Vector__XXX
 SG_ VCLEFT_steeringColumnUpDownAmps : 32|6@1- (0.63,0) [0|0] "" Vector__XXX
 SG_ VCLEFT_steeringColumnInOutAmps : 38|6@1- (0.63,0) [0|0] "" Vector__XXX
 SG_ VCLEFT_steeringColumnUpDownCalib : 44|1@1+ (1,0) [0|0] "" Vector__XXX
 SG_ VCLEFT_steeringColumnInOutCalib : 45|1@1+ (1,0) [0|0] "" Vector__XXX
 SG_ VCLEFT_steeringColumnUpDownTC : 46|8@1+ (0.5,-10) [0|0] "" Vector__XXX
 SG_ VCLEFT_steeringColumnInOutTC : 54|8@1+ (0.5,-10) [0|0] "" Vector__XXX

BO_ 611 VCRIGHT_logging10Hz: 8 Vector__XXX
 SG_ VCRIGHT_logging10HzIndex M : 0|3@1+ (1,0) [0|0] "" Vector__XXX
 SG_ VCRIGHT_hvacLHBleedActuatorState m2 : 3|2@1+ (1,0) [0|0] "" Vector__XXX
 SG_ VCRIGHT_hvacLHBleedPosition m1 : 3|8@1+ (0.4,0) [0|0] "" Vector__XXX
 SG_ VCRIGHT_hvacLHBleedTarget m0 : 3|8@1+ (0.4,0) [0|0] "" Vector__XXX
 SG_ VCRIGHT_hvacRHBleedActuatorState m2 : 5|2@1+ (1,0) [0|0] "" Vector__XXX
 SG_ VCRIGHT_hvacLHVaneActuatorState m2 : 8|2@1+ (1,0) [0|0] "" Vector__XXX
 SG_ VCRIGHT_hvacRHVaneActuatorState m2 : 10|2@1+ (1,0) [0|0] "" Vector__XXX
 SG_ VCRIGHT_hvacRHBleedPosition m1 : 11|8@1+ (0.4,0) [0|0] "" Vector__XXX
 SG_ VCRIGHT_hvacRHBleedTarget m0 : 11|8@1+ (0.4,0) [0|0] "" Vector__XXX
 SG_ VCRIGHT_hvacUpperModeActState m2 : 12|2@1+ (1,0) [0|0] "" Vector__XXX
 SG_ VCRIGHT_hvacLowerModeActState m2 : 14|2@1+ (1,0) [0|0] "" Vector__XXX
 SG_ VCRIGHT_hvacIntakeActuatorState m2 : 16|2@1+ (1,0) [0|0] "" Vector__XXX
 SG_ VCRIGHT_hvacLHVanePosition m1 : 19|8@1+ (0.4,0) [0|0] "" Vector__XXX
 SG_ VCRIGHT_hvacLHVaneTarget m0 : 19|8@1+ (0.4,0) [0|0] "" Vector__XXX
 SG_ VCRIGHT_EvapPulldownBiasActive m2 : 20|1@1+ (1,0) [0|0] "" Vector__XXX
 SG_ VCRIGHT_tempDatLeftEst m2 : 21|9@1+ (0.5,-22) [0|0] "" Vector__XXX
 SG_ VCRIGHT_hvacRHVanePosition m1 : 27|8@1+ (0.4,0) [0|0] "" Vector__XXX
 SG_ VCRIGHT_hvacRHVaneTarget m0 : 27|8@1+ (0.4,0) [0|0] "" Vector__XXX
 SG_ VCRIGHT_tempDatRightEst m2 : 30|9@1+ (0.5,-22) [0|0] "" Vector__XXX
 SG_ VCRIGHT_hvacUpperModePosition m1 : 35|10@1+ (0.1,0) [0|0] "" Vector__XXX
 SG_ VCRIGHT_hvacUpperModeTarget m0 : 35|10@1+ (0.1,0) [0|0] "" Vector__XXX
 SG_ VCRIGHT_frontLeftSeatTempTargetQuasiSS m4 : 36|6@1+ (0.75,20) [0|0] "" Vector__XXX
 SG_ VCRIGHT_tempDuctLeftEst m2 : 40|8@1+ (0.5,-22) [0|0] "" Vector__XXX
 SG_ VCRIGHT_frontRightSeatTempTargetQuasiSS m4 : 42|6@1+ (1,20) [0|0] "" Vector__XXX
 SG_ VCRIGHT_hvacLowerModePosition m1 : 45|8@1+ (0.4,0) [0|0] "" Vector__XXX
 SG_ VCRIGHT_hvacLowerModeTarget m0 : 45|8@1+ (0.4,0) [0|0] "" Vector__XXX
 SG_ VCRIGHT_tempDuctRightEst m2 : 48|8@1+ (0.5,-22) [0|0] "" Vector__XXX
 SG_ VCRIGHT_hvacIntakePosition m1 : 53|8@1+ (0.4,0) [0|0] "" Vector__XXX
 SG_ VCRIGHT_hvacIntakeTarget m0 : 53|8@1+ (0.4,0) [0|0] "" Vector__XXX
 SG_ VCRIGHT_ptcHeaterBadRodDetectionState m2 : 56|4@1+ (1,0) [0|0] "" Vector__XXX
 SG_ VCRIGHT_windshieldRHExteriorSurface m3 : 56|8@1+ (1,0) [0|0] "" Vector__XXX

BO_ 612 PCS_chgLineStatus: 8 Vector__XXX
 SG_ PCS_chgInputVoltage : 0|14@1+ (0.033,0) [0|0] "" Vector__XXX
 SG_ PCS_chgLineCurrent : 14|9@1+ (0.1,0) [0|0] "" Vector__XXX
 SG_ PCS_chgAcVoltagePresent : 23|1@1+ (1,0) [0|0] "" Vector__XXX
 SG_ PCS_chgInputPower : 24|8@1+ (0.1,0) [0|0] "" Vector__XXX
 SG_ PCS_chgAcCurrentLimit : 32|10@1+ (0.1,0) [0|0] "" Vector__XXX

BO_ 614 DIR_power: 8 Vector__XXX
 SG_ DIR_elecPower : 0|11@1- (0.5,0) [0|0] "" Vector__XXX
 SG_ DIR_heatPowerOptimal : 16|8@1+ (0.08,0) [0|0] "" Vector__XXX
 SG_ DIR_heatPowerMax : 24|8@1+ (0.08,0) [0|0] "" Vector__XXX
 SG_ DIR_heatPowerActual : 32|8@1+ (0.08,0) [0|0] "" Vector__XXX
 SG_ DIR_excessHeatCommand : 40|8@1+ (0.08,0) [0|0] "" Vector__XXX
 SG_ DIR_drivePowerMax : 48|9@1+ (1,0) [0|0] "" Vector__XXX

BO_ 615 DIR_powerSlow: 8 Vector__XXX
 SG_ DIR_elecPowerSlow : 0|11@1- (0.5,0) [0|0] "" Vector__XXX
 SG_ DIR_heatPowerOptimalSlow : 16|8@1+ (0.08,0) [0|0] "" Vector__XXX
 SG_ DIR_heatPowerMaxSlow : 24|8@1+ (0.08,0) [0|0] "" Vector__XXX
 SG_ DIR_heatPowerActualSlow : 32|8@1+ (0.08,0) [0|0] "" Vector__XXX
 SG_ DIR_excessHeatCommandSlow : 40|8@1+ (0.08,0) [0|0] "" Vector__XXX
 SG_ DIR_drivePowerMaxSlow : 48|9@1+ (1,0) [0|0] "" Vector__XXX

BO_ 616 DI_systemPower: 8 Vector__XXX
 SG_ DI_sysHeatPowerMax : 0|8@1+ (0.08,0) [0|0] "" Vector__XXX
 SG_ DI_sysHeatPowerActual : 8|8@1+ (0.08,0) [0|0] "" Vector__XXX
 SG_ DI_sysDrivePowerMax : 16|10@1+ (1,0) [0|0] "" Vector__XXX
 SG_ DI_primaryUnitSiliconType : 26|1@1+ (1,0) [0|0] "" Vector__XXX
 SG_ DI_sysRegenPowerMax : 32|8@1+ (1,-100) [0|0] "" Vector__XXX

BO_ 626 VCLEFT_epbmDebug: 8 Vector__XXX
 SG_ VCLEFT_epbmDebugIndex M : 0|1@1+ (1,0) [0|0] "" Vector__XXX
 SG_ VCLEFT_epbmCaliperState m0 : 1|3@1+ (1,0) [0|0] "" Vector__XXX
 SG_ VCLEFT_epbmOpenAllowed m1 : 1|1@1+ (1,0) [0|0] "" Vector__XXX
 SG_ VCLEFT_epbmDynamicAllowed m1 : 2|1@1+ (1,0) [0|0] "" Vector__XXX
 SG_ VCLEFT_epbmParkAllowed m1 : 3|1@1+ (1,0) [0|0] "" Vector__XXX
 SG_ VCLEFT_epbmMotorEnabled m0 : 4|1@1+ (1,0) [0|0] "" Vector__XXX
 SG_ VCLEFT_epbmStartAllowed m1 : 4|1@1+ (1,0) [0|0] "" Vector__XXX
 SG_ VCLEFT_epbMotorCurrent m0 : 5|11@1+ (0.01,0) [0|0] "" Vector__XXX
 SG_ VCLEFT_epbmServiceAllowed m1 : 5|1@1+ (1,0) [0|0] "" Vector__XXX
 SG_ VCLEFT_epbmWinchAllowed m1 : 6|1@1+ (1,0) [0|0] "" Vector__XXX
 SG_ VCLEFT_epbmWinchReleaseAllowed m1 : 7|1@1+ (1,0) [0|0] "" Vector__XXX
 SG_ VCLEFT_epbmParkingAllowed m1 : 8|1@1+ (1,0) [0|0] "" Vector__XXX
 SG_ VCLEFT_epbmDynApplyingAllowed m1 : 9|1@1+ (1,0) [0|0] "" Vector__XXX
 SG_ VCLEFT_epbmReleasingAllowed m1 : 10|1@1+ (1,0) [0|0] "" Vector__XXX
 SG_ VCLEFT_epbmFaultAllowed m1 : 11|1@1+ (1,0) [0|0] "" Vector__XXX
 SG_ VCLEFT_epbmSummonAllowed m1 : 12|1@1+ (1,0) [0|0] "" Vector__XXX
 SG_ VCLEFT_epbmSummonParkAllowed m1 : 13|1@1+ (1,0) [0|0] "" Vector__XXX
 SG_ VCLEFT_epbmSummonReleaseAllowed m1 : 14|1@1+ (1,0) [0|0] "" Vector__XXX
 SG_ VCLEFT_summonInitAllowed m1 : 15|1@1+ (1,0) [0|0] "" Vector__XXX
 SG_ VCLEFT_epbmApplyVoltage m0 : 16|11@1+ (0.01,0) [0|0] "" Vector__XXX
 SG_ VCLEFT_epbmUnknownAllowed m1 : 16|1@1+ (1,0) [0|0] "" Vector__XXX
 SG_ VCLEFT_summonIdleAllowed m1 : 17|1@1+ (1,0) [0|0] "" Vector__XXX
 SG_ VCLEFT_summonArmedAllowed m1 : 18|1@1+ (1,0) [0|0] "" Vector__XXX
 SG_ VCLEFT_summonActiveAllowed m1 : 19|1@1+ (1,0) [0|0] "" Vector__XXX
 SG_ VCLEFT_summonCompleteAllowed m1 : 20|1@1+ (1,0) [0|0] "" Vector__XXX
 SG_ VCLEFT_summonFaultAllowed m1 : 21|1@1+ (1,0) [0|0] "" Vector__XXX
 SG_ VCLEFT_summonUnavailableAllowed m1 : 22|1@1+ (1,0) [0|0] "" Vector__XXX
 SG_ VCLEFT_activeDecelAllowedLatch m1 : 23|1@1+ (1,0) [0|0] "" Vector__XXX
 SG_ VCLEFT_epbmReleaseVoltage m0 : 27|11@1+ (0.01,0) [0|0] "" Vector__XXX
 SG_ VCLEFT_summonFaultReason m0 : 38|5@1+ (1,0) [0|0] "" Vector__XXX
 SG_ VCLEFT_epbSummonState m0 : 43|3@1+ (1,0) [0|0] "" Vector__XXX
 SG_ VCLEFT_epbmSummonState m0 : 46|3@1+ (1,0) [0|0] "" Vector__XXX
 SG_ VCLEFT_epbUnitStatus m0 : 49|5@1+ (1,0) [0|0] "" Vector__XXX
 SG_ VCLEFT_epbmFaultStatus m0 : 54|2@1+ (1,0) [0|0] "" Vector__XXX
 SG_ VCLEFT_epbFaultStatus m0 : 56|2@1+ (1,0) [0|0] "" Vector__XXX
 SG_ VCLEFT_epbmSystemStatus m0 : 58|4@1+ (1,0) [0|0] "" Vector__XXX
 SG_ VCLEFT_epbmAutonomyBehavior m0 : 62|2@1+ (1,0) [0|0] "" Vector__XXX

BO_ 627 UI_vehicleControl: 8 Vector__XXX
 SG_ UI_powerStateRequest : 0|2@1+ (1,0) [0|0] "" Vector__XXX
 SG_ UI_childDoorLockOnRight : 2|1@1+ (1,0) [0|0] "" Vector__XXX
 SG_ UI_frontFogSwitch : 3|1@1+ (1,0) [0|0] "" Vector__XXX
 SG_ UI_summonActive : 4|1@1+ (1,0) [0|0] "" Vector__XXX
 SG_ UI_frunkRequest : 5|1@1+ (1,0) [0|0] "" Vector__XXX
 SG_ UI_wiperMode : 6|2@1+ (1,0) [0|0] "" Vector__XXX
 SG_ UI_steeringBacklightEnabled : 8|1@1+ (1,0) [0|0] "" Vector__XXX
 SG_ UI_steeringButtonMode : 9|3@1+ (1,0) [0|0] "" Vector__XXX
 SG_ UI_walkUpUnlock : 12|1@1+ (1,0) [0|0] "" Vector__XXX
 SG_ UI_walkAwayLock : 13|1@1+ (1,0) [0|0] "" Vector__XXX
 SG_ UI_unlockOnPark : 14|1@1+ (1,0) [0|0] "" Vector__XXX
 SG_ UI_globalUnlockOn : 15|1@1+ (1,0) [0|0] "" Vector__XXX
 SG_ UI_childDoorLockOnLeft : 16|1@1+ (1,0) [0|0] "" Vector__XXX
 SG_ UI_lockRequest : 17|3@1+ (1,0) [0|0] "" Vector__XXX
 SG_ UI_alarmEnabled : 20|1@1+ (1,0) [0|0] "" Vector__XXX
 SG_ UI_intrusionSensorOn : 21|1@1+ (1,0) [0|0] "" Vector__XXX
 SG_ UI_stop12vSupport : 22|1@1+ (1,0) [0|0] "" Vector__XXX
 SG_ UI_rearFogSwitch : 23|1@1+ (1,0) [0|0] "" Vector__XXX
 SG_ UI_mirrorFoldRequest : 24|2@1+ (1,0) [0|0] "" Vector__XXX
 SG_ UI_mirrorHeatRequest : 26|1@1+ (1,0) [0|0] "" Vector__XXX
 SG_ UI_remoteStartRequest : 27|3@1+ (1,0) [0|0] "" Vector__XXX
 SG_ UI_seeYouHomeLightingOn : 30|1@1+ (1,0) [0|0] "" Vector__XXX
 SG_ UI_powerOff : 31|1@1+ (1,0) [0|0] "" Vector__XXX
 SG_ UI_displayBrightnessLevel : 32|8@1+ (0.5,0) [0|0] "" Vector__XXX
 SG_ UI_ambientLightingEnabled : 40|1@1+ (1,0) [0|0] "" Vector__XXX
 SG_ UI_autoHighBeamEnabled : 41|1@1+ (1,0) [0|0] "" Vector__XXX
 SG_ UI_frontLeftSeatHeatReq : 42|2@1+ (1,0) [0|0] "" Vector__XXX
 SG_ UI_frontRightSeatHeatReq : 44|2@1+ (1,0) [0|0] "" Vector__XXX
 SG_ UI_rearLeftSeatHeatReq : 46|2@1+ (1,0) [0|0] "" Vector__XXX
 SG_ UI_rearCenterSeatHeatReq : 48|2@1+ (1,0) [0|0] "" Vector__XXX
 SG_ UI_rearRightSeatHeatReq : 50|2@1+ (1,0) [0|0] "" Vector__XXX
 SG_ UI_autoFoldMirrorsOn : 52|1@1+ (1,0) [0|0] "" Vector__XXX
 SG_ UI_mirrorDipOnReverse : 53|1@1+ (1,0) [0|0] "" Vector__XXX
 SG_ UI_remoteClosureRequest : 54|2@1+ (1,0) [0|0] "" Vector__XXX
 SG_ UI_wiperRequest : 56|3@1+ (1,0) [0|0] "" Vector__XXX
 SG_ UI_domeLightSwitch : 59|2@1+ (1,0) [0|0] "" Vector__XXX
 SG_ UI_honkHorn : 61|1@1+ (1,0) [0|0] "" Vector__XXX
 SG_ UI_driveStateRequest : 62|1@1+ (1,0) [0|0] "" Vector__XXX
 SG_ UI_rearWindowLockout : 63|1@1+ (1,0) [0|0] "" Vector__XXX

BO_ 630 DI_authenticityMsg: 8 Vector__XXX
 SG_ DI_authenticityCommand : 0|8@1+ (1,0) [0|0] "" Vector__XXX
 SG_ DI_salt1 : 8|8@1+ (1,0) [0|0] "" Vector__XXX
 SG_ DI_salt2 : 16|8@1+ (1,0) [0|0] "" Vector__XXX
 SG_ DI_salt3 : 24|8@1+ (1,0) [0|0] "" Vector__XXX
 SG_ DI_salt4 : 32|8@1+ (1,0) [0|0] "" Vector__XXX
 SG_ DI_salt5 : 40|8@1+ (1,0) [0|0] "" Vector__XXX
 SG_ DI_salt6 : 48|8@1+ (1,0) [0|0] "" Vector__XXX
 SG_ DI_salt7 : 56|8@1+ (1,0) [0|0] "" Vector__XXX

BO_ 633 DIR_hvStatus: 8 Vector__XXX
 SG_ DIR_hvStatusChecksum : 0|8@1+ (1,0) [0|0] "" Vector__XXX
 SG_ DIR_hvStatusCounter : 8|4@1+ (1,0) [0|0] "" Vector__XXX
 SG_ DIR_hvilCurrent : 12|8@1+ (0.1,0) [0|0] "" Vector__XXX
 SG_ DIR_hvilCmVoltage : 20|8@1+ (0.08,0) [0|0] "" Vector__XXX
 SG_ DIR_hvilStatus : 28|2@1+ (1,0) [0|0] "" Vector__XXX
 SG_ DIR_hvilSupplyState : 30|2@1+ (1,0) [0|0] "" Vector__XXX
 SG_ DIR_activeDischargeCtrl : 32|1@1+ (1,0) [0|0] "" Vector__XXX
 SG_ DIR_activeDischargeStatus : 33|1@1+ (1,0) [0|0] "" Vector__XXX
 SG_ DIR_vBat : 34|10@1+ (1,0) [0|0] "" Vector__XXX
 SG_ DIR_vBatQF : 44|1@1+ (1,0) [0|0] "" Vector__XXX
 SG_ DIR_powerStageSafeState : 45|2@1+ (1,0) [0|0] "" Vector__XXX
 SG_ DIR_fluxState : 48|4@1+ (1,0) [0|0] "" Vector__XXX
 SG_ DIR_vBusDiag : 52|1@1+ (1,0) [0|0] "" Vector__XXX
 SG_ DIR_gateDriveState : 53|3@1+ (1,0) [0|0] "" Vector__XXX
 SG_ DIR_gateDriveSupplyState : 56|2@1+ (1,0) [0|0] "" Vector__XXX

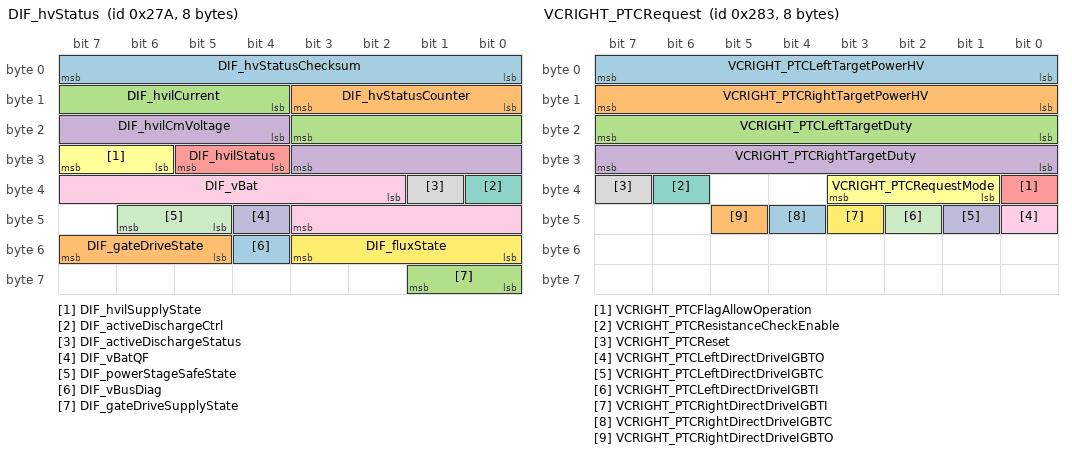
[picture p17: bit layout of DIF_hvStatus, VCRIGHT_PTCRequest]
BO_ 634 DIF_hvStatus: 8 Vector__XXX
 SG_ DIF_hvStatusChecksum : 0|8@1+ (1,0) [0|0] "" Vector__XXX
 SG_ DIF_hvStatusCounter : 8|4@1+ (1,0) [0|0] "" Vector__XXX
 SG_ DIF_hvilCurrent : 12|8@1+ (0.1,0) [0|0] "" Vector__XXX
 SG_ DIF_hvilCmVoltage : 20|8@1+ (0.08,0) [0|0] "" Vector__XXX
 SG_ DIF_hvilStatus : 28|2@1+ (1,0) [0|0] "" Vector__XXX
 SG_ DIF_hvilSupplyState : 30|2@1+ (1,0) [0|0] "" Vector__XXX
 SG_ DIF_activeDischargeCtrl : 32|1@1+ (1,0) [0|0] "" Vector__XXX
 SG_ DIF_activeDischargeStatus : 33|1@1+ (1,0) [0|0] "" Vector__XXX
 SG_ DIF_vBat : 34|10@1+ (1,0) [0|0] "" Vector__XXX
 SG_ DIF_vBatQF : 44|1@1+ (1,0) [0|0] "" Vector__XXX
 SG_ DIF_powerStageSafeState : 45|2@1+ (1,0) [0|0] "" Vector__XXX
 SG_ DIF_fluxState : 48|4@1+ (1,0) [0|0] "" Vector__XXX
 SG_ DIF_vBusDiag : 52|1@1+ (1,0) [0|0] "" Vector__XXX
 SG_ DIF_gateDriveState : 53|3@1+ (1,0) [0|0] "" Vector__XXX
 SG_ DIF_gateDriveSupplyState : 56|2@1+ (1,0) [0|0] "" Vector__XXX

BO_ 637 CP_dcChargeLimits: 8 Vector__XXX
 SG_ CP_evseMaxDcCurrentLimit : 0|13@1+ (0.25,0) [0|0] "" Vector__XXX
 SG_ CP_evseMinDcCurrentLimit : 13|12@1+ (0.5,0) [0|0] "" Vector__XXX
 SG_ CP_evseMaxDcVoltageLimit : 25|13@1+ (0.07324218755,0) [0|0] "" Vector__XXX
 SG_ CP_evseMinDcVoltageLimit : 38|13@1+ (0.07324218755,0) [0|0] "" Vector__XXX
 SG_ CP_evseInstantDcCurrentLimit : 51|12@1+ (0.5,0) [0|0] "" Vector__XXX
 SG_ CP_dcChargeLimitsContentValid : 63|1@1+ (1,0) [0|0] "" Vector__XXX

BO_ 641 VCFRONT_CMPRequest: 8 Vector__XXX
 SG_ VCFRONT_CMPTargetDuty : 0|16@1+ (0.1,0) [0|0] "" Vector__XXX
 SG_ VCFRONT_CMPPowerLimit : 16|16@1+ (1,0) [0|0] "" Vector__XXX
 SG_ VCFRONT_CMPReset : 32|8@1+ (1,0) [0|0] "" Vector__XXX
 SG_ VCFRONT_CMPEnable : 40|1@1+ (1,0) [0|0] "" Vector__XXX

BO_ 642 VCLEFT_hvacBlowerFeedback: 8 Vector__XXX
 SG_ VCLEFT_hvacBlowerFeedbackIndex M : 0|1@1+ (1,0) [0|0] "" Vector__XXX
 SG_ VCLEFT_hvacBlowerEnabled m0 : 2|1@1+ (1,0) [0|0] "" Vector__XXX
 SG_ VCLEFT_hvacBlowerOutputDuty m0 : 3|7@1+ (1,0) [0|0] "" Vector__XXX
 SG_ VCLEFT_hvacBlowerRPMTarget m0 : 10|10@1+ (10,0) [0|0] "" Vector__XXX
 SG_ VCLEFT_hvacBlowerRPMActual m0 : 20|10@1+ (10,0) [0|0] "" Vector__XXX
 SG_ VCLEFT_hvacBlowerTorque m0 : 34|10@1+ (0.006,-1.5) [0|0] "" Vector__XXX
 SG_ VCLEFT_hvacBlowerFETTemp m0 : 44|7@1+ (2,-50) [0|0] "" Vector__XXX
 SG_ VCLEFT_hvacBlowerIDc m0 : 51|7@1+ (0.5,0) [0|0] "" Vector__XXX
 SG_ VCLEFT_hvacBlowerInitd m0 : 58|1@1+ (1,0) [0|0] "" Vector__XXX
 SG_ VCLEFT_hvacBlowerFault m0 : 59|1@1+ (1,0) [0|0] "" Vector__XXX
 SG_ VCLEFT_hvacBlowerLimitFETTemps m0 : 60|1@1+ (1,0) [0|0] "" Vector__XXX
 SG_ VCLEFT_hvacBlowerPowerOn m0 : 61|1@1+ (1,0) [0|0] "" Vector__XXX

BO_ 643 VCRIGHT_PTCRequest: 8 Vector__XXX
 SG_ VCRIGHT_PTCLeftTargetPowerHV : 0|8@1+ (30,0) [0|0] "" Vector__XXX
 SG_ VCRIGHT_PTCRightTargetPowerHV : 8|8@1+ (30,0) [0|0] "" Vector__XXX
 SG_ VCRIGHT_PTCLeftTargetDuty : 16|8@1+ (0.5,0) [0|0] "" Vector__XXX
 SG_ VCRIGHT_PTCRightTargetDuty : 24|8@1+ (0.5,0) [0|0] "" Vector__XXX
 SG_ VCRIGHT_PTCFlagAllowOperation : 32|1@1+ (1,0) [0|0] "" Vector__XXX
 SG_ VCRIGHT_PTCRequestMode : 33|3@1+ (1,0) [0|0] "" Vector__XXX
 SG_ VCRIGHT_PTCResistanceCheckEnable : 38|1@1+ (1,0) [0|0] "" Vector__XXX
 SG_ VCRIGHT_PTCReset : 39|1@1+ (1,0) [0|0] "" Vector__XXX
 SG_ VCRIGHT_PTCLeftDirectDriveIGBTO : 40|1@1+ (1,0) [0|0] "" Vector__XXX
 SG_ VCRIGHT_PTCLeftDirectDriveIGBTC : 41|1@1+ (1,0) [0|0] "" Vector__XXX
 SG_ VCRIGHT_PTCLeftDirectDriveIGBTI : 42|1@1+ (1,0) [0|0] "" Vector__XXX
 SG_ VCRIGHT_PTCRightDirectDriveIGBTI : 43|1@1+ (1,0) [0|0] "" Vector__XXX
 SG_ VCRIGHT_PTCRightDirectDriveIGBTC : 44|1@1+ (1,0) [0|0] "" Vector__XXX
 SG_ VCRIGHT_PTCRightDirectDriveIGBTO : 45|1@1+ (1,0) [0|0] "" Vector__XXX

BO_ 644 UI_vehicleModes: 8 Vector__XXX
 SG_ UI_factoryMode : 0|1@1+ (1,0) [0|0] "" Vector__XXX
 SG_ UI_transportMode : 1|1@1+ (1,0) [0|0] "" Vector__XXX
 SG_ UI_showroomMode : 2|1@1+ (1,0) [0|0] "" Vector__XXX
 SG_ UI_serviceMode : 3|1@1+ (1,0) [0|0] "" Vector__XXX
 SG_ UI_isDelivered : 4|1@1+ (1,0) [0|0] "" Vector__XXX
 SG_ UI_hasEverBeenDelivered : 5|1@1+ (1,0) [0|0] "" Vector__XXX
 SG_ UI_homelinkV2Command0 : 8|8@1+ (1,0) [0|0] "" Vector__XXX
 SG_ UI_homelinkV2Command1 : 16|8@1+ (1,0) [0|0] "" Vector__XXX
 SG_ UI_homelinkV2Command2 : 24|8@1+ (1,0) [0|0] "" Vector__XXX
 SG_ UI_carWashMode : 32|1@1+ (1,0) [0|0] "" Vector__XXX
 SG_ UI_valetMode : 33|1@1+ (1,0) [0|0] "" Vector__XXX
 SG_ UI_gameMode : 34|1@1+ (1,0) [0|0] "" Vector__XXX
 SG_ UI_diagnosticsAllowed : 35|1@1+ (1,0) [0|0] "" Vector__XXX
 SG_ UI_serviceModePlus : 36|1@1+ (1,0) [0|0] "" Vector__XXX
 SG_ UI_premiumAmpPowerOff : 37|1@1+ (1,0) [0|0] "" Vector__XXX
 SG_ UI_signedCmdHardLocked : 38|1@1+ (1,0) [0|0] "" Vector__XXX
 SG_ UI_signedCmdServiceMode : 39|1@1+ (1,0) [0|0] "" Vector__XXX
 SG_ UI_closureEasterEggStatus : 40|2@1+ (1,0) [0|0] "" Vector__XXX
 SG_ UI_lightShowType : 42|3@1+ (1,0) [0|0] "" Vector__XXX
 SG_ UI_sohTestRequest : 45|1@1+ (1,0) [0|0] "" Vector__XXX
 SG_ UI_upkeepMode : 46|1@1+ (1,0) [0|0] "" Vector__XXX
 SG_ UI_vehicleModesCounter : 52|4@1+ (1,0) [0|0] "" Vector__XXX
 SG_ UI_vehicleModesChecksum : 56|8@1+ (1,0) [0|0] "" Vector__XXX

BO_ 645 UI_driverProfileRecall: 8 Vector__XXX
 SG_ UI_driverProfileRecallIndex M : 0|3@1+ (1,0) [0|0] "" Vector__XXX
 SG_ UI_driverProfileRecallStop : 3|1@1+ (1,0) [0|0] "" Vector__XXX
 SG_ UI_columnAndLumbarRecallActive m2 : 4|1@1+ (1,0) [0|0] "" Vector__XXX
 SG_ UI_frontSeatRecallActive m1 : 4|1@1+ (1,0) [0|0] "" Vector__XXX
 SG_ UI_mirrorRecallActive m4 : 4|1@1+ (1,0) [0|0] "" Vector__XXX
 SG_ UI_customMirrorDipPositionsSet m4 : 5|1@1+ (1,0) [0|0] "" Vector__XXX
 SG_ UI_frontSeatTrackPos m1 : 5|10@1- (4,0) [0|0] "" Vector__XXX
 SG_ UI_leftMirrorDipXPosition m4 : 8|8@1+ (0.02,0) [0|0] "" Vector__XXX
 SG_ UI_leftMirrorTiltXPosition m3 : 8|8@1+ (0.02,0) [0|0] "" Vector__XXX
 SG_ UI_steeringColumnUpDownPos m2 : 8|8@1- (1,103) [0|0] "" Vector__XXX
 SG_ UI_frontSeatBackPos m1 : 16|12@1- (0.1,0) [0|0] "" Vector__XXX
 SG_ UI_leftMirrorDipYPosition m4 : 16|8@1+ (0.02,0) [0|0] "" Vector__XXX
 SG_ UI_leftMirrorTiltYPosition m3 : 16|8@1+ (0.02,0) [0|0] "" Vector__XXX
 SG_ UI_lumbarAPressurePercentage m2 : 16|7@1+ (1,0) [0|0] "" Vector__XXX
 SG_ UI_rightMirrorDipXPosition m4 : 24|8@1+ (0.02,0) [0|0] "" Vector__XXX
 SG_ UI_rightMirrorTiltXPosition m3 : 24|8@1+ (0.02,0) [0|0] "" Vector__XXX
 SG_ UI_frontSeatLiftPos m1 : 32|10@1- (4,0) [0|0] "" Vector__XXX
 SG_ UI_lumbarBPressurePercentage m2 : 32|7@1+ (1,0) [0|0] "" Vector__XXX
 SG_ UI_rightMirrorDipYPosition m4 : 32|8@1+ (0.02,0) [0|0] "" Vector__XXX
 SG_ UI_rightMirrorTiltYPosition m3 : 32|8@1+ (0.02,0) [0|0] "" Vector__XXX
 SG_ UI_modifyMirrorDipRequest m4 : 40|2@1+ (1,0) [0|0] "" Vector__XXX
 SG_ UI_frontSeatTiltPos m1 : 48|12@1- (0.1,0) [0|0] "" Vector__XXX
 SG_ UI_steeringColumnInOutPos m2 : 48|8@1- (1,103) [0|0] "" Vector__XXX

BO_ 646 UI_driverProfileRecall2: 8 Vector__XXX
 SG_ UI_driverProfileLinkedKeySHA1 : 0|32@1+ (1,0) [0|0] "" Vector__XXX
 SG_ UI_driverProfileIndex : 32|4@1+ (1,0) [0|0] "" Vector__XXX
 SG_ UI_driverProfileSelectionType : 36|2@1+ (1,0) [0|0] "" Vector__XXX
 SG_ UI_driverProfilePositionAdjusted : 38|1@1+ (1,0) [0|0] "" Vector__XXX
 SG_ UI_activeKeyRequested : 39|1@1+ (1,0) [0|0] "" Vector__XXX

BO_ 647 PTC_sensorStatus: 8 Vector__XXX
 SG_ PTC_leftTempIGBT : 0|8@1+ (1,-40) [0|0] "" Vector__XXX
 SG_ PTC_tempOCP : 8|8@1+ (1,-40) [0|0] "" Vector__XXX
 SG_ PTC_rightTempIGBT : 16|8@1+ (1,-40) [0|0] "" Vector__XXX
 SG_ PTC_tempPCB : 24|8@1+ (1,-40) [0|0] "" Vector__XXX
 SG_ PTC_voltageHV : 32|10@1+ (0.5,0) [0|0] "" Vector__XXX
 SG_ PTC_leftCurrentHV : 48|8@1+ (0.2,0) [0|0] "" Vector__XXX
 SG_ PTC_rightCurrentHV : 56|8@1+ (0.2,0) [0|0] "" Vector__XXX

BO_ 648 EPBL_internalStatus: 8 Vector__XXX
 SG_ EPBL_unitStatus : 0|5@1+ (1,0) [0|0] "" Vector__XXX
 SG_ EPBL_unitFaultStatus : 5|2@1+ (1,0) [0|0] "" Vector__XXX
 SG_ EPBL_summonState : 8|3@1+ (1,0) [0|0] "" Vector__XXX
 SG_ EPBL_disconnected : 11|1@1+ (1,0) [0|0] "" Vector__XXX
 SG_ EPBL_pistonTouchingRotor : 12|1@1+ (1,0) [0|0] "" Vector__XXX
 SG_ EPBL_csmFaultReason : 13|5@1+ (1,0) [0|0] "" Vector__XXX
 SG_ EPBL_esmOperationTrigger : 18|6@1+ (1,0) [0|0] "" Vector__XXX
 SG_ EPBL_summonFaultReason : 24|5@1+ (1,0) [0|0] "" Vector__XXX
 SG_ EPBL_localServiceModeActive : 29|1@1+ (1,0) [0|0] "" Vector__XXX
 SG_ EPBL_localCdpState : 30|2@1+ (1,0) [0|0] "" Vector__XXX
 SG_ EPBL_chimeRequestLocal : 33|3@1+ (1,0) [0|0] "" Vector__XXX
 SG_ EPBL_telltaleLocal : 39|3@1+ (1,0) [0|0] "" Vector__XXX
 SG_ EPBL_driverIsLeavingLocal : 42|1@1+ (1,0) [0|0] "" Vector__XXX
 SG_ EPBL_driverIsLeavingAnySpeedLocal : 43|1@1+ (1,0) [0|0] "" Vector__XXX
 SG_ EPBL_internalCDPRequest : 44|1@1+ (1,0) [0|0] "" Vector__XXX
 SG_ EPBL_esmSpeedClass : 45|3@1+ (1,0) [0|0] "" Vector__XXX
 SG_ EPBL_learnedEpbConfig : 48|4@1+ (1,0) [0|0] "" Vector__XXX
 SG_ EPBL_internalStatusCounter : 52|4@1+ (1,0) [0|0] "" Vector__XXX
 SG_ EPBL_internalStatusChecksum : 56|8@1+ (1,0) [0|0] "" Vector__XXX

BO_ 649 VCLEFT_logging10Hz: 8 Vector__XXX
 SG_ VCLEFT_logging10HzIndex M : 0|1@1+ (1,0) [0|0] "" Vector__XXX
 SG_ VCLEFT_hvacBlowerRs m0 : 1|8@1+ (0.25,0) [0|0] "" Vector__XXX
 SG_ VCLEFT_hvacBlowerIPhase0 m0 : 9|7@1+ (0.4,0) [0|0] "" Vector__XXX
 SG_ VCLEFT_hvacBlowerIPhase1 m0 : 16|7@1+ (0.4,0) [0|0] "" Vector__XXX
 SG_ VCLEFT_hvacBlowerIPhase2 m0 : 23|7@1+ (0.4,0) [0|0] "" Vector__XXX
 SG_ VCLEFT_hvacBlower_IO_CBC_HEAD m0 : 30|4@1+ (1,0) [0|0] "" Vector__XXX
 SG_ VCLEFT_hvacBlower_IO_CBC_TAIL m0 : 34|4@1+ (1,0) [0|0] "" Vector__XXX
 SG_ VCLEFT_hvacBlower_IO_CBC_TAIL_valid m0 : 38|1@1+ (1,0) [0|0] "" Vector__XXX
 SG_ VCLEFT_hvacBlower_IO_CBC_Status m0 : 39|1@1+ (1,0) [0|0] "" Vector__XXX
 SG_ VCLEFT_hvacBlower_IO_CBC_numUartErr m0 : 40|8@1+ (1,0) [0|0] "" Vector__XXX
 SG_ VCLEFT_hvacBlowerCBCEstState m0 : 48|4@1+ (1,0) [0|0] "" Vector__XXX
 SG_ VCLEFT_hvacBlowerCBCCtrlState m0 : 52|3@1+ (1,0) [0|0] "" Vector__XXX
 SG_ VCLEFT_hvacBlowerITerm m0 : 55|7@1+ (0.05,-1.5) [0|0] "" Vector__XXX
 SG_ VCLEFT_hvacBlowerSpiError m0 : 62|1@1+ (1,0) [0|0] "" Vector__XXX
 SG_ VCLEFT_hvacBlowerRsOnlineActive m0 : 63|1@1+ (1,0) [0|0] "" Vector__XXX

BO_ 658 BMS_socStatus: 8 Vector__XXX
 SG_ BMS_socMin : 0|10@1+ (0.1,0) [0|0] "" Vector__XXX
 SG_ BMS_socUI : 10|10@1+ (0.1,0) [0|0] "" Vector__XXX
 SG_ BMS_socMax : 20|10@1+ (0.1,0) [0|0] "" Vector__XXX
 SG_ BMS_socAvg : 30|10@1+ (0.1,0) [0|0] "" Vector__XXX
 SG_ BMS_enoughEnergyForConvenienceFeatures : 40|1@1+ (1,0) [0|0] "" Vector__XXX
 SG_ BMS_instantChargePowerCapability : 48|16@1+ (0.05,0) [0|0] "" Vector__XXX

BO_ 659 UI_chassisControl: 8 Vector__XXX
 SG_ UI_steeringTuneRequest : 0|2@1+ (1,0) [0|0] "" Vector__XXX
 SG_ UI_tractionControlMode : 2|3@1+ (1,0) [0|0] "" Vector__XXX
 SG_ UI_parkBrakeRequest : 5|2@1+ (1,0) [0|0] "" Vector__XXX
 SG_ UI_narrowGarages : 7|1@1+ (1,0) [0|0] "" Vector__XXX
 SG_ UI_winchModeRequest : 8|2@1+ (1,0) [0|0] "" Vector__XXX
 SG_ UI_zeroSpeedConfirmed : 10|2@1+ (1,0) [0|0] "" Vector__XXX
 SG_ UI_trailerMode : 12|1@1+ (1,0) [0|0] "" Vector__XXX
 SG_ UI_distanceUnits : 13|1@1+ (1,0) [0|0] "" Vector__XXX
 SG_ UI_dasDebugEnable : 14|1@1+ (1,0) [0|0] "" Vector__XXX
 SG_ UI_accOvertakeEnable : 16|2@1+ (1,0) [0|0] "" Vector__XXX
 SG_ UI_aebEnable : 18|2@1+ (1,0) [0|0] "" Vector__XXX
 SG_ UI_aesEnable : 20|2@1+ (1,0) [0|0] "" Vector__XXX
 SG_ UI_ahlbEnable : 22|2@1+ (1,0) [0|0] "" Vector__XXX
 SG_ UI_autoLaneChangeEnable : 24|2@1+ (1,0) [0|0] "" Vector__XXX
 SG_ UI_winchProxUserOverride : 26|1@1+ (1,0) [0|0] "" Vector__XXX
 SG_ UI_rebootAutopilot : 27|1@1+ (1,0) [0|0] "" Vector__XXX
 SG_ UI_autoParkRequest : 28|4@1+ (1,0) [0|0] "" Vector__XXX
 SG_ UI_bsdEnable : 32|2@1+ (1,0) [0|0] "" Vector__XXX
 SG_ UI_fcwEnable : 34|2@1+ (1,0) [0|0] "" Vector__XXX
 SG_ UI_fcwSensitivity : 36|2@1+ (1,0) [0|0] "" Vector__XXX
 SG_ UI_latControlEnable : 38|2@1+ (1,0) [0|0] "" Vector__XXX
 SG_ UI_ldwEnable : 40|2@1+ (1,0) [0|0] "" Vector__XXX
 SG_ UI_pedalSafetyEnable : 42|2@1+ (1,0) [0|0] "" Vector__XXX
 SG_ UI_pedalMap_epas : 44|2@1+ (1,0) [0|0] "" Vector__XXX
 SG_ UI_redLightStopSignEnable : 46|2@1+ (1,0) [0|0] "" Vector__XXX
 SG_ UI_selfParkTune : 48|4@1+ (1,0) [0|0] "" Vector__XXX
 SG_ UI_chassisControlCounter : 52|4@1+ (1,0) [0|0] "" Vector__XXX
 SG_ UI_chassisControlChecksum : 56|8@1+ (1,0) [0|0] "" Vector__XXX

BO_ 660 UI_vehicleControl3: 8 Vector__XXX
 SG_ UI_lightFlashRequest : 0|2@1+ (1,0) [0|0] "" Vector__XXX
 SG_ UI_keylessDrivingEnabled : 2|1@1+ (1,0) [0|0] "" Vector__XXX
 SG_ UI_phoneCallActive : 3|1@1+ (1,0) [0|0] "" Vector__XXX
 SG_ UI_drivingSideVEH : 4|2@1+ (1,0) [0|0] "" Vector__XXX
 SG_ UI_keyPairResponse : 6|2@1+ (1,0) [0|0] "" Vector__XXX
 SG_ UI_lightShowClosuresEnabled : 8|1@1+ (1,0) [0|0] "" Vector__XXX
 SG_ UI_steeringWheelHeatAutoReq : 9|1@1+ (1,0) [0|0] "" Vector__XXX
 SG_ UI_steeringWheelHeatLevelReq : 10|2@1+ (1,0) [0|0] "" Vector__XXX
 SG_ UI_headlightPulseRequest : 12|1@1+ (1,0) [0|0] "" Vector__XXX
 SG_ UI_VCSECFeature2 : 13|1@1+ (1,0) [0|0] "" Vector__XXX
 SG_ UI_VCSECFeature3 : 14|1@1+ (1,0) [0|0] "" Vector__XXX
 SG_ UI_VCSECFeature4 : 15|1@1+ (1,0) [0|0] "" Vector__XXX
 SG_ UI_VCSECFeature5 : 16|1@1+ (1,0) [0|0] "" Vector__XXX
 SG_ UI_shortHornRequest : 17|1@1+ (1,0) [0|0] "" Vector__XXX
 SG_ UI_packTempLoggingRequest : 18|1@1+ (1,0) [0|0] "" Vector__XXX
 SG_ UI_UMC3UpdateInhibit : 22|1@1+ (1,0) [0|0] "" Vector__XXX
 SG_ UI_displayRedShiftActive : 24|1@1+ (1,0) [0|0] "" Vector__XXX
 SG_ UI_blindSpotIndicatorLightRequest : 35|1@1+ (1,0) [0|0] "" Vector__XXX
 SG_ UI_keepOnAccessoryPortsReq : 38|1@1+ (1,0) [0|0] "" Vector__XXX
 SG_ UI_windowPercentageRequest : 42|6@1- (5,0) [0|0] "" Vector__XXX
 SG_ UI_windowRequestedFL : 48|1@1+ (1,0) [0|0] "" Vector__XXX
 SG_ UI_windowRequestedFR : 49|1@1+ (1,0) [0|0] "" Vector__XXX
 SG_ UI_windowRequestedRL : 50|1@1+ (1,0) [0|0] "" Vector__XXX
 SG_ UI_windowRequestedRR : 51|1@1+ (1,0) [0|0] "" Vector__XXX
 SG_ UI_windowRequest : 52|3@1+ (1,0) [0|0] "" Vector__XXX
 SG_ UI_closeTrunkRequest : 55|1@1+ (1,0) [0|0] "" Vector__XXX
 SG_ UI_derivedLoadshedFeature : 59|1@1+ (1,0) [0|0] "" Vector__XXX
 SG_ UI_selfParkStandingBy : 62|1@1+ (1,0) [0|0] "" Vector__XXX

BO_ 661 UI_powerRationalityConfig: 8 Vector__XXX
 SG_ UI_vcleftCfgCutoffDynamicA m8 : 0|16@1+ (50,0) [0|0] "" Vector__XXX
 SG_ UI_vcleftCfgCutoffStaticA m7 : 0|16@1+ (50,0) [0|0] "" Vector__XXX
 SG_ UI_vcleftCfgCutoffThreshold0 m6 : 0|4@1+ (1,0) [0|0] "" Vector__XXX
 SG_ UI_vcleftCfgRationalityDynamicA m2 : 0|16@1+ (50,0) [0|0] "" Vector__XXX
 SG_ UI_vcleftCfgRationalityStaticA m1 : 0|16@1+ (50,0) [0|0] "" Vector__XXX
 SG_ UI_vcleftCfgRationalityThreshold0 m0 : 0|4@1+ (1,0) [0|0] "" Vector__XXX
 SG_ UI_vcrightCfgCutoffDynamicA m11 : 0|16@1+ (50,0) [0|0] "" Vector__XXX
 SG_ UI_vcrightCfgCutoffStaticA m10 : 0|16@1+ (50,0) [0|0] "" Vector__XXX
 SG_ UI_vcrightCfgCutoffThreshold0 m9 : 0|4@1+ (1,0) [0|0] "" Vector__XXX
 SG_ UI_vcrightCfgRationalityDynamicA m5 : 0|16@1+ (50,0) [0|0] "" Vector__XXX
 SG_ UI_vcrightCfgRationalityStaticA m4 : 0|16@1+ (50,0) [0|0] "" Vector__XXX
 SG_ UI_vcrightCfgRationalityThreshold0 m3 : 0|4@1+ (1,0) [0|0] "" Vector__XXX
 SG_ UI_vcleftCfgCutoffTime0 m6 : 4|4@1+ (1,0) [0|0] "" Vector__XXX
 SG_ UI_vcleftCfgRationalityTime0 m0 : 4|4@1+ (1,0) [0|0] "" Vector__XXX
 SG_ UI_vcrightCfgCutoffTime0 m9 : 4|4@1+ (1,0) [0|0] "" Vector__XXX
 SG_ UI_vcrightCfgRationalityTime0 m3 : 4|4@1+ (1,0) [0|0] "" Vector__XXX
 SG_ UI_vcleftCfgCutoffThreshold1 m6 : 8|4@1+ (1,0) [0|0] "" Vector__XXX
 SG_ UI_vcleftCfgRationalityThreshold1 m0 : 8|4@1+ (1,0) [0|0] "" Vector__XXX
 SG_ UI_vcrightCfgCutoffThreshold1 m9 : 8|4@1+ (1,0) [0|0] "" Vector__XXX
 SG_ UI_vcrightCfgRationalityThreshold1 m3 : 8|4@1+ (1,0) [0|0] "" Vector__XXX
 SG_ UI_vcleftCfgCutoffTime1 m6 : 12|4@1+ (1,0) [0|0] "" Vector__XXX
 SG_ UI_vcleftCfgRationalityTime1 m0 : 12|4@1+ (1,0) [0|0] "" Vector__XXX
 SG_ UI_vcrightCfgCutoffTime1 m9 : 12|4@1+ (1,0) [0|0] "" Vector__XXX
 SG_ UI_vcrightCfgRationalityTime1 m3 : 12|4@1+ (1,0) [0|0] "" Vector__XXX
 SG_ UI_vcleftCfgCutoffDynamicB m8 : 16|16@1- (1,0) [0|0] "" Vector__XXX
 SG_ UI_vcleftCfgCutoffStaticB m7 : 16|16@1- (1,0) [0|0] "" Vector__XXX
 SG_ UI_vcleftCfgRationalityDynamicB m2 : 16|16@1- (1,0) [0|0] "" Vector__XXX
 SG_ UI_vcleftCfgRationalityStaticB m1 : 16|16@1- (1,0) [0|0] "" Vector__XXX
 SG_ UI_vcrightCfgCutoffDynamicB m11 : 16|16@1- (1,0) [0|0] "" Vector__XXX
 SG_ UI_vcrightCfgCutoffStaticB m10 : 16|16@1- (1,0) [0|0] "" Vector__XXX
 SG_ UI_vcrightCfgRationalityDynamicB m5 : 16|16@1- (1,0) [0|0] "" Vector__XXX
 SG_ UI_vcrightCfgRationalityStaticB m4 : 16|16@1- (1,0) [0|0] "" Vector__XXX
 SG_ UI_vcleftCfgCutoffDynamicC m8 : 32|16@1- (50,0) [0|0] "" Vector__XXX
 SG_ UI_vcleftCfgCutoffStaticC m7 : 32|16@1- (50,0) [0|0] "" Vector__XXX
 SG_ UI_vcleftCfgRationalityDynamicC m2 : 32|16@1- (50,0) [0|0] "" Vector__XXX
 SG_ UI_vcleftCfgRationalityStaticC m1 : 32|16@1- (50,0) [0|0] "" Vector__XXX
 SG_ UI_vcrightCfgCutoffDynamicC m11 : 32|16@1- (50,0) [0|0] "" Vector__XXX
 SG_ UI_vcrightCfgCutoffStaticC m10 : 32|16@1- (50,0) [0|0] "" Vector__XXX
 SG_ UI_vcrightCfgRationalityDynamicC m5 : 32|16@1- (50,0) [0|0] "" Vector__XXX
 SG_ UI_vcrightCfgRationalityStaticC m4 : 32|16@1- (50,0) [0|0] "" Vector__XXX
 SG_ UI_powerRationalityConfigIndex M : 56|8@1+ (1,0) [0|0] "" Vector__XXX

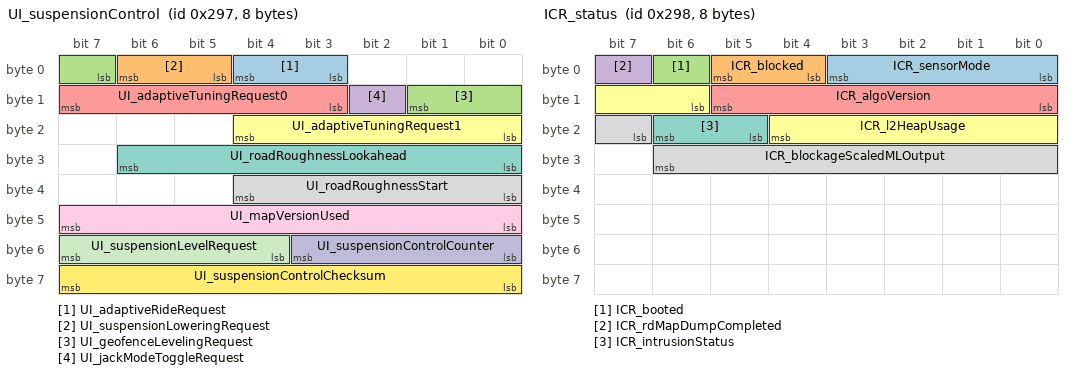
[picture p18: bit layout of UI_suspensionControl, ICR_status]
BO_ 663 UI_suspensionControl: 8 Vector__XXX
 SG_ UI_adaptiveRideRequest : 3|2@1+ (1,0) [0|0] "" Vector__XXX
 SG_ UI_suspensionLoweringRequest : 5|2@1+ (1,0) [0|0] "" Vector__XXX
 SG_ UI_geofenceLevelingRequest : 7|3@1+ (1,0) [0|0] "" Vector__XXX
 SG_ UI_jackModeToggleRequest : 10|1@1+ (1,0) [0|0] "" Vector__XXX
 SG_ UI_adaptiveTuningRequest0 : 11|5@1- (0.1,0) [0|0] "" Vector__XXX
 SG_ UI_adaptiveTuningRequest1 : 16|5@1- (0.1,0) [0|0] "" Vector__XXX
 SG_ UI_roadRoughnessLookahead : 24|7@1+ (0.01,0) [0|0] "" Vector__XXX
 SG_ UI_roadRoughnessStart : 32|5@1+ (10,0) [0|0] "" Vector__XXX
 SG_ UI_mapVersionUsed : 40|8@1+ (1,0) [0|0] "" Vector__XXX
 SG_ UI_suspensionControlCounter : 48|4@1+ (1,0) [0|0] "" Vector__XXX
 SG_ UI_suspensionLevelRequest : 52|4@1+ (1,0) [0|0] "" Vector__XXX
 SG_ UI_suspensionControlChecksum : 56|8@1+ (1,0) [0|0] "" Vector__XXX

BO_ 664 ICR_status: 8 Vector__XXX
 SG_ ICR_sensorMode : 0|4@1+ (1,0) [0|0] "" Vector__XXX
 SG_ ICR_blocked : 4|2@1+ (1,0) [0|0] "" Vector__XXX
 SG_ ICR_booted : 6|1@1+ (1,0) [0|0] "" Vector__XXX
 SG_ ICR_rdMapDumpCompleted : 7|1@1+ (1,0) [0|0] "" Vector__XXX
 SG_ ICR_algoVersion : 8|6@1+ (1,0) [0|0] "" Vector__XXX
 SG_ ICR_l2HeapUsage : 14|7@1+ (1,0) [0|0] "" Vector__XXX
 SG_ ICR_intrusionStatus : 21|2@1+ (1,0) [0|0] "" Vector__XXX
 SG_ ICR_blockageScaledMLOutput : 23|8@1+ (0.004,0) [0|0] "" Vector__XXX

BO_ 667 ICR_nonLocalizedOccupancy: 8 Vector__XXX
 SG_ ICR_lifePresenceMLOutput : 0|8@1+ (0.004,0) [0|0] "" Vector__XXX
 SG_ ICR_userPresenceMLOutput : 8|8@1+ (0.004,0) [0|0] "" Vector__XXX
 SG_ ICR_lifePresenceRaw : 16|2@1+ (1,0) [0|0] "" Vector__XXX
 SG_ ICR_lifePresenceFilt : 18|2@1+ (1,0) [0|0] "" Vector__XXX
 SG_ ICR_userPresenceRaw : 20|2@1+ (1,0) [0|0] "" Vector__XXX
 SG_ ICR_userPresenceFilt : 22|2@1+ (1,0) [0|0] "" Vector__XXX
 SG_ ICR_childPresenceFunctionality : 24|2@1+ (1,0) [0|0] "" Vector__XXX

BO_ 669 CP_dcChargeStatus: 8 Vector__XXX
 SG_ CP_evseOutputDcCurrent : 0|15@1- (0.125,0) [0|0] "" Vector__XXX
 SG_ CP_evseOutputDcVoltage : 16|13@1+ (0.07324218755,0) [0|0] "" Vector__XXX
 SG_ CP_evseOutputDcCurrentStale : 29|1@1+ (1,0) [0|0] "" Vector__XXX
 SG_ CP_evRelocationRecommended : 30|1@1+ (1,0) [0|0] "" Vector__XXX
 SG_ CP_evseDeratingReason : 32|5@1+ (1,0) [0|0] "" Vector__XXX

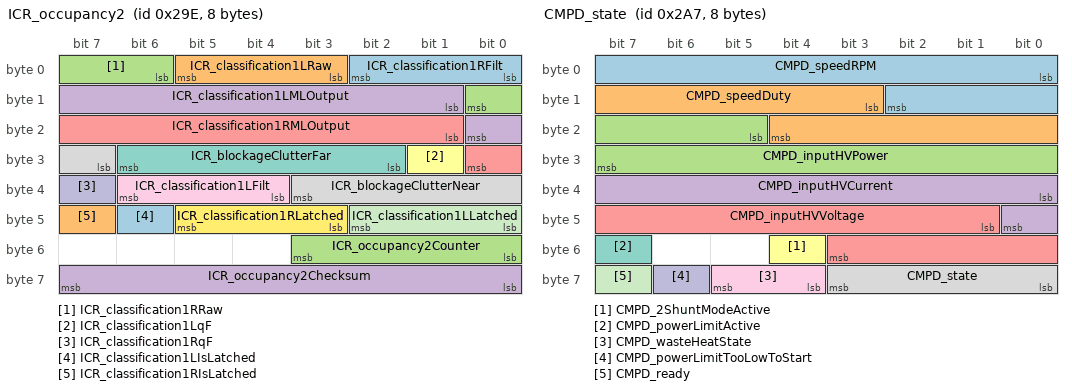
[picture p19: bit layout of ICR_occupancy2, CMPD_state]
BO_ 670 ICR_occupancy2: 8 Vector__XXX
 SG_ ICR_classification1RFilt : 0|3@1+ (1,0) [0|0] "" Vector__XXX
 SG_ ICR_classification1LRaw : 3|3@1+ (1,0) [0|0] "" Vector__XXX
 SG_ ICR_classification1RRaw : 6|3@1+ (1,0) [0|0] "" Vector__XXX
 SG_ ICR_classification1LMLOutput : 9|8@1+ (0.004,0) [0|0] "" Vector__XXX
 SG_ ICR_classification1RMLOutput : 17|8@1+ (0.004,0) [0|0] "" Vector__XXX
 SG_ ICR_classification1LqF : 25|1@1+ (1,0) [0|0] "" Vector__XXX
 SG_ ICR_blockageClutterFar : 26|5@1- (0.5,-1.5) [0|0] "" Vector__XXX
 SG_ ICR_blockageClutterNear : 31|5@1- (0.5,-1.5) [0|0] "" Vector__XXX
 SG_ ICR_classification1LFilt : 36|3@1+ (1,0) [0|0] "" Vector__XXX
 SG_ ICR_classification1RqF : 39|1@1+ (1,0) [0|0] "" Vector__XXX
 SG_ ICR_classification1LLatched : 40|3@1+ (1,0) [0|0] "" Vector__XXX
 SG_ ICR_classification1RLatched : 43|3@1+ (1,0) [0|0] "" Vector__XXX
 SG_ ICR_classification1LIsLatched : 46|1@1+ (1,0) [0|0] "" Vector__XXX
 SG_ ICR_classification1RIsLatched : 47|1@1+ (1,0) [0|0] "" Vector__XXX
 SG_ ICR_occupancy2Counter : 48|4@1+ (1,0) [0|0] "" Vector__XXX
 SG_ ICR_occupancy2Checksum : 56|8@1+ (1,0) [0|0] "" Vector__XXX

BO_ 673 VCFRONT_CMPDRequest: 8 Vector__XXX
 SG_ VCFRONT_CMPDTargetDuty : 0|16@1+ (0.1,0) [0|0] "" Vector__XXX
 SG_ VCFRONT_CMPDPowerLimit : 16|16@1+ (1,0) [0|0] "" Vector__XXX
 SG_ VCFRONT_CMPDReset : 32|1@1+ (1,0) [0|0] "" Vector__XXX
 SG_ VCFRONT_CMPDEnable : 40|1@1+ (1,0) [0|0] "" Vector__XXX
 SG_ VCFRONT_CMPDWasteHeatRequest : 41|2@1+ (1,0) [0|0] "" Vector__XXX
 SG_ VCFRONT_CMPDWriteFlash : 43|1@1+ (1,0) [0|0] "" Vector__XXX
 SG_ VCFRONT_CMPDSoftStartEnable : 44|1@1+ (1,0) [0|0] "" Vector__XXX

BO_ 674 BMS_rippleRequest: 8 Vector__XXX
 SG_ BMS_acRippleCurrentAmplitudeLimit : 0|10@1+ (1,0) [0|0] "" Vector__XXX
 SG_ BMS_acRippleMaxVoltageLimit : 10|10@1+ (1,0) [0|0] "" Vector__XXX
 SG_ BMS_acRippleMinVoltageLimit : 20|10@1+ (1,0) [0|0] "" Vector__XXX
 SG_ BMS_acRippleFrequencyRequest : 30|10@1+ (1,0) [0|0] "" Vector__XXX
 SG_ BMS_acRippleCurrentAmplitudeRequest : 40|10@1+ (1,0) [0|0] "" Vector__XXX
 SG_ BMS_acRippleRequest : 50|3@1+ (1,0) [0|0] "" Vector__XXX

BO_ 675 BMS_rippleDiagnostics: 8 Vector__XXX
 SG_ BMS_acRippleStateInternal : 0|3@1+ (1,0) [0|0] "" Vector__XXX
 SG_ BMS_acRippleMeasuredFrequency : 8|6@1+ (1,80) [0|0] "" Vector__XXX
 SG_ BMS_acRippleMeasuredCurrentAmplitude : 14|9@1+ (1,0) [0|0] "" Vector__XXX
 SG_ BMS_acRippleMeasuredVoltageAmplitude : 23|9@1+ (1,0) [0|0] "" Vector__XXX
 SG_ BMS_acRippleMeasuredRmsCurrent : 32|9@1+ (1,0) [0|0] "" Vector__XXX
 SG_ BMS_acRippleCurrentAmplitudeTarget : 41|9@1+ (1,0) [0|0] "" Vector__XXX

BO_ 676 PCS_thermalStatus: 8 Vector__XXX
 SG_ PCS_chgPhATemp : 0|11@1- (0.1,40) [0|0] "" Vector__XXX
 SG_ PCS_chgPhBTemp : 11|11@1- (0.1,40) [0|0] "" Vector__XXX
 SG_ PCS_chgPhCTemp : 22|11@1- (0.1,40) [0|0] "" Vector__XXX
 SG_ PCS_dcdcTemp : 33|11@1- (0.1,40) [0|0] "" Vector__XXX
 SG_ PCS_ambientTemp : 44|11@1- (0.1,40) [0|0] "" Vector__XXX
 SG_ PCS_dcdcBusbarTemp : 55|9@1+ (0.29354207436399216,0) [0|0] "" Vector__XXX

BO_ 678 CMPD_motorState: 8 Vector__XXX
 SG_ CMPD_motorCurrent : 0|16@1+ (0.1,0) [0|0] "" Vector__XXX
 SG_ CMPD_motorOverloadCountdown : 16|13@1+ (1,0) [0|0] "" Vector__XXX

BO_ 679 CMPD_state: 8 Vector__XXX
 SG_ CMPD_speedRPM : 0|11@1+ (10,0) [0|0] "" Vector__XXX
 SG_ CMPD_speedDuty : 11|10@1+ (0.1,0) [0|0] "" Vector__XXX
 SG_ CMPD_inputHVPower : 21|11@1+ (10,0) [0|0] "" Vector__XXX
 SG_ CMPD_inputHVCurrent : 32|9@1+ (0.1,0) [0|0] "" Vector__XXX
 SG_ CMPD_inputHVVoltage : 41|11@1+ (0.5,0) [0|0] "" Vector__XXX
 SG_ CMPD_2ShuntModeActive : 52|1@1+ (1,0) [0|0] "" Vector__XXX
 SG_ CMPD_powerLimitActive : 55|1@1+ (1,0) [0|0] "" Vector__XXX
 SG_ CMPD_state : 56|4@1+ (1,0) [0|0] "" Vector__XXX
 SG_ CMPD_wasteHeatState : 60|2@1+ (1,0) [0|0] "" Vector__XXX
 SG_ CMPD_powerLimitTooLowToStart : 62|1@1+ (1,0) [0|0] "" Vector__XXX
 SG_ CMPD_ready : 63|1@1+ (1,0) [0|0] "" Vector__XXX

BO_ 680 EPBL_status: 8 Vector__XXX
 SG_ EPBL_systemStatus : 0|4@1+ (1,0) [0|0] "" Vector__XXX
 SG_ EPBL_freeRollModeStatus : 4|2@1+ (1,0) [0|0] "" Vector__XXX
 SG_ EPBL_driverIsLeaving : 6|1@1+ (1,0) [0|0] "" Vector__XXX
 SG_ EPBL_driverIsLeavingAnySpeed : 7|1@1+ (1,0) [0|0] "" Vector__XXX
 SG_ EPBL_systemCdpAvailable : 8|1@1+ (1,0) [0|0] "" Vector__XXX
 SG_ EPBL_chimeRequest : 9|3@1+ (1,0) [0|0] "" Vector__XXX
 SG_ EPBL_telltale : 12|3@1+ (1,0) [0|0] "" Vector__XXX
 SG_ EPBL_contactorCycleNotNeededForWinchEntry : 15|1@1+ (1,0) [0|0] "" Vector__XXX
 SG_ EPBL_redundantBrakingEnabled : 16|1@1+ (1,0) [0|0] "" Vector__XXX
 SG_ EPBL_summonEnabled : 17|1@1+ (1,0) [0|0] "" Vector__XXX
 SG_ EPBL_brakeLight : 18|1@1+ (1,0) [0|0] "" Vector__XXX
 SG_ EPBL_epbConfigMismatch : 19|1@1+ (1,0) [0|0] "" Vector__XXX
 SG_ EPBL_brakeConfirmedPressed : 20|1@1+ (1,0) [0|0] "" Vector__XXX
 SG_ EPBL_requestUserConfirmation : 21|1@1+ (1,0) [0|0] "" Vector__XXX
 SG_ EPBL_uiWinchModeMiscBlocking : 22|1@1+ (1,0) [0|0] "" Vector__XXX
 SG_ EPBL_winchModeActive : 23|1@1+ (1,0) [0|0] "" Vector__XXX
 SG_ EPBL_updateMode : 24|1@1+ (1,0) [0|0] "" Vector__XXX
 SG_ EPBL_winchModePermissive : 25|1@1+ (1,0) [0|0] "" Vector__XXX
 SG_ EPBL_winchModePending : 26|1@1+ (1,0) [0|0] "" Vector__XXX
 SG_ EPBL_cdpRequest : 27|1@1+ (1,0) [0|0] "" Vector__XXX
 SG_ EPBL_uiParkAvailable : 28|2@1+ (1,0) [0|0] "" Vector__XXX
 SG_ EPBL_brakeDiscWipeRequest : 30|2@1+ (1,0) [0|0] "" Vector__XXX
 SG_ EPBL_showUiGearShifter : 32|1@1+ (1,0) [0|0] "" Vector__XXX
 SG_ EPBL_uiWinchModeLvStatus : 33|2@1+ (1,0) [0|0] "" Vector__XXX
 SG_ EPBL_autonomyBehavior : 43|2@1+ (1,0) [0|0] "" Vector__XXX
 SG_ EPBL_showStalkFaultedOnUi : 45|1@1+ (1,0) [0|0] "" Vector__XXX
 SG_ EPBL_espPowerRequest : 46|1@1+ (1,0) [0|0] "" Vector__XXX
 SG_ EPBL_okToPark : 47|1@1+ (1,0) [0|0] "" Vector__XXX
 SG_ EPBL_hornRequest : 48|1@1+ (1,0) [0|0] "" Vector__XXX
 SG_ EPBL_winchModeAvailable : 49|1@1+ (1,0) [0|0] "" Vector__XXX
 SG_ EPBL_bothDisconnected : 50|1@1+ (1,0) [0|0] "" Vector__XXX
 SG_ EPBL_blockDrive : 51|1@1+ (1,0) [0|0] "" Vector__XXX
 SG_ EPBL_statusCounter : 52|4@1+ (1,0) [0|0] "" Vector__XXX
 SG_ EPBL_statusChecksum : 56|8@1+ (1,0) [0|0] "" Vector__XXX

BO_ 682 EPBL_autonomyHealth: 8 Vector__XXX
 SG_ EPBL_ah_speedSupport : 0|3@1+ (1,0) [0|0] "" Vector__XXX
 SG_ EPBL_ah_unitParkingAvailability : 3|3@1+ (1,0) [0|0] "" Vector__XXX
 SG_ EPBL_ah_readiness : 6|2@1+ (1,0) [0|0] "" Vector__XXX
 SG_ EPBL_ah_redundantBrakingAvailable : 8|1@1+ (1,0) [0|0] "" Vector__XXX
 SG_ EPBL_ah_counter : 12|4@1+ (1,0) [0|0] "" Vector__XXX
 SG_ EPBL_ah_checksum : 16|8@1+ (1,0) [0|0] "" Vector__XXX

VAL_ 17 RCM_collisionRear 0 "INACTIVE" 1 "ACTIVE" 3 "SNA" ;
VAL_ 17 RCM_collisionRight 0 "INACTIVE" 1 "ACTIVE" 3 "SNA" ;
VAL_ 17 RCM_collisionLeft 0 "INACTIVE" 1 "ACTIVE" 3 "SNA" ;
VAL_ 17 RCM_collisionFront 0 "INACTIVE" 1 "ACTIVE" 3 "SNA" ;
VAL_ 17 RCM_collisionRollover 0 "INACTIVE" 1 "ACTIVE" 3 "SNA" ;
VAL_ 17 RCM_collisionPedPro 0 "INACTIVE" 1 "ACTIVE" 3 "SNA" ;
VAL_ 17 RCM_collisionSeverity 0 "PRETENSIONER" 1 "FIRST_STAGE" 2 "SECOND_STAGE" 3 "PEDPRO_EVENT" ;
VAL_ 79 UI_gpsAccuracy 127 "SNA" ;
VAL_ 130 UI_navFastchargerType 0 "NONE" 1 "LOW_POWER" 2 "V2" 3 "V3" ;
VAL_ 130 UI_energyAtDestination 4294934528 "SNA" 4294934529 "TRIP_TOO_LONG" ;
VAL_ 258 VCLEFT_frontLatchStatus 0 "SNA" 1 "OPENED" 2 "CLOSED" 3 "CLOSING" 4 "OPENING" 5 "AJAR" 6 "TIMEOUT" 7 "DEFAULT" 8 "FAULT" ;
VAL_ 258 VCLEFT_rearLatchStatus 0 "SNA" 1 "OPENED" 2 "CLOSED" 3 "CLOSING" 4 "OPENING" 5 "AJAR" 6 "TIMEOUT" 7 "DEFAULT" 8 "FAULT" ;
VAL_ 258 VCLEFT_mirrorState 0 "IDLE" 1 "TILT_X" 2 "TILT_Y" 3 "FOLD_UNFOLD" 4 "RECALL" ;
VAL_ 258 VCLEFT_mirrorFoldState 0 "UNKNOWN" 1 "FOLDED" 2 "UNFOLDED" 3 "FOLDING" 4 "UNFOLDING" ;
VAL_ 258 VCLEFT_mirrorRecallState 0 "INIT" 1 "RECALLING_AXIS_1" 2 "RECALLING_AXIS_2" 3 "RECALLING_COMPLETE" 4 "RECALLING_FAILED" 5 "RECALLING_STOPPED" ;
VAL_ 258 VCLEFT_mirrorHeatState 0 "SNA" 1 "ON" 2 "OFF" 3 "OFF_UNAVAILABLE" 4 "FAULT" ;
VAL_ 258 VCLEFT_doorClosureStatusFront 0 "UNKNOWN" 1 "OPENED" 2 "CLOSED" ;
VAL_ 258 VCLEFT_doorClosureStatusRear 0 "UNKNOWN" 1 "OPENED" 2 "CLOSED" ;
VAL_ 259 VCRIGHT_doorClosureStatusFront 0 "UNKNOWN" 1 "OPENED" 2 "CLOSED" ;
VAL_ 259 VCRIGHT_doorClosureStatusRear 0 "UNKNOWN" 1 "OPENED" 2 "CLOSED" ;
VAL_ 259 VCRIGHT_frontLatchStatus 0 "SNA" 1 "OPENED" 2 "CLOSED" 3 "CLOSING" 4 "OPENING" 5 "AJAR" 6 "TIMEOUT" 7 "DEFAULT" 8 "FAULT" ;
VAL_ 259 VCRIGHT_rearLatchStatus 0 "SNA" 1 "OPENED" 2 "CLOSED" 3 "CLOSING" 4 "OPENING" 5 "AJAR" 6 "TIMEOUT" 7 "DEFAULT" 8 "FAULT" ;
VAL_ 259 VCRIGHT_mirrorState 0 "IDLE" 1 "TILT_X" 2 "TILT_Y" 3 "FOLD_UNFOLD" 4 "RECALL" ;
VAL_ 259 VCRIGHT_mirrorFoldState 0 "UNKNOWN" 1 "FOLDED" 2 "UNFOLDED" 3 "FOLDING" 4 "UNFOLDING" ;
VAL_ 259 VCRIGHT_trunkLatchStatus 0 "SNA" 1 "OPENED" 2 "CLOSED" 3 "CLOSING" 4 "OPENING" 5 "AJAR" 6 "TIMEOUT" 7 "DEFAULT" 8 "FAULT" ;
VAL_ 259 VCRIGHT_mirrorRecallState 0 "INIT" 1 "RECALLING_AXIS_1" 2 "RECALLING_AXIS_2" 3 "RECALLING_COMPLETE" 4 "RECALLING_FAILED" 5 "RECALLING_STOPPED" ;
VAL_ 264 DIR_torqueCommand 4294963200 "SNA" ;
VAL_ 264 DIR_axleSpeedQF 0 "INVALID" 1 "VALID" 2 "FAULTED" ;
VAL_ 264 DIR_torqueActual 4294963200 "SNA" ;
VAL_ 264 DIR_axleSpeed 4294934528 "SNA" ;
VAL_ 264 DIR_axleTorqueQF 0 "INVALID" 1 "VALID" 2 "FAULTED" ;
VAL_ 264 DIR_axlePowerCalcQF 0 "INVALID" 1 "VALID" ;
VAL_ 264 DIR_gear 0 "INVALID" 1 "P" 2 "R" 3 "N" 4 "D" 7 "SNA" ;
VAL_ 280 DI_immobilizerState 0 "INIT_SNA" 1 "REQUEST" 2 "AUTHENTICATING" 3 "DISARMED" 4 "IDLE" 5 "RESET" 6 "FAULT" ;
VAL_ 280 DI_systemState 0 "UNAVAILABLE" 1 "IDLE" 2 "STANDBY" 3 "FAULT" 4 "ABORT" 5 "ENABLE" ;
VAL_ 280 DI_brakePedalState 0 "OFF" 1 "ON" 2 "INVALID" ;
VAL_ 280 DI_gear 0 "INVALID" 1 "P" 2 "R" 3 "N" 4 "D" 7 "SNA" ;
VAL_ 280 DI_driveBlocked 0 "NONE" 1 "FRUNK" 2 "PROX" 3 "FALCON" ;
VAL_ 280 DI_hvilSystemStatus 0 "DISABLED" 1 "OPEN" 2 "CLOSED" 3 "SNA" ;
VAL_ 280 DI_accelPedalPos 255 "SNA" ;
VAL_ 280 DI_tractionControlMode 0 "NORMAL" 1 "SLIP_START" 2 "DEV_MODE_1" 3 "DEV_MODE_2" 4 "ROLLS_MODE" 5 "DYNO_MODE" 6 "OFFROAD_ASSIST" ;
VAL_ 280 DI_epbRequest 0 "NO_REQUEST" 1 "PARK" 2 "UNPARK" ;
VAL_ 280 DI_keepDrivePowerStateRequest 0 "NO_REQUEST" 1 "KEEP_ALIVE" ;
VAL_ 280 DI_trackModeState 0 "UNAVAILABLE" 1 "AVAILABLE" 2 "ON" ;
VAL_ 280 DI_vehicleAcceleration 4294965248 "SNA" ;
VAL_ 289 RCM_nearDeployRear 0 "INACTIVE" 1 "ACTIVE" 3 "SNA" ;
VAL_ 289 RCM_nearDeployRight 0 "INACTIVE" 1 "ACTIVE" 3 "SNA" ;
VAL_ 289 RCM_nearDeployLeft 0 "INACTIVE" 1 "ACTIVE" 3 "SNA" ;
VAL_ 289 RCM_nearDeployFront 0 "INACTIVE" 1 "ACTIVE" 3 "SNA" ;
VAL_ 289 RCM_nearDeployRollover 0 "INACTIVE" 1 "ACTIVE" 3 "SNA" ;
VAL_ 289 RCM_crashAlgoWakeup 0 "INACTIVE" 1 "ACTIVE" 3 "SNA" ;
VAL_ 290 VCLEFT_frontDoorState 0 "UNKNOWN" 1 "CLOSED" 2 "WAIT_FOR_SHORT_DROP" 3 "RELEASING_LATCH" 4 "OPEN" 5 "AJAR" 6 "INIT" ;
VAL_ 290 VCLEFT_rearDoorState 0 "UNKNOWN" 1 "CLOSED" 2 "WAIT_FOR_SHORT_DROP" 3 "RELEASING_LATCH" 4 "OPEN" 5 "AJAR" 6 "INIT" ;
VAL_ 291 VCRIGHT_frontDoorState 0 "UNKNOWN" 1 "CLOSED" 2 "WAIT_FOR_SHORT_DROP" 3 "RELEASING_LATCH" 4 "OPEN" 5 "AJAR" 6 "INIT" ;
VAL_ 291 VCRIGHT_rearDoorState 0 "UNKNOWN" 1 "CLOSED" 2 "WAIT_FOR_SHORT_DROP" 3 "RELEASING_LATCH" 4 "OPEN" 5 "AJAR" 6 "INIT" ;
VAL_ 294 DIR_targetFluxMode 0 "OPTIMUM" 1 "FS" 2 "FW" ;
VAL_ 294 DIR_keepAliveRequest 0 "NO_REQUEST" 1 "KEEP_ALIVE" ;
VAL_ 296 DI_vehicleSpeedLimitType 0 "NONE" 1 "USER" 2 "POWERTRAIN" ;
VAL_ 296 DI_vehicleSpeedLimit 511 "SNA" ;
VAL_ 296 DI_vehicleSpeedLimitReason 0 "NONE" 1 "DRIVE_UNIT_LIMIT" 2 "FACTORY_LOW_BRAKE_FLUID" 3 "FACTORY_MODE" 4 "SERVICE_MODE" 5 "MAX_CAR_CONFIG" 6 "SPINDOWN_LEARNING" 7 "TRAILER_MODE" 8 "TAS" 9 "LOAD_SHED" 10 "FRUNK_OPEN" 11 "USER" ;
VAL_ 296 DI_proximity 0 "SNA" 1 "DISCONNECTED" 2 "UNLATCHED" 3 "LATCHED" ;
VAL_ 297 SCCM_steeringAngleSensorStatus 0 "OK" 1 "INIT" 2 "ERROR" 3 "ERROR_INIT" ;
VAL_ 297 SCCM_steeringAngle 16383 "SNA" ;
VAL_ 297 SCCM_steeringAngleValidity 0 "INVALID" 1 "VALID" 2 "INIT" 3 "SNA" ;
VAL_ 306 BMS_packCurrent 4294934528 "SNA" ;
VAL_ 306 BMS_currentUnfiltered 4294934528 "SNA" ;
VAL_ 322 VCLEFT_liftgateStatusIndex 0 "0" 1 "1" 2 "INVALID" ;
VAL_ 322 VCLEFT_liftgateState 0 "INIT" 1 "OFF" 2 "BACKOFF" 3 "OPENING" 4 "CLOSING" 5 "CLOSED" 6 "LATCH_OPENING" 7 "LATCH_CLOSING" 8 "NOT_INSTALLED" 9 "UNKNOWN" 10 "LATCH_EXIT" 11 "END_OF_TRAVEL" 12 "LATCH_ENTRY" 13 "PARTY_DANCE" ;
VAL_ 322 VCLEFT_liftgateStoppingCondition 0 "NONE" 1 "PINCH" 2 "OBSTACLE_STALL" 3 "LOW_12V" 4 "STATE_TIMEOUT" 5 "VEHICLE_AT_SPEED" 6 "OBSTACLE_CURRENT" 7 "OBSTACLE_TRAJ_POS" 8 "OBSTACLE_TRAJ_VEL" 9 "UNCALIBRATED" 10 "LATCH_FAULT" 11 "OBSTACLE_CURRENT_SPIKE" 12 "COUNT" ;
VAL_ 322 VCLEFT_liftgateMvmntNotAllowedCondition 0 "NONE" 1 "LOW_12V" 2 "VEHICLE_AT_SPEED" 3 "UNCALIBRATED" 4 "EXTERIOR_PRESS_AT_MAX_OPEN" 5 "LOCKED" ;
VAL_ 322 VCLEFT_liftgateUIChimeRequest 0 "NONE" 1 "ONE_SHORT" 2 "TWO_SHORT" 3 "THREE_SHORT" 4 "ONE_LONG" ;
VAL_ 322 VCLEFT_liftgatePhysicalChimeRequest 0 "NONE" 1 "ONE_SHORT" 2 "TWO_SHORT" 3 "THREE_SHORT" 4 "ONE_LONG" ;
VAL_ 322 VCLEFT_liftgateRequestSource 0 "NONE" 1 "MCU_SWITCH" 2 "EXTERIOR" 3 "SHUTFACE" 4 "KEY_TRUNK_BUTTON" 5 "VCSEC_COMMAND" 6 "PARTY" 7 "UDS" ;
VAL_ 322 VCLEFT_liftgateLatchRequest 0 "NONE" 1 "CINCH" 2 "RELEASE_V2" 3 "FORCE_RELEASE" 4 "RESET" ;
VAL_ 358 TAS_tempIndex 0 "Mux0" 1 "Mux1" 2 "Mux2" ;
VAL_ 358 TAS_temp_FL_C 31 "SNA" ;
VAL_ 358 TAS_temp_RL_C 31 "SNA" ;
VAL_ 358 TAS_temp_FL_R 31 "SNA" ;
VAL_ 358 TAS_temp_RL_R 31 "SNA" ;
VAL_ 358 TAS_temp_FR_C 31 "SNA" ;
VAL_ 358 TAS_temp_RR_C 31 "SNA" ;
VAL_ 358 TAS_temp_FR_R 31 "SNA" ;
VAL_ 358 TAS_temp_RR_R 31 "SNA" ;
VAL_ 390 DIF_torqueCommand 4294963200 "SNA" ;
VAL_ 390 DIF_axleSpeedQF 0 "NOT_QUALIFIED" 1 "QUALIFIED" ;
VAL_ 390 DIF_torqueActual 4294963200 "SNA" ;
VAL_ 390 DIF_axleSpeed 4294934528 "SNA" ;
VAL_ 390 DIF_axleTorqueQF 0 "INVALID" 1 "VALID" 2 "FAULTED" ;
VAL_ 390 DIF_axlePowerCalcQF 0 "INVALID" 1 "VALID" ;
VAL_ 390 DIF_gear 0 "INVALID" 1 "P" 2 "R" 3 "N" 4 "D" 7 "SNA" ;
VAL_ 405 DIF_currentLimit 8191 "SNA" ;
VAL_ 409 TAS_adaptiveActivityFL_C 31 "SNA" ;
VAL_ 409 TAS_adaptiveActivityFL_R 31 "SNA" ;
VAL_ 409 TAS_adaptiveActivityFR_C 31 "SNA" ;
VAL_ 409 TAS_adaptiveActivityFR_R 31 "SNA" ;
VAL_ 409 TAS_adaptiveActivityRL_C 31 "SNA" ;
VAL_ 409 TAS_adaptiveActivityRL_R 31 "SNA" ;
VAL_ 409 TAS_adaptiveActivityRR_C 31 "SNA" ;
VAL_ 409 TAS_adaptiveActivityRR_R 31 "SNA" ;
VAL_ 409 TAS_uiHeightFL 63 "SNA" ;
VAL_ 409 TAS_uiHeightFR 63 "SNA" ;
VAL_ 409 TAS_uiHeightRL 63 "SNA" ;
VAL_ 409 TAS_uiHeightRR 63 "SNA" ;
VAL_ 410 TAS_bodyAccelFL 255 "SNA" ;
VAL_ 410 TAS_bodyAccelFR 255 "SNA" ;
VAL_ 410 TAS_bodyAccelRL 255 "SNA" ;
VAL_ 410 TAS_bodyAccelRR 255 "SNA" ;
VAL_ 421 DIF_targetFluxMode 0 "OPTIMUM" 1 "FS" 2 "FW" ;
VAL_ 421 DIF_keepAliveRequest 0 "NO_REQUEST" 1 "KEEP_ALIVE" ;
VAL_ 455 TASDBG_current_FL_C 31 "SNA" ;
VAL_ 455 TASDBG_current_FL_R 31 "SNA" ;
VAL_ 455 TASDBG_current_FR_C 31 "SNA" ;
VAL_ 455 TASDBG_current_FR_R 31 "SNA" ;
VAL_ 455 TASDBG_current_RL_C 31 "SNA" ;
VAL_ 455 TASDBG_current_RL_R 31 "SNA" ;
VAL_ 455 TASDBG_current_RR_C 31 "SNA" ;
VAL_ 455 TASDBG_current_RR_R 31 "SNA" ;
VAL_ 469 PMF_soptState 0 "INIT" 1 "PSTG_BRING_UP" 2 "ASC_TEST" 3 "CURRENT_TEST" 4 "TEST_PASSED" 5 "TEST_SKIPPED" 6 "TEST_FAILED" 7 "SNA" ;
VAL_ 469 PMF_torqueCommand 4294963200 "SNA" ;
VAL_ 469 PMF_hvilStatus 0 "DISABLED" 1 "OPEN" 2 "CLOSED" 3 "SNA" ;
VAL_ 469 PMF_axleSpeedQF 0 "NOT_QUALIFIED" 1 "QUALIFIED" ;
VAL_ 469 PMF_hvilSupplyState 0 "NOT_AVAILABLE" 1 "INACTIVE" 2 "ACTIVE" ;
VAL_ 470 DIR_currentLimit 8191 "SNA" ;
VAL_ 472 PMR_soptState 0 "INIT" 1 "PSTG_BRING_UP" 2 "ASC_TEST" 3 "CURRENT_TEST" 4 "TEST_PASSED" 5 "TEST_SKIPPED" 6 "TEST_FAILED" 7 "SNA" ;
VAL_ 472 PMR_torqueCommand 4294963200 "SNA" ;
VAL_ 472 PMR_hvilStatus 0 "DISABLED" 1 "OPEN" 2 "CLOSED" 3 "SNA" ;
VAL_ 472 PMR_axleSpeedQF 0 "NOT_QUALIFIED" 1 "QUALIFIED" ;
VAL_ 472 PMR_hvilSupplyState 0 "NOT_AVAILABLE" 1 "INACTIVE" 2 "ACTIVE" ;
VAL_ 485 PM_cruiseState 0 "UNAVAILABLE" 1 "STANDBY" 2 "ENABLED" 3 "STANDSTILL" 4 "OVERRIDE" 5 "FAULT" 6 "PRE_FAULT" 7 "PRE_CANCEL" ;
VAL_ 485 PM_autoparkState 0 "UNAVAILABLE" 1 "STANDBY" 2 "STARTED" 3 "ACTIVE" 4 "COMPLETE" 5 "PAUSED" 6 "ABORTED" 7 "RESUMED" 8 "UNPARK_COMPLETE" 9 "SELFPARK_STARTED" 15 "SNA" ;
VAL_ 485 PM_hvilSystemStatus 0 "DISABLED" 1 "OPEN" 2 "CLOSED" 3 "SNA" ;
VAL_ 504 VCLEFT_DBG_System_Status 0 "IDLE" 1 "RX" ;
VAL_ 504 VCLEFT_DBG_Air_Cond_Status 0 "IDLE" 1 "RX" ;
VAL_ 504 VCLEFT_DBG_Heater_Status 0 "IDLE" 1 "RX" ;
VAL_ 504 VCLEFT_DBG_Window_Status 0 "IDLE" 1 "RX" ;
VAL_ 504 VCLEFT_DBG_Suspensions_Status 0 "IDLE" 1 "RX" ;
VAL_ 504 VCLEFT_DBG_SelfTest_Status 0 "IDLE" 1 "RX" ;
VAL_ 504 VCLEFT_DBG_Veh_Settings_Status 0 "IDLE" 1 "RX" ;
VAL_ 504 VCLEFT_DBG_USS_Alarm_Status 0 "IDLE" 1 "RX" ;
VAL_ 504 VCLEFT_DBG_LM_Alarm_Status 0 "IDLE" 1 "RX" ;
VAL_ 504 VCLEFT_DBG_Siren_ST_Status 0 "IDLE" 1 "RX" ;
VAL_ 504 VCLEFT_DBG_Eeprom_ST_Status 0 "IDLE" 1 "RX" ;
VAL_ 504 VCLEFT_DBG_USS_SelfTest_Status 0 "IDLE" 1 "RX" ;
VAL_ 504 VCLEFT_DBG_LM_SelfTest_Status 0 "IDLE" 1 "RX" ;
VAL_ 505 VCSEC_chargePortRequest 0 "NONE" 1 "OPEN" 2 "CLOSE" 3 "SNA" ;
VAL_ 505 VCSEC_frontLeftClosureRequest 0 "NONE" 1 "MOVE" 2 "STOP" 3 "OPEN" 4 "QUICK_OPEN" 5 "OPEN_REDUCED" 6 "CLOSE" ;
VAL_ 505 VCSEC_frontRightClosureRequest 0 "NONE" 1 "MOVE" 2 "STOP" 3 "OPEN" 4 "QUICK_OPEN" 5 "OPEN_REDUCED" 6 "CLOSE" ;
VAL_ 505 VCSEC_rearLeftClosureRequest 0 "NONE" 1 "MOVE" 2 "STOP" 3 "OPEN" 4 "QUICK_OPEN" 5 "OPEN_REDUCED" 6 "CLOSE" ;
VAL_ 505 VCSEC_rearRightClosureRequest 0 "NONE" 1 "MOVE" 2 "STOP" 3 "OPEN" 4 "QUICK_OPEN" 5 "OPEN_REDUCED" 6 "CLOSE" ;
VAL_ 505 VCSEC_rearTrunkClosureRequest 0 "NONE" 1 "MOVE" 2 "STOP" 3 "OPEN" 4 "QUICK_OPEN" 5 "OPEN_REDUCED" 6 "CLOSE" ;
VAL_ 505 VCSEC_frontLeftRequestReason 0 "REASON_NONE" 1 "REASON_RKE" 2 "REASON_CLOSE_ALL" 3 "REASON_AUTO_PRESENT" 4 "KEYFOB_UNLOCK_OPEN" 5 "UI_STOP_ALL" ;
VAL_ 505 VCSEC_frontRightRequestReason 0 "REASON_NONE" 1 "REASON_RKE" 2 "REASON_CLOSE_ALL" 3 "REASON_AUTO_PRESENT" 4 "KEYFOB_UNLOCK_OPEN" 5 "UI_STOP_ALL" ;
VAL_ 505 VCSEC_rearLeftRequestReason 0 "REASON_NONE" 1 "REASON_RKE" 2 "REASON_CLOSE_ALL" 3 "REASON_AUTO_PRESENT" 4 "KEYFOB_UNLOCK_OPEN" 5 "UI_STOP_ALL" ;
VAL_ 505 VCSEC_rearRightRequestReason 0 "REASON_NONE" 1 "REASON_RKE" 2 "REASON_CLOSE_ALL" 3 "REASON_AUTO_PRESENT" 4 "KEYFOB_UNLOCK_OPEN" 5 "UI_STOP_ALL" ;
VAL_ 505 VCSEC_rearTrunkRequestReason 0 "REASON_NONE" 1 "REASON_RKE" 2 "REASON_CLOSE_ALL" 3 "REASON_AUTO_PRESENT" 4 "KEYFOB_UNLOCK_OPEN" 5 "UI_STOP_ALL" ;
VAL_ 505 VCSEC_closeAllStatus 0 "NOT_AVAILABLE" 1 "AVAILABLE" 2 "CANCELABLE" ;
VAL_ 505 VCSEC_snapshotRequested 0 "NONE" 1 "HANDLE_PULL_WITHOUT_AUTH" 2 "AUTHED_WITHOUT_HANDLE_PULL" 3 "AUTO_PRESENT_DOOR_CLOSE_TIMEOUT" 4 "AUTO_PRESENT_DOOR_CLOSE_WITHOUT_PEDESTRIAN_DETECTED" 5 "INTRUSION_DETECTED" 6 "TRIGGER_6" 7 "TRIGGER_7" 8 "TRIGGER_8" 9 "TRIGGER_9" 10 "TRIGGER_10" 11 "TRIGGER_11" 12 "TRIGGER_12" 13 "TRIGGER_13" 14 "TRIGGER_14" 15 "TRIGGER_15" ;
VAL_ 505 VCSEC_chargeportRequestReason 0 "NONE" 1 "RKE" 2 "UHF" ;
VAL_ 507 VCLEFT_TLCStatusIndex 0 "0" 1 "1" 2 "INVALID" ;
VAL_ 507 VCLEFT_TLCTemperature 4294967168 "SNA" ;
VAL_ 507 VCLEFT_TLCLeftTurnVoltage 255 "SNA" ;
VAL_ 507 VCLEFT_TLCRightTurnVoltage 255 "SNA" ;
VAL_ 507 VCLEFT_TLCState_LeftTurn 0 "OFF_WITHOUT_LOAD" 1 "OFF_WITH_LOAD" 2 "ON_WITHOUT_LOAD" 3 "ON_WITH_LOAD" 4 "FAULT" 5 "SNA" ;
VAL_ 507 VCLEFT_TLCState_RightTurn 0 "OFF_WITHOUT_LOAD" 1 "OFF_WITH_LOAD" 2 "ON_WITHOUT_LOAD" 3 "ON_WITH_LOAD" 4 "FAULT" 5 "SNA" ;
VAL_ 507 VCLEFT_TLCState_Tail 0 "OFF_WITHOUT_LOAD" 1 "OFF_WITH_LOAD" 2 "ON_WITHOUT_LOAD" 3 "ON_WITH_LOAD" 4 "FAULT" 5 "SNA" ;
VAL_ 507 VCLEFT_TLCState_Stop 0 "OFF_WITHOUT_LOAD" 1 "OFF_WITH_LOAD" 2 "ON_WITHOUT_LOAD" 3 "ON_WITH_LOAD" 4 "FAULT" 5 "SNA" ;
VAL_ 507 VCLEFT_TLCState_Fog 0 "OFF_WITHOUT_LOAD" 1 "OFF_WITH_LOAD" 2 "ON_WITHOUT_LOAD" 3 "ON_WITH_LOAD" 4 "FAULT" 5 "SNA" ;
VAL_ 507 VCLEFT_TLCState_Reverse 0 "OFF_WITHOUT_LOAD" 1 "OFF_WITH_LOAD" 2 "ON_WITHOUT_LOAD" 3 "ON_WITH_LOAD" 4 "FAULT" 5 "SNA" ;
VAL_ 508 APP_suspensionLevelRequest 0 "NONE" 1 "VERY_LOW_LEVEL" 2 "LOW_LEVEL" 3 "STANDARD_LEVEL" 4 "HIGH_LEVEL_TEMPORARY" 5 "VERY_HIGH_LEVEL_TEMPORARY" 6 "HIGH_LEVEL_PERSIST" 7 "VERY_HIGH_LEVEL_PERSIST" ;
VAL_ 513 VCFRONT_loggingAndVitals10HzIndex 0 "TARGETS_AND_ACTUALS_0" 1 "TARGETS_SENSORS_AND_ACTUALS_1" 2 "STATES_AND_SENSORS" 3 "EXV_FLOW" 4 "HP_AND_EXV_STATE" 5 "EXV_FLOW_TARGET" 6 "END" ;
VAL_ 513 VCFRONT_pumpBatteryRPMActual 1023 "SNA" ;
VAL_ 513 VCFRONT_compressorState 0 "STANDBY" 1 "READY" 2 "RUNNING" 3 "FAULT" ;
VAL_ 513 VCFRONT_pumpPowertrainRPMActual 1023 "SNA" ;
VAL_ 513 VCFRONT_exvState 0 "UNINIT" 1 "INIT_OPEN" 2 "INIT_CLOSE" 3 "READY" 4 "FAULTED" 5 "WAIT" 6 "OVERDRIVING_SHUT" 7 "READY_SHUT" 8 "CALIB_CLOSE" 9 "CALIB_CLOSE_OVERDRIVE" ;
VAL_ 513 VCFRONT_solenoidEvapState 0 "UNDEFINED" 1 "OPENED" 2 "CLOSED" 3 "FAULTED" ;
VAL_ 513 VCFRONT_radiatorFanRPMActual 1023 "SNA" ;
VAL_ 513 VCFRONT_coolantValveMode 0 "SERIES" 1 "PARALLEL" 2 "BLEND" 3 "AMBIENT_SOURCE" ;
VAL_ 513 VCFRONT_compFaultSeverity 0 "NONE" 1 "LOW" 2 "MEDIUM" 3 "HIGH" ;
VAL_ 513 VCFRONT_hpHighSideHX 0 "NONE" 1 "LCC" 2 "CC" 3 "BOTH" ;
VAL_ 513 VCFRONT_hpLowSideHX 0 "NONE" 1 "CHILLER" 2 "EVAP" 3 "BOTH" ;
VAL_ 513 VCFRONT_hpDominantLoad 0 "NONE" 1 "EVAP" 2 "CHILLER" 3 "LOW_BOTH" 4 "LCC" 5 "CC" 6 "HIGH_BOTH" ;
VAL_ 513 VCFRONT_hpBlendType 0 "NONE" 1 "PARTIAL" 2 "FULL" ;
VAL_ 513 VCFRONT_hpCabinLoadType 0 "NONE" 1 "CC" 2 "REHEAT" 3 "EVAP" ;
VAL_ 513 VCFRONT_pressureRefrigLiquid 511 "SNA" ;
VAL_ 513 VCFRONT_hpBatteryLoadType 0 "NONE" 1 "BATT_HEAT" 2 "BATT_COOL" ;
VAL_ 513 VCFRONT_chillerExvState 0 "UNINIT" 1 "INIT_OPEN" 2 "INIT_CLOSE" 3 "READY" 4 "FAULTED" 5 "WAIT" 6 "OVERDRIVING_SHUT" 7 "READY_SHUT" 8 "CALIB_CLOSE" 9 "CALIB_CLOSE_OVERDRIVE" ;
VAL_ 513 VCFRONT_hpReqCoolantMode 0 "ANY" 1 "SERIES_NO_BYPASS" 2 "SERIES_BYPASS" 3 "PARALLEL" 4 "AMBIENT_SOURCE" ;
VAL_ 513 VCFRONT_lccExvState 0 "UNINIT" 1 "INIT_OPEN" 2 "INIT_CLOSE" 3 "READY" 4 "FAULTED" 5 "WAIT" 6 "OVERDRIVING_SHUT" 7 "READY_SHUT" 8 "CALIB_CLOSE" 9 "CALIB_CLOSE_OVERDRIVE" ;
VAL_ 513 VCFRONT_cclExvState 0 "UNINIT" 1 "INIT_OPEN" 2 "INIT_CLOSE" 3 "READY" 4 "FAULTED" 5 "WAIT" 6 "OVERDRIVING_SHUT" 7 "READY_SHUT" 8 "CALIB_CLOSE" 9 "CALIB_CLOSE_OVERDRIVE" ;
VAL_ 513 VCFRONT_evapExvState 0 "UNINIT" 1 "INIT_OPEN" 2 "INIT_CLOSE" 3 "READY" 4 "FAULTED" 5 "WAIT" 6 "OVERDRIVING_SHUT" 7 "READY_SHUT" 8 "CALIB_CLOSE" 9 "CALIB_CLOSE_OVERDRIVE" ;
VAL_ 513 VCFRONT_ccrExvState 0 "UNINIT" 1 "INIT_OPEN" 2 "INIT_CLOSE" 3 "READY" 4 "FAULTED" 5 "WAIT" 6 "OVERDRIVING_SHUT" 7 "READY_SHUT" 8 "CALIB_CLOSE" 9 "CALIB_CLOSE_OVERDRIVE" ;
VAL_ 513 VCFRONT_recircExvState 0 "UNINIT" 1 "INIT_OPEN" 2 "INIT_CLOSE" 3 "READY" 4 "FAULTED" 5 "WAIT" 6 "OVERDRIVING_SHUT" 7 "READY_SHUT" 8 "CALIB_CLOSE" 9 "CALIB_CLOSE_OVERDRIVE" ;
VAL_ 516 PCS_chgMainState 0 "INIT" 1 "IDLE" 2 "STARTUP" 3 "WAIT_FOR_LINE_VOLTAGE" 4 "QUALIFY_LINE_CONFIG" 5 "SYSTEM_CONFIG" 6 "ENABLE" 7 "SHUTDOWN" 8 "FAULTED" 9 "CLEAR_FAULTS" ;
VAL_ 516 PCS_gridConfig 0 "SNA" 1 "SINGLE_PHASE" 2 "THREE_PHASE" 3 "THREE_PHASE_DELTA" ;
VAL_ 516 PCS_chgMaxAcPowerAvailable 255 "SNA" ;
VAL_ 516 PCS_hwVariantType 0 "48A_SINGLE_PHASE_VARIANT" 1 "32A_SINGLE_PHASE_VARIANT" 2 "THREE_PHASES_VARIANT" 3 "HW_VARIANT_TYPE_SNA" ;
VAL_ 522 HVP_packContNegativeState 0 "SNA" 1 "OPEN" 2 "PRECHARGE" 3 "BLOCKED" 4 "PULLED_IN" 5 "OPENING" 6 "ECONOMIZED" 7 "WELDED" ;
VAL_ 522 HVP_packContPositiveState 0 "SNA" 1 "OPEN" 2 "PRECHARGE" 3 "BLOCKED" 4 "PULLED_IN" 5 "OPENING" 6 "ECONOMIZED" 7 "WELDED" ;
VAL_ 522 HVP_packContactorSetState 0 "SNA" 1 "OPEN" 2 "CLOSING" 3 "BLOCKED" 4 "OPENING" 5 "CLOSED" 6 "PARTIAL_WELD" 7 "WELDED" 8 "POSITIVE_CLOSED" 9 "NEGATIVE_CLOSED" ;
VAL_ 522 HVP_fcContNegativeState 0 "SNA" 1 "OPEN" 2 "PRECHARGE" 3 "BLOCKED" 4 "PULLED_IN" 5 "OPENING" 6 "ECONOMIZED" 7 "WELDED" ;
VAL_ 522 HVP_fcContPositiveState 0 "SNA" 1 "OPEN" 2 "PRECHARGE" 3 "BLOCKED" 4 "PULLED_IN" 5 "OPENING" 6 "ECONOMIZED" 7 "WELDED" ;
VAL_ 522 HVP_fcContactorSetState 0 "SNA" 1 "OPEN" 2 "CLOSING" 3 "BLOCKED" 4 "OPENING" 5 "CLOSED" 6 "PARTIAL_WELD" 7 "WELDED" 8 "POSITIVE_CLOSED" 9 "NEGATIVE_CLOSED" ;
VAL_ 522 HVP_fcCtrsRequestStatus 0 "NOT_ACTIVE" 1 "ACTIVE" 2 "COMPLETED" ;
VAL_ 522 HVP_packCtrsRequestStatus 0 "NOT_ACTIVE" 1 "ACTIVE" 2 "COMPLETED" ;
VAL_ 522 HVP_hvilDiag 0 "UNKNOWN" 1 "OK" 2 "CURRENT_SOURCE_OR_GROUND_LEAK_FAULT" 3 "INTERNAL_OPEN_FAULT" 4 "VEHICLE_OPEN_FAULT" 5 "PENTHOUSE_LID_OPEN_FAULT" 6 "UNKNOWN_LOCATION_OPEN_FAULT" 7 "VEHICLE_NODE_FAULT" 8 "NO_12V_SUPPLY" 9 "VEHICLE_OR_PENTHOUSE_LID_OPEN_FAULT" 10 "DI_STATUS_MISSING_FAULT" 11 "PM_STATUS_MISSING_FAULT" 12 "DI_OPEN_FAULT" 13 "PM_OPEN_FAULT" ;
VAL_ 522 HVP_fcLinkAllowedToEnergize 0 "NONE" 1 "AC" 2 "DC" ;
VAL_ 523 TAS_axleIndex 0 "axleFront" 1 "axleRear" ;
VAL_ 523 TAS_rawHeightFL 1023 "SNA" ;
VAL_ 523 TAS_rawHeightRL 1023 "SNA" ;
VAL_ 523 TAS_staticHeightEstimateFL 1023 "SNA" ;
VAL_ 523 TAS_staticHeightEstimateRL 1023 "SNA" ;
VAL_ 523 TAS_componentPressureFL 255 "SNA" ;
VAL_ 523 TAS_componentPressureRL 255 "SNA" ;
VAL_ 523 TAS_rawHeightFR 1023 "SNA" ;
VAL_ 523 TAS_rawHeightRR 1023 "SNA" ;
VAL_ 523 TAS_staticHeightEstimateFR 1023 "SNA" ;
VAL_ 523 TAS_staticHeightEstimateRR 1023 "SNA" ;
VAL_ 523 TAS_componentPressureFR 255 "SNA" ;
VAL_ 523 TAS_componentPressureRR 255 "SNA" ;
VAL_ 524 VCRIGHT_tempEvaporator 2047 "SNA" ;
VAL_ 524 VCRIGHT_tempEvaporatorTarget 255 "SNA" ;
VAL_ 524 VCRIGHT_tempAmbientRaw 0 "SNA" ;
VAL_ 524 VCRIGHT_hvacPerfTestState 0 "STOPPED" 1 "WAITING" 2 "BLOWING" ;
VAL_ 525 TAS_levelingState 0 "IDLE" 1 "READ_P_RESERVOIR" 2 "MANUAL_SPRING_CONTROL" 3 "EXHAUST_GALLERY" 4 "COMPRESSOR_RAMPUP" 5 "COMPRESSOR_PREFILL_GALLERY" 6 "FILL_RESERVOIR_FROM_COMPRESSOR" 7 "FILL_SPRING_FROM_COMPRESSOR" 8 "FILL_SPRING_FROM_BOOST" 9 "FILL_SPRING_FROM_RESERVOIR" 10 "FILL_SPRING_RESERVOIR_FROM_COMPRESSOR" 11 "LOWER_SPRING" 12 "LOWER_SPRING_WITH_COMPRESSOR" 13 "EXHAUST_RESERVOIR" ;
VAL_ 525 TAS_levelingItem 0 "NONE" 1 "FL" 2 "FR" 3 "RL" 4 "RR" 5 "FRONT_AXLE" 6 "REAR_AXLE" 7 "ALL" ;
VAL_ 525 TAS_pressureGallery 255 "SNA" ;
VAL_ 525 TAS_pressureReservoir 255 "SNA" ;
VAL_ 525 TAS_runMode 0 "INIT" 1 "SYSTEM_CHECK" 2 "SERVICE" 3 "ASSEMBLY" 4 "DAN" 5 "NORMAL" 6 "LOW_POWER" 7 "DYNO" ;
VAL_ 525 TAS_filterMode 0 "NONE" 1 "INIT" 2 "CALIBRATE" 3 "TEST" 4 "READY" 5 "LOADING" 6 "DRIVE" 7 "STOPPING" ;
VAL_ 525 TAS_limpHomeMode 0 "0" 1 "10" 2 "20" 3 "30" 4 "40" ;
VAL_ 525 TAS_targetLevel 0 "VERY_HIGH" 1 "HIGH" 2 "STANDARD" 3 "LOW" 4 "VERY_LOW" ;
VAL_ 525 TAS_currentLevel 0 "VERY_HIGH" 1 "HIGH" 2 "STANDARD" 3 "LOW" 4 "VERY_LOW" ;
VAL_ 529 RCM_armStatus 0 "RCM_UNARMED" 1 "RCM_ARMED" 2 "ARMED_WITH_NOFIRE_CAL" 3 "SNA" ;
VAL_ 529 RCM_warningIndicatorState 0 "RCM_WARNING_INDICATOR_OFF" 1 "RCM_WARNING_INDICATOR_ON" 3 "SNA" ;
VAL_ 529 RCM_passAirbagIndicatorRequest 0 "RCM_PASSENGER_AIRBAG_INDICATOR_ON" 1 "RCM_PASSENGER_AIRBAG_INDICATOR_OFF" 3 "SNA" ;
VAL_ 529 RCM_airbagCutoffStatus 0 "RCM_PASSENGER_AIRBAG_ENABLED" 1 "RCM_PASSENGER_AIRBAG_DISABLED" 3 "SNA" ;
VAL_ 529 RCM_alrSwitchStatus 0 "RCM_ALR_NOT_ENGAGED" 1 "RCM_ALR_ENGAGED" 2 "RCM_ALR_FAULTED" 3 "SNA" ;
VAL_ 529 RCM_vinLearnFlag 0 "RCM_VIN_NOT_STORED" 1 "RCM_VIN_STORED" 2 "RCM_VIN_STORED_MISMATCH" 3 "SNA" ;
VAL_ 529 RCM_seatTrackPositionDrvr 0 "RCM_SEAT_POSITION_NEAR" 1 "RCM_SEAT_POSITION_FAR" 2 "RCM_SEAT_POSITION_FAULTED" 3 "SNA" ;
VAL_ 529 RCM_seatTrackPositionPass 0 "RCM_SEAT_POSITION_NEAR" 1 "RCM_SEAT_POSITION_FAR" 2 "RCM_SEAT_POSITION_FAULTED" 3 "SNA" ;
VAL_ 529 RCM_edr1State 0 "EMPTY" 1 "STORED" 2 "LOCKED" 3 "UNAVAILABLE" ;
VAL_ 529 RCM_edr2State 0 "EMPTY" 1 "STORED" 2 "LOCKED" 3 "UNAVAILABLE" ;
VAL_ 529 RCM_keepPowerReason 0 "NO_KEEP_POWER_REQUEST" 1 "IN_IDLE_MODE" 2 "CRASH_ALGO_ACTIVE" 3 "EDR_STORING_TO_EEPROM" 4 "EDR_UPLOADING" 5 "CANNOT_POWER_DOWN" 6 "INITIALIZATION_PHASE" 7 "INVALID_POWER_OFF_REQUEST" 8 "KEEP_POWER_REASON_SNA" ;
VAL_ 529 RCM_imuOffsetLearnState 0 "OFFSET_LEARNING_OFF" 1 "SLOW_LEARNING_DISTANCE" 2 "FAST_LEARNING_TIME" 3 "OFFSETS_UNABLE_TO_LEARN" ;
VAL_ 529 RCM_edr3State 0 "EMPTY" 1 "STORED" 2 "LOCKED" 3 "UNAVAILABLE" ;
VAL_ 529 RCM_driverOrientationInitStatus 0 "RCM_DRIVER_ORIENTATION_INIT_NOT_COMPLETE" 1 "RCM_DRIVER_ORIENTATION_MATCHED_LHD" 2 "RCM_DRIVER_ORIENTATION_MATCHED_RHD" 3 "RCM_DRIVER_ORIENTATION_MISMATCH_DEFAULT_LHD" 4 "RCM_DRIVER_ORIENTATION_MISMATCH_DEFAULT_RHD" 7 "SNA" ;
VAL_ 529 RCM_pedProEDR1State 0 "EMPTY" 1 "STORED" 2 "LOCKED" 3 "UNAVAILABLE" ;
VAL_ 529 RCM_pedProEDR2State 0 "EMPTY" 1 "STORED" 2 "LOCKED" 3 "UNAVAILABLE" ;
VAL_ 530 BMS_contactorState 0 "SNA" 1 "OPEN" 2 "OPENING" 3 "CLOSING" 4 "CLOSED" 5 "WELDED" 6 "BLOCKED" ;
VAL_ 530 BMS_state 0 "STANDBY" 1 "DRIVE" 2 "SUPPORT" 3 "CHARGE" 4 "FEIM" 5 "CLEAR_FAULT" 6 "FAULT" 7 "WELD" 8 "TEST" 9 "SNA" 10 "DIAG" ;
VAL_ 530 BMS_diLimpRequest 0 "NONE" 1 "WELDED" ;
VAL_ 530 BMS_chgPowerAvailable 2047 "SNA" ;
VAL_ 530 BMS_smStateRequest 0 "STANDBY" 1 "DRIVE" 2 "SUPPORT" 3 "CHARGE" 4 "FEIM" 5 "CLEAR_FAULT" 6 "FAULT" 7 "WELD" 8 "TEST" 9 "SNA" 10 "DIAG" ;
VAL_ 530 BMS_hvState 0 "DOWN" 1 "COMING_UP" 2 "GOING_DOWN" 3 "UP_FOR_DRIVE" 4 "UP_FOR_CHARGE" 5 "UP_FOR_DC_CHARGE" 6 "UP" ;
VAL_ 531 UI_cruiseSpeedCommand 0 "IDLE" 1 "INC_SHORT" 2 "INC_LONG" 3 "DEC_SHORT" 4 "DEC_LONG" 5 "SNAP" 6 "SNAP_SPEEDO" ;
VAL_ 532 FC_statusCode 0 "NOTREADY_SNA" 1 "READY" 2 "UPDATE_IN_PROGRESS" 3 "DEPRECATED_3" 4 "DEPRECATED_4" 5 "INT_ISOACTIVE" 6 "EXT_ISOACTIVE" 7 "POST_OUT_OF_SERVICE" 13 "NOTCOMPATIBLE" 14 "MALFUNCTION" 15 "NODATA" ;
VAL_ 532 FC_type 0 "SUPERCHARGER" 1 "CHADEMO" 2 "GB" 3 "CC_EVSE" 4 "COMBO" 5 "MC_EVSE" 6 "OTHER" 7 "SNA" ;
VAL_ 532 FC_postID 0 "MASTER" 1 "SLAVE" 2 "ID_2" 3 "ID_SNA" ;
VAL_ 533 FC_externalIsolationResistance 255 "SNA" ;
VAL_ 535 FC_status3DataSelect 0 "Mux0" 1 "Mux1" ;
VAL_ 535 FC_class 0 "SNA" 1 "SUPERCHARGER" 2 "URBANCHARGER" ;
VAL_ 535 FC_brand 0 "SNA" 1 "TESLA" ;
VAL_ 535 FC_coolingType 0 "SNA" 1 "LIQUID" 2 "CONVECTION" ;
VAL_ 535 FC_uiStopType 0 "SNA" 1 "TOGGLE" 2 "MOMENTARY" ;
VAL_ 535 FC_generation 0 "GENERATION_SNA" ;
VAL_ 537 VCSEC_TPMSDataIndex 0 "0" 1 "1" 2 "2" 3 "3" 4 "RCP" 5 "4" 6 "5" 7 "6" 8 "7" 9 "8" 10 "9" ;
VAL_ 537 VCSEC_TPMSRecommendedColdPressureFront 255 "SNA" ;
VAL_ 537 VCSEC_TPMSPressure0 511 "SNA" ;
VAL_ 537 VCSEC_TPMSPressure1 511 "SNA" ;
VAL_ 537 VCSEC_TPMSPressure2 511 "SNA" ;
VAL_ 537 VCSEC_TPMSPressure3 511 "SNA" ;
VAL_ 537 VCSEC_TPMSRecommendedColdPressureRear 255 "SNA" ;
VAL_ 537 VCSEC_TPMSTemperature0 255 "SNA" ;
VAL_ 537 VCSEC_TPMSTemperature1 255 "SNA" ;
VAL_ 537 VCSEC_TPMSTemperature2 255 "SNA" ;
VAL_ 537 VCSEC_TPMSTemperature3 255 "SNA" ;
VAL_ 537 VCSEC_TPMSBatVoltage0 255 "SNA" ;
VAL_ 537 VCSEC_TPMSBatVoltage1 255 "SNA" ;
VAL_ 537 VCSEC_TPMSBatVoltage2 255 "SNA" ;
VAL_ 537 VCSEC_TPMSBatVoltage3 255 "SNA" ;
VAL_ 537 VCSEC_TPMSLocation0 0 "FL" 1 "FR" 2 "RL" 3 "RR" 4 "UNKNOWN" ;
VAL_ 537 VCSEC_TPMSLocation1 0 "FL" 1 "FR" 2 "RL" 3 "RR" 4 "UNKNOWN" ;
VAL_ 537 VCSEC_TPMSLocation2 0 "FL" 1 "FR" 2 "RL" 3 "RR" 4 "UNKNOWN" ;
VAL_ 537 VCSEC_TPMSLocation3 0 "FL" 1 "FR" 2 "RL" 3 "RR" 4 "UNKNOWN" ;
VAL_ 538 TAS_adaptiveRideModeOverride 0 "COMFORT" 1 "AUTO" 2 "SPORT" 3 "SNA" ;
VAL_ 538 TAS_launchModeState 0 "BLOCKED" 1 "IDLE" 2 "LOWER_SUSPENSION" 3 "READY" 4 "RAISE_SUSPENSION" ;
VAL_ 541 CP_proximity 0 "SNA" 1 "DISCONNECTED" 2 "UNLATCHED" 3 "LATCHED" ;
VAL_ 541 CP_pilot 0 "NONE" 1 "FAULTED" 2 "LINE_CHARGE" 3 "FAST_CHARGE" 4 "IDLE" 5 "INVALID" 6 "UNUSED_6" 7 "SNA" ;
VAL_ 541 CP_cableType 0 "IEC" 1 "SAE" 2 "GB_AC" 3 "GB_DC" 4 "SNA" ;
VAL_ 541 CP_iecPilotState 0 "B1" 1 "B2" 2 "B3" 3 "C1" 4 "C2" 5 "C3" 6 "E" 7 "F" 8 "NUM" 9 "SNA" ;
VAL_ 541 CP_teslaSwcanState 0 "INACTIVE" 1 "ACCEPT" 2 "RECEIVE" 3 "ESTABLISHED" 4 "FAULT" 5 "GO_TO_SLEEP" 6 "OFFBOARD_UPDATE_IN_PROGRESS" ;
VAL_ 541 CP_evseChargeType_UI 0 "NO_CHARGER_PRESENT" 1 "DC_CHARGER_PRESENT" 2 "AC_CHARGER_PRESENT" ;
VAL_ 541 CP_gbState 0 "INACTIVE" 1 "WAIT_FOR_COMMS" 2 "COMMS_RECEIVED" 3 "HANDSHAKING_EXT_ISO" 4 "RECOGNITION" 5 "CHARGE_PARAM_CONFIG" 6 "VEH_PACK_PRECHARGE" 7 "READY_TO_CHARGE" 8 "CHARGING" 9 "STOP_CHARGE_REQUESTED" 10 "CHARGE_DISABLING" 11 "END_OF_CHARGE" 12 "ERROR_HANDLING" 13 "RETRY_CHARGE" 14 "FAULTED" 15 "TESTER_PRESENT" ;
VAL_ 541 CP_gbdcStopChargeReason 0 "STOP_REASON_NONE" 1 "VEH_REQUESTED" 2 "EVSE_REQUESTED" 3 "COMMS_TIMEOUT" 4 "EVSE_FAULT" 5 "EVSE_CRITICAL_FAULT" 6 "LIVE_DISCONNECT" 7 "SUPERCHARGER_COMMS_TIMEOUT" ;
VAL_ 541 CP_gbdcFailureReason 0 "FAILURE_NONE" 1 "ATTEMPTS_EXPIRED" 2 "SHUTDOWN_FAILURE" 3 "CRITICAL_FAILURE" ;
VAL_ 541 CP_acChargeState 0 "INACTIVE" 1 "CONNECTED_CHARGE_BLOCKED" 2 "STANDBY" 3 "ENABLED" 4 "ONBOARD_CHARGER_SHUTDOWN" 5 "VEH_SHUTDOWN" 6 "FAULT" ;
VAL_ 541 CP_teslaDcState 0 "INACTIVE" 1 "CONNECTED_CHARGE_BLOCKED" 2 "STANDBY" 3 "EXT_TESTS_ENABLED" 4 "EXT_TEST_ACTIVE" 5 "EXT_PRECHARGE_ACTIVE" 6 "ENABLED" 7 "EVSE_SHUTDOWN" 8 "VEH_SHUTDOWN" 9 "EMERGENCY_SHUTDOWN" 10 "FAULT" ;
VAL_ 545 VCFRONT_LVPowerStateIndex 0 "Mux0" 1 "Mux1" ;
VAL_ 545 VCFRONT_vehiclePowerState 0 "OFF" 1 "CONDITIONING" 2 "ACCESSORY" 3 "DRIVE" ;
VAL_ 545 VCFRONT_parkLVState 0 "OFF" 1 "ON" 2 "GOING_DOWN" 3 "FAULT" ;
VAL_ 545 VCFRONT_epasLVState 0 "OFF" 1 "ON" 2 "GOING_DOWN" 3 "FAULT" ;
VAL_ 545 VCFRONT_espLVState 0 "OFF" 1 "ON" 2 "GOING_DOWN" 3 "FAULT" ;
VAL_ 545 VCFRONT_hcmlLVState 0 "OFF" 1 "ON" 2 "GOING_DOWN" 3 "FAULT" ;
VAL_ 545 VCFRONT_espValveLVState 0 "OFF" 1 "ON" 2 "GOING_DOWN" 3 "FAULT" ;
VAL_ 545 VCFRONT_uiHiCurrentLVState 0 "OFF" 1 "ON" 2 "GOING_DOWN" 3 "FAULT" ;
VAL_ 548 PCS_dcdcPrechargeStatus 0 "IDLE" 1 "ACTIVE" 2 "FAULTED" ;
VAL_ 548 PCS_dcdcLvSupportStatus 0 "IDLE" 1 "ACTIVE" 2 "FAULTED" ;
VAL_ 548 PCS_dcdcHvBusDischargeStatus 0 "IDLE" 1 "ACTIVE" 2 "FAULTED" ;
VAL_ 548 PCS_dcdcSubState 0 "PWR_UP_INIT" 1 "STANDBY" 2 "LV_SUPPORT_ACTIVE" 3 "FAST_DIS_HVBUS" 4 "SLOW_DIS_HVBUS" 5 "PCHG_FAST_DIS_HVBUS" 6 "PCHG_SLOW_DIS_HVBUS" 7 "PCHG_DWELL_CHARGE" 8 "PCHG_DWELL_WAIT" 9 "PCHG_DI_RECOVERY_WAIT" 10 "PCHG_ACTIVE" 11 "PCHG_FLT_FAST_DIS_HVBUS" 12 "SHUTDOWN" 13 "LV_SUPPORT_FAULTED" 14 "DIS_HVBUS_FAULTED" 15 "PCHG_FAULTED" 16 "CLEAR_FAULTS" 17 "FAULTED" 18 "NUM" ;
VAL_ 548 PCS_ecuLogUploadRequest 0 "NONE" 1 "1" 2 "2" 3 "3" ;
VAL_ 548 PCS_dcdcInitialPrechargeSubState 0 "PWR_UP_INIT" 1 "STANDBY" 2 "LV_SUPPORT_ACTIVE" 3 "FAST_DIS_HVBUS" 4 "SLOW_DIS_HVBUS" 5 "PCHG_FAST_DIS_HVBUS" 6 "PCHG_SLOW_DIS_HVBUS" 7 "PCHG_DWELL_CHARGE" 8 "PCHG_DWELL_WAIT" 9 "PCHG_DI_RECOVERY_WAIT" 10 "PCHG_ACTIVE" 11 "PCHG_FLT_FAST_DIS_HVBUS" 12 "SHUTDOWN" 13 "LV_SUPPORT_FAULTED" 14 "DIS_HVBUS_FAULTED" 15 "PCHG_FAULTED" 16 "CLEAR_FAULTS" 17 "FAULTED" 18 "NUM" ;
VAL_ 549 VCRIGHT_ptcLVState 0 "OFF" 1 "ON" 2 "GOING_DOWN" 3 "FAULT" ;
VAL_ 549 VCRIGHT_ocsLVState 0 "OFF" 1 "ON" 2 "GOING_DOWN" 3 "FAULT" ;
VAL_ 549 VCRIGHT_premAudioLVState 0 "OFF" 1 "ON" 2 "GOING_DOWN" 3 "FAULT" ;
VAL_ 549 VCRIGHT_tunerLVState 0 "OFF" 1 "ON" 2 "GOING_DOWN" 3 "FAULT" ;
VAL_ 549 VCRIGHT_hvcLVState 0 "OFF" 1 "ON" 2 "GOING_DOWN" 3 "FAULT" ;
VAL_ 549 VCRIGHT_rcmLVState 0 "OFF" 1 "ON" 2 "GOING_DOWN" 3 "FAULT" ;
VAL_ 549 VCRIGHT_lumbarLVState 0 "OFF" 1 "ON" 2 "GOING_DOWN" 3 "FAULT" ;
VAL_ 549 VCRIGHT_eFuseLockoutStatus 0 "IDLE" 1 "PENDING" 2 "ACTIVE" ;
VAL_ 549 VCRIGHT_vehiclePowerStateDBG 0 "INIT" 1 "LOW_POWER_AWAKE" 2 "CONDITIONING" 3 "ACCESSORY" 4 "ACCESSORY_PLUS" 5 "DRIVE" 6 "OTA" 7 "WAIT_FOR_HIGH_POWER" 8 "TURN_ON_LV" 9 "SYSTEM_CHECKS" 10 "LV_ON" 11 "JUMP_START" 12 "LV_SHUTDOWN" 13 "GO_QUIET" 14 "SLEEP_SHUTDOWN" 15 "LOW_POWER_STANDBY" 16 "RESET" ;
VAL_ 549 VCRIGHT_parkLVState 0 "OFF" 1 "ON" 2 "GOING_DOWN" 3 "FAULT" ;
VAL_ 549 VCRIGHT_icrLVState 0 "OFF" 1 "ON" 2 "GOING_DOWN" 3 "FAULT" ;
VAL_ 551 CMP_state 0 "STANDBY" 1 "DRIVE" 2 "SUPPORT" 3 "CHARGE" 4 "FEIM" 5 "CLEAR_FAULT" 6 "FAULT" 7 "WELD" 8 "TEST" 9 "SNA" 10 "DIAG" ;
VAL_ 552 EPBR_unitStatus 0 "UNKNOWN" 1 "OPEN" 2 "DYNAMIC" 3 "PARK" 4 "START" 5 "SERVICE" 6 "WINCHMODE" 7 "WINCHMODE_RELEASING" 8 "PARKING" 9 "DYNAMIC_APPLYING" 10 "RELEASING" 11 "SERVICE_RELEASING" 12 "PARK_PENDING" 13 "WINCHMODE_PENDING" 14 "SUMMON" 15 "SUMMON_RELEASING" 16 "SUMMON_PARKING" 17 "EXTERNAL_DYNAMIC" 18 "RELEASING_FOR_EXTERNAL_PARK" 19 "EXTERNAL_PARKING" 20 "DYNAMIC_PARKING" 21 "FREE_ROLL_MODE" 22 "COUNT" ;
VAL_ 552 EPBR_unitFaultStatus 0 "NOMINAL" 1 "RETRY" 2 "FAULT" 3 "FAULT_IDLE" ;
VAL_ 552 EPBR_summonState 0 "INIT" 1 "IDLE" 2 "ARMED" 3 "ACTIVE" 4 "COMPLETE" 5 "FAULT" 6 "UNAVAILABLE" ;
VAL_ 552 EPBR_csmFaultReason 0 "NONE" 1 "EPBM_DISABLED" 2 "EPBM_FAULTED" 3 "STATE_MISMATCH" 4 "TIMEOUT_CALIBRATE" 5 "APPLY_BLOCKED" 6 "RELEASE_BLOCKED" 7 "TIMEOUT_APPLY_COMPLETE" 8 "TIMEOUT_APPLY_INRUSH" 9 "TIMEOUT_EPB_WAIT_FOR_CLAMP" 10 "TIMEOUT_EPBM_WAIT_FOR_CLAMP" 11 "TIMEOUT_RELEASE_INRUSH" 12 "TIMEOUT_RELEASE_WAIT_FOR_ENDSTOP" 13 "TIMEOUT_RELEASE_NO_LOAD" 14 "TIMEOUT_RELEASE_COMPLETE" 15 "TIMEOUT_EPBM_CUTOFF" 16 "TIMEOUT_NO_RAMP" 17 "TIMEOUT_EPBM_START" 18 "MOTOR_IDLE_FAULT" 19 "MOTOR_ACTIVE_FAULT" 20 "MOTOR_NOT_READY" 21 "EPBM_MIA" 22 "NVM_MISMATCH" 23 "REMOTE_MIA" ;
VAL_ 552 EPBR_esmOperationTrigger 0 "PBUTTON_PRESSED_STOPPED" 1 "PBUTTON_PRESSED_OKTOPARK" 2 "PBUTTON_PRESSED_FAST" 3 "PBUTTON_PRESSED_UNKNOWN" 4 "PBUTTON_RELEASED" 5 "ACTIVE_PARK_REQUEST" 6 "DI_UNPARK" 7 "TOUCHSCREEN" 8 "WINCHMODE_EXIT" 9 "WINCHMODE_ENTER" 10 "WINCHMODE_UNAVAILABLE" 11 "SERVICE" 12 "DIAG_CLOSE" 13 "DIAG_OPEN" 14 "DIAG_EXIT" 15 "USER_CONFIRMED" 16 "USER_CANCEL" 17 "SPEED_STOPPED" 18 "SPEED_OKAYTOPARK" 19 "SPEED_FAST" 20 "TIMEOUT" 21 "SAVESTATE_ON_BOOT" 22 "REAPPLY" 23 "SUMMON_COMPLETE" 24 "FAULT" 25 "SUMMON_FAULT" 26 "DISQUALIFIED" 27 "EPBM_DISQUALIFIED" 28 "ACCELERATION" 29 "SYSTEM_APPLY" 30 "DRIVER_IS_LEAVING" 31 "AUTOPARK_END" 32 "UI_DOOR_OPEN_REQUEST" 33 "TOUCHSCREEN_INVALID" ;
VAL_ 552 EPBR_summonFaultReason 0 "NONE" 1 "DI_MIA" 2 "DAS_MIA" 3 "ESP_MIA" 4 "EPBM_MIA" 5 "DI_FAULT" 6 "DI_APC_FAULT" 7 "DAS_FAULT" 8 "ESP_FAULT" 9 "VEH_CAN_FAULT" 10 "EAC_NOT_ALLOWED" 11 "EPBM_REQUEST" 12 "SPEED" 13 "EXTERNAL" 14 "PARK_MIA" 15 "PM_MIA" 16 "PM_REQUEST" 17 "OOC" 18 "MISMATCH" 19 "EPB_FAULT" 20 "DI_STATE_INVALID" 21 "PASSIVE_REQUEST" 22 "EPBREMOTE_MIA" 23 "REMOTE_SUMMON_FAULTED" 24 "LOCAL_UNIT_FAULTED" 25 "REMOTE_UNIT_FAULTED" 26 "START_IN_UNAVAILABLE" 27 "INVALID_REMOTE_STATE" 28 "REMOTE_DID_NOT_START" ;
VAL_ 552 EPBR_telltaleLocal 0 "LAMP_OFF" 1 "LAMP_RED_ON" 2 "LAMP_AMBER_ON" 3 "LAMP_RED_FLASH" 7 "SNA" ;
VAL_ 552 EPBR_internalCDPRequest 0 "NOT_REQUESTED" 1 "REQUESTED" ;
VAL_ 552 EPBR_esmSpeedClass 0 "STOPPED" 1 "SYSTEM_APPLY_OK" 2 "USER_APPLY_OK" 3 "FAST" 4 "UNKNOWN" ;
VAL_ 552 EPBR_learnedEpbConfig 0 "UNKNOWN" 1 "MODEL3_BASE" 2 "MODEL3_PERFORMANCE" 3 "MODELS_BASE" 4 "MODELY_BASE" 5 "MODELY_PERFORMANCE" 6 "MODELX_BASE" 7 "MODEL3_PERFORMANCE_V2" 8 "MODELY_PERFORMANCE_V2" 9 "MODELS_CERAMIC" ;
VAL_ 553 SCCM_rightStalkStatus 0 "IDLE" 1 "UP_1" 2 "UP_2" 3 "DOWN_1" 4 "DOWN_2" 5 "INIT" 6 "SNA" ;
VAL_ 553 SCCM_parkButtonStatus 0 "NOT_PRESSED" 1 "PRESSED" 2 "INIT" 3 "SNA" ;
VAL_ 554 HVP_pcsControlRequest 0 "SHUTDOWN" 1 "SUPPORT" 2 "PRECHARGE" 3 "DISCHARGE" ;
VAL_ 554 HVP_dcLinkVoltageFiltered 4294966746 "SNA" ;
VAL_ 564 DCDC_type 0 "US_TESLA" 1 "EURO_IEC" 2 "GB" 3 "IEC_CCS" ;
VAL_ 568 UI_mapSpeedLimitDependency 0 "NONE" 1 "SCHOOL" 2 "RAIN" 3 "SNOW" 4 "TIME" 5 "SEASON" 6 "LANE" 7 "SNA" ;
VAL_ 568 UI_roadClass 0 "UNKNOWN_INVALID_SNA" 1 "CLASS_1_MAJOR" 2 "CLASS_2" 3 "CLASS_3" 4 "CLASS_4" 5 "CLASS_5" 6 "CLASS_6_MINOR" ;
VAL_ 568 UI_inSuperchargerGeofence 0 "FALSE" 1 "TRUE" ;
VAL_ 568 UI_mapSpeedUnits 0 "MPH" 1 "KPH" ;
VAL_ 568 UI_mapSpeedLimit 0 "UNKNOWN" 1 "LESS_OR_EQ_5" 2 "LESS_OR_EQ_7" 3 "LESS_OR_EQ_10" 4 "LESS_OR_EQ_15" 5 "LESS_OR_EQ_20" 6 "LESS_OR_EQ_25" 7 "LESS_OR_EQ_30" 8 "LESS_OR_EQ_35" 9 "LESS_OR_EQ_40" 10 "LESS_OR_EQ_45" 11 "LESS_OR_EQ_50" 12 "LESS_OR_EQ_55" 13 "LESS_OR_EQ_60" 14 "LESS_OR_EQ_65" 15 "LESS_OR_EQ_70" 16 "LESS_OR_EQ_75" 17 "LESS_OR_EQ_80" 18 "LESS_OR_EQ_85" 19 "LESS_OR_EQ_90" 20 "LESS_OR_EQ_95" 21 "LESS_OR_EQ_100" 22 "LESS_OR_EQ_105" 23 "LESS_OR_EQ_110" 24 "LESS_OR_EQ_115" 25 "LESS_OR_EQ_120" 26 "LESS_OR_EQ_130" 27 "LESS_OR_EQ_140" 28 "LESS_OR_EQ_150" 29 "LESS_OR_EQ_160" 30 "UNLIMITED" 31 "SNA" ;
VAL_ 568 UI_mapSpeedLimitType 1 "REGULAR" 2 "ADVISORY" 3 "DEPENDENT" 4 "BUMPS" 7 "UNKNOWN_SNA" ;
VAL_ 568 UI_countryCode 0 "UNKNOWN" 1023 "SNA" ;
VAL_ 568 UI_nextBranchDist 31 "SNA" ;
VAL_ 570 VCSEC_TPMSStatusIndex 0 "MAC_ADDRESS_SENSOR_0" 1 "MAC_ADDRESS_SENSOR_1" 2 "MAC_ADDRESS_SENSOR_2" 3 "MAC_ADDRESS_SENSOR_3" 4 "CONN_METRICS_SENSOR_0" 5 "CONN_METRICS_SENSOR_1" 6 "CONN_METRICS_SENSOR_2" 7 "CONN_METRICS_SENSOR_3" 8 "CRC_SENSOR_0" 9 "CRC_SENSOR_1" 10 "CRC_SENSOR_2" 11 "CRC_SENSOR_3" 12 "CPU_TIME_SENSOR_0" 13 "CPU_TIME_SENSOR_1" 14 "CPU_TIME_SENSOR_2" 15 "CPU_TIME_SENSOR_3" 16 "SLEEP_STATS_SENSOR_0" 17 "SLEEP_STATS_SENSOR_1" 18 "SLEEP_STATS_SENSOR_2" 19 "SLEEP_STATS_SENSOR_3" 20 "MAC_ADDRESS_SENSOR_4" 21 "MAC_ADDRESS_SENSOR_5" 22 "MAC_ADDRESS_SENSOR_6" 23 "MAC_ADDRESS_SENSOR_7" 24 "MAC_ADDRESS_SENSOR_8" 25 "MAC_ADDRESS_SENSOR_9" 26 "CONN_METRICS_SENSOR_4" 27 "CONN_METRICS_SENSOR_5" 28 "CONN_METRICS_SENSOR_6" 29 "CONN_METRICS_SENSOR_7" 30 "CONN_METRICS_SENSOR_8" 31 "CONN_METRICS_SENSOR_9" 32 "CRC_SENSOR_4" 33 "CRC_SENSOR_5" 34 "CRC_SENSOR_6" 35 "CRC_SENSOR_7" 36 "CRC_SENSOR_8" 37 "CRC_SENSOR_9" 38 "CPU_TIME_SENSOR_4" 39 "CPU_TIME_SENSOR_5" 40 "CPU_TIME_SENSOR_6" 41 "CPU_TIME_SENSOR_7" 42 "CPU_TIME_SENSOR_8" 43 "CPU_TIME_SENSOR_9" 44 "SLEEP_STATS_SENSOR_4" 45 "SLEEP_STATS_SENSOR_5" 46 "SLEEP_STATS_SENSOR_6" 47 "SLEEP_STATS_SENSOR_7" 48 "SLEEP_STATS_SENSOR_8" 49 "SLEEP_STATS_SENSOR_9" ;
VAL_ 570 VCSEC_TPMSSystemState 0 "IDLE" 1 "ACTIVE" ;
VAL_ 570 VCSEC_TPMSSensorTIAppCRC0 0 "TPMS_CRC_SNA" ;
VAL_ 570 VCSEC_TPMSSensorTIAppCRC1 0 "TPMS_CRC_SNA" ;
VAL_ 570 VCSEC_TPMSSensorTIAppCRC2 0 "TPMS_CRC_SNA" ;
VAL_ 570 VCSEC_TPMSSensorTIAppCRC3 0 "TPMS_CRC_SNA" ;
VAL_ 570 VCSEC_TPMSSensorMLXAppCRC0 0 "TPMS_CRC_SNA" ;
VAL_ 570 VCSEC_TPMSSensorMLXAppCRC1 0 "TPMS_CRC_SNA" ;
VAL_ 570 VCSEC_TPMSSensorMLXAppCRC2 0 "TPMS_CRC_SNA" ;
VAL_ 570 VCSEC_TPMSSensorMLXAppCRC3 0 "TPMS_CRC_SNA" ;
VAL_ 577 VCFRONT_coolantFlowBatReason 0 "NONE" 1 "COOLANT_AIR_PURGE" 2 "NO_FLOW_REQ" 3 "OVERRIDE_BATT" 4 "ACTIVE_MANAGER_BATT" 5 "PASSIVE_MANAGER_BATT" 6 "BMS_FLOW_REQ" 7 "DAS_FLOW_REQ" 8 "OVERRIDE_PT" 9 "ACTIVE_MANAGER_PT" 10 "PASSIVE_MANAGER_PT" 11 "PCS_FLOW_REQ" 12 "DIR_FLOW_REQ" 13 "DIF_FLOW_REQ" 14 "DIRER_FLOW_REQ" 15 "DIREL_FLOW_REQ" 16 "MCU_FLOW_REQ" 17 "HP_FLOW_REQ" 18 "UI_FLOW_REQ" 19 "BMS_PPR_FLOW_REQ" 20 "DI_PPR_FLOW_REQ" ;
VAL_ 577 VCFRONT_coolantFlowPTReason 0 "NONE" 1 "COOLANT_AIR_PURGE" 2 "NO_FLOW_REQ" 3 "OVERRIDE_BATT" 4 "ACTIVE_MANAGER_BATT" 5 "PASSIVE_MANAGER_BATT" 6 "BMS_FLOW_REQ" 7 "DAS_FLOW_REQ" 8 "OVERRIDE_PT" 9 "ACTIVE_MANAGER_PT" 10 "PASSIVE_MANAGER_PT" 11 "PCS_FLOW_REQ" 12 "DIR_FLOW_REQ" 13 "DIF_FLOW_REQ" 14 "DIRER_FLOW_REQ" 15 "DIREL_FLOW_REQ" 16 "MCU_FLOW_REQ" 17 "HP_FLOW_REQ" 18 "UI_FLOW_REQ" 19 "BMS_PPR_FLOW_REQ" 20 "DI_PPR_FLOW_REQ" ;
VAL_ 577 VCFRONT_wasteHeatRequestType 0 "NONE" 1 "PARTIAL" 2 "FULL" 3 "BURN_IN" ;
VAL_ 577 VCFRONT_coolantAirPurgeBatState 0 "INACTIVE" 1 "ACTIVE" 2 "COMPLETE" 3 "INTERRUPTED" 4 "PENDING" ;
VAL_ 578 VCLEFT_rcmLVState 0 "OFF" 1 "ON" 2 "GOING_DOWN" 3 "FAULT" ;
VAL_ 578 VCLEFT_lumbarLVState 0 "OFF" 1 "ON" 2 "GOING_DOWN" 3 "FAULT" ;
VAL_ 578 VCLEFT_vehiclePowerStateDBG 0 "INIT" 1 "LOW_POWER_AWAKE" 2 "CONDITIONING" 3 "ACCESSORY" 4 "ACCESSORY_PLUS" 5 "DRIVE" 6 "OTA" 7 "WAIT_FOR_HIGH_POWER" 8 "TURN_ON_LV" 9 "SYSTEM_CHECKS" 10 "LV_ON" 11 "JUMP_START" 12 "LV_SHUTDOWN" 13 "GO_QUIET" 14 "SLEEP_SHUTDOWN" 15 "LOW_POWER_STANDBY" 16 "RESET" ;
VAL_ 579 VCRIGHT_hvacStatusIndex 0 "STATUS_UI" 1 "STATUS_VCFRONT" 2 "TARGETS_AND_MASS_FLOW" 3 "TEMPERATURES" 4 "TEMPERATURES_2" 5 "SEAT_CLIMATE" 6 "END" ;
VAL_ 579 VCRIGHT_hvacFrontRightSeatHeatStatus 0 "OFF" 1 "LEVEL1" 2 "LEVEL2" 3 "LEVEL3" ;
VAL_ 579 VCRIGHT_hvacSeatFrontLeftTempTarget 0 "OFF" ;
VAL_ 579 VCRIGHT_tempDuctLeftUpper 255 "SNA" ;
VAL_ 579 VCRIGHT_tempDuctRightUpper 255 "SNA" ;
VAL_ 579 VCRIGHT_tempDuctLeft 255 "SNA" ;
VAL_ 579 VCRIGHT_hvacFrontLeftSeatHeatStatus 0 "OFF" 1 "LEVEL1" 2 "LEVEL2" 3 "LEVEL3" ;
VAL_ 579 VCRIGHT_hvacEvapInletTempEstimate 1023 "SNA" ;
VAL_ 579 VCRIGHT_autoDefogStatus 0 "NONE" 1 "DEFOG" 2 "INTERMEDIATE_DEFOG" ;
VAL_ 579 VCRIGHT_hvacAirflowReason 0 "HVAC_OFF" 1 "MANUAL_FAN_SPEED" 2 "UI_SHORTCUT" 3 "CABIN_TEMPERATURE_CONTROL" 4 "MINIMUM_AUTO_AIRFLOW" 5 "STRATIFICATION_GLASS_ROOF" 6 "STRATIFICATION_INTERIOR_SURFACES" 7 "OCCUPANT_CONVECTION_REQUIREMENT" 8 "COLD_DUCT_LOCKOUT" 9 "CABIN_PURGE" 10 "CABIN_OVERHEAT_PROTECT" 11 "SCREEN_PROTECTION" 12 "EVAP_DRYING" 13 "EVAP_OIL_PURGE" 14 "BIOWEAPON_DEFENSE" 15 "NONE" ;
VAL_ 579 VCRIGHT_tempDuctRight 255 "SNA" ;
VAL_ 579 VCRIGHT_solarLoadOnVehicle 255 "SNA" ;
VAL_ 579 VCRIGHT_hvacAirDistributionMode 0 "NONE" 1 "FLOOR" 2 "PANEL" 3 "PANEL_FLOOR" 4 "DEFROST" 5 "DEFROST_FLOOR" 6 "DEFROST_PANEL" 7 "DEFROST_PANEL_FLOOR" ;
VAL_ 579 VCRIGHT_hvacBlowerSegment 0 "OFF" 1 "1" 2 "2" 3 "3" 4 "4" 5 "5" 6 "6" 7 "7" 8 "8" 9 "9" 10 "10" 11 "11" ;
VAL_ 579 VCRIGHT_hvacDuctTargetLeft 255 "SNA" ;
VAL_ 579 VCRIGHT_hvacRecirc 0 "AUTO" 1 "RECIRC" 2 "FRESH" ;
VAL_ 579 VCRIGHT_tempDuctLeftLower 255 "SNA" ;
VAL_ 579 VCRIGHT_hvacACRunning 0 "OFF" 1 "ON" ;
VAL_ 579 VCRIGHT_hvacPowerState 0 "OFF" 1 "ON" 2 "PRECONDITION" 3 "OVERHEAT_PROTECT_FANONLY" 4 "OVERHEAT_PROTECT" ;
VAL_ 579 VCRIGHT_hvacVentStatus 0 "BOTH" 1 "LEFT" 2 "RIGHT" ;
VAL_ 579 VCRIGHT_hvacDuctTargetRight 255 "SNA" ;
VAL_ 579 VCRIGHT_hvacSecondRowState 0 "AUTO" 1 "OFF" 2 "LOW" 3 "MED" 4 "HIGH" ;
VAL_ 579 VCRIGHT_tempDuctRightLower 255 "SNA" ;
VAL_ 579 VCRIGHT_hvacModelInitStatus 0 "NOT_INIT_WAIT_FOR_SENSORS" 1 "NOT_INIT_WAIT_FOR_GTW" 2 "INIT_FROM_SENSORS" 3 "INIT_FROM_SENSORS_PREDICTION_ERROR" 4 "INIT_FORWARD_CALC" 5 "INIT_WAITING_FOR_SENSORS" ;
VAL_ 580 FC_powerLimit 8191 "SNA" ;
VAL_ 580 FC_currentLimit 8191 "SNA" ;
VAL_ 580 FC_maxVoltageLimit 8191 "SNA" ;
VAL_ 580 FC_minVoltageLimit 8191 "SNA" ;
VAL_ 585 SCCM_highBeamStalkStatus 0 "IDLE" 1 "PULL" 2 "PUSH" 3 "SNA" ;
VAL_ 585 SCCM_washWipeButtonStatus 0 "NOT_PRESSED" 1 "1ST_DETENT" 2 "2ND_DETENT" 3 "SNA" ;
VAL_ 585 SCCM_turnIndicatorStalkStatus 0 "IDLE" 1 "UP_0_5" 2 "UP_1" 3 "UP_1_5" 4 "UP_2" 5 "DOWN_0_5" 6 "DOWN_1" 7 "DOWN_1_5" 8 "DOWN_2" 9 "SNA" ;
VAL_ 594 BMS_powerLimitsState 0 "NOT_CALCULATED_FOR_DRIVE" 1 "CALCULATED_FOR_DRIVE" ;
VAL_ 595 UI_ventPanelControlRequestIndex 0 "0" 1 "1" ;
VAL_ 595 UI_ventPanelLeftLateralMode 0 "SINGLE" 1 "SPLIT" ;
VAL_ 595 UI_ventPanelRightLateralMode 0 "SINGLE" 1 "SPLIT" ;
VAL_ 595 UI_hvacReqActiveVents 0 "BOTH" 1 "LEFT" 2 "RIGHT" ;
VAL_ 599 DI_uiSpeed 511 "DI_UI_SPEED_SNA" ;
VAL_ 599 DI_uiSpeedUnits 0 "MPH" 1 "KPH" ;
VAL_ 599 DI_vehicleSpeed 8191 "SNA" ;
VAL_ 599 DI_velocityEstimatorState 0 "NOT_INITIALIZED" 1 "WHEELS_NORMAL" 2 "WHEELS_REDUCED" 3 "BACKUP_WHEELS_A" 4 "BACKUP_WHEELS_B" 5 "BACKUP_MOTOR" ;
VAL_ 602 VCSEC_TPMSDisplayPressureFL 255 "SNA" ;
VAL_ 602 VCSEC_TPMSDisplayPressureFR 255 "SNA" ;
VAL_ 602 VCSEC_TPMSDisplayPressureRL 255 "SNA" ;
VAL_ 602 VCSEC_TPMSDisplayPressureRR 255 "SNA" ;
VAL_ 602 VCSEC_TPMSTellTale 0 "OFF" 1 "SOLID" 2 "FLASHING" ;
VAL_ 602 VCSEC_TPMSDisplaySoftWarningIndicationFL 0 "NOT_INDICATED" 1 "INDICATED" ;
VAL_ 602 VCSEC_TPMSDisplaySoftWarningIndicationFR 0 "NOT_INDICATED" 1 "INDICATED" ;
VAL_ 602 VCSEC_TPMSDisplaySoftWarningIndicationRL 0 "NOT_INDICATED" 1 "INDICATED" ;
VAL_ 602 VCSEC_TPMSDisplaySoftWarningIndicationRR 0 "NOT_INDICATED" 1 "INDICATED" ;
VAL_ 602 VCSEC_TPMSDisplayHardWarningIndicationFL 0 "NOT_INDICATED" 1 "INDICATED" ;
VAL_ 602 VCSEC_TPMSDisplayHardWarningIndicationFR 0 "NOT_INDICATED" 1 "INDICATED" ;
VAL_ 602 VCSEC_TPMSDisplayHardWarningIndicationRL 0 "NOT_INDICATED" 1 "INDICATED" ;
VAL_ 602 VCSEC_TPMSDisplayHardWarningIndicationRR 0 "NOT_INDICATED" 1 "INDICATED" ;
VAL_ 603 APP_watchdogState 0 "UNKNOWN" 1 "DEGRADED" 2 "CRITICAL" 3 "HEALTHY" 7 "SNA" ;
VAL_ 603 APP_fusedState 0 "UNKNOWN" 1 "UNFUSED" 2 "FUSED" 3 "SNA" ;
VAL_ 603 APP_factorySummonStatus 0 "SNA" 1 "ACTIVE" 2 "AVAILABLE" 3 "UNAVAILABLE_NO_QR_INSTRUCTION" 4 "UNAVAILABLE_GOAL_TOO_FAR" 5 "UNAVAILABLE_NO_GPS" 6 "UNAVAILABLE_VEHICLE_SPEED_INVALID" 7 "UNAVAILABLE_HEADING_NOT_INITIALIZED" 8 "END_OF_ROUTE" ;
VAL_ 603 APP_clipRecordingStatus 0 "NO_DRIVE" 1 "IDLE" 2 "RECORDING" 3 "TRIGGERED" 4 "FAULTED" ;
VAL_ 603 APP_summonUnavailableReason 0 "UNKNOWN" 1 "NONE" 2 "NOT_IN_PARK" 3 "CAMERA_STREAM" 4 "CAMERA_BLOCKED" 5 "ULTRASONIC_BLOCKED" 6 "ULTRASONIC_FAULT" 7 "CRUISE_UNAVAILABLE" 8 "EAC_UNAVAILABLE" 9 "PUBLIC_ROAD" 10 "POOR_CONNECTION" 11 "PHONE_GPS_UNAVAILABLE" 12 "EGO_GPS_UNAVAILABLE" 13 "PHONE_IS_TOO_FAR" 14 "END_OF_LEASH" 15 "CAMERA_NOT_CALIBRATED" 16 "VISION_HEALTH_CRITICAL" 17 "ULTRASONIC_STALE" 18 "ALL_SENSORS_OCCLUDED" 19 "PUBLIC_ROAD_BOUNDARIES_NOT_VALID" 20 "NO_CONTEXT" ;
VAL_ 603 APP_fsdSuspendState 0 "NOT_SUSPENDED" 1 "SUSPENDED" 3 "SNA" ;
VAL_ 603 APP_fsdRevokeStrikeoutCount 7 "SNA" ;
VAL_ 603 APP_sentryState 0 "OFF" 1 "IDLE" 2 "ARMED" 3 "AWARE" 4 "PANIC" 5 "QUIET" 6 "SNA" ;
VAL_ 605 CP_type 0 "US_TESLA" 1 "EURO_IEC" 2 "GB" 3 "IEC_CCS" ;
VAL_ 605 CP_latchState 0 "SNA" 1 "DISENGAGED" 2 "ENGAGED" 3 "BLOCKING" ;
VAL_ 605 CP_doorControlState 0 "doorInit" 1 "doorIdle" 2 "doorOpenRequested" 3 "doorOpening" 4 "doorSenseOpen" 5 "doorClosing" 6 "doorSenseClosed" ;
VAL_ 605 CP_chargeCableState 0 "UNKNOWN_SNA" 1 "NOT_CONNECTED" 2 "CONNECTED" ;
VAL_ 605 CP_latchControlState 0 "latchInit" 1 "latchIdle" 2 "latchDisengageRequested" 3 "latchDisengaging" 4 "latchDisengaged" 5 "latchEngaging" ;
VAL_ 605 CP_ledColor 0 "OFF" 1 "RED" 2 "GREEN" 3 "BLUE" 4 "WHITE" 5 "FLASHING_GREEN" 6 "FLASHING_AMBER" 7 "AMBER" 8 "RAVE" 9 "DEBUG" 10 "FLASHING_BLUE" ;
VAL_ 605 CP_faultLineSensed 0 "CLEARED" 1 "SET" ;
VAL_ 605 CP_doorPresenceState 0 "INIT" 1 "INIT_FROM_CHARGE" 2 "INIT_FROM_DRIVE" 3 "PRESENT" 4 "NOT_PRESENT" 5 "OFF_DRIVE" 6 "OFF_CHARGE" 7 "FAULT" ;
VAL_ 605 CP_inductiveSensorState 0 "INIT" 1 "POLL" 2 "SHUTDOWN" 3 "PAUSE" 4 "WAIT_FOR_INIT" 5 "FAULT" 6 "RESET" 7 "CONFIG" ;
VAL_ 605 CP_coldWeatherMode 0 "NONE" 1 "LATCH_MITIGATION" ;
VAL_ 609 VCFRONT_12VBatteryStatusIndex 0 "Mux0" 1 "Mux1" 2 "Mux2" ;
VAL_ 609 VCFRONT_IBSVoltageFiltered 4095 "IBS_VOLTAGE_SNA" ;
VAL_ 609 VCFRONT_voltageProfile 0 "CHARGE" 1 "FLOAT" 2 "REDUCED_FLOAT" 3 "ALWAYS_CLOSED_CONTACTORS" ;
VAL_ 609 VCFRONT_batterySMState 0 "INIT" 1 "CHARGE" 2 "DISCHARGE" 3 "STANDBY" 4 "RESISTANCE_ESTIMATION" 5 "OTA_STANDBY" 6 "DISCONNECTED_BATTERY_TEST" 7 "SHORTED_CELL_TEST" 8 "FAULT" 9 "RECOVERY" ;
VAL_ 609 VCFRONT_IBSTemperature 32767 "IBS_TEMPERATURE_SNA" ;
VAL_ 609 VCFRONT_LVBMS_LVBusVoltageSourceDBG 0 "NONE" 1 "IBS" 2 "VBAT_MONITOR" 3 "LVBMS" ;
VAL_ 609 VCFRONT_IBSVoltageRawDBG 4095 "IBS_VOLTAGE_SNA" ;
VAL_ 609 VCFRONT_LVBatterySupportRqrdTrigger 0 "NONE" 1 "IBS_FILTERED_VOLTAGE" 2 "PACK_FILTERED_VOLTAGE" 4 "IBS_RAW_VOLTAGE" 8 "PACK_RAW_VOLTAGE" 16 "VBAT_RAW_VOLTAGE" 32 "UNKNOWN_VOLTAGE" 64 "AH_COUNT" 128 "PERIODIC_CHARGE" 256 "POWER_ON_RESET" 512 "EXIT_TRANSPORT_MODE" 1024 "POST_OTA" ;
VAL_ 609 VCFRONT_IBSVoltage 4095 "SNA" ;
VAL_ 609 VCFRONT_silentWakeIBSCurrent 4095 "SNA" ;
VAL_ 609 VCFRONT_LVBatteryStatusForDrive 0 "NOT_READY_FOR_DRIVE" 1 "READY_FOR_DRIVE" 2 "EXIT_DRIVE_REQUESTED" ;
VAL_ 609 VCFRONT_LVBatteryType 0 "CATL_LI_ION" 1 "UNKNOWN" ;
VAL_ 610 VCLEFT_steeringColumnSMState 0 "SNA" 1 "RECALL" 2 "CALIBRATE" 3 "MANUAL_CONTROL" ;
VAL_ 610 VCLEFT_steeringColumnLastRequest 0 "SNA" 1 "NONE" 2 "UP" 3 "DOWN" 4 "IN" 5 "OUT" ;
VAL_ 611 VCRIGHT_logging10HzIndex 0 "HVAC_ACTUATOR_TARGETS_1" 1 "HVAC_ACTUATOR_TARGETS_2" 2 "HVAC_ACTUATOR_POSITIONS_1" 3 "HVAC_ACTUATOR_POSITIONS_2" 4 "END" ;
VAL_ 611 VCRIGHT_hvacLHBleedActuatorState 0 "BRAKING" 1 "RUNNING" 2 "COASTING" ;
VAL_ 611 VCRIGHT_hvacRHBleedActuatorState 0 "BRAKING" 1 "RUNNING" 2 "COASTING" ;
VAL_ 611 VCRIGHT_hvacLHVaneActuatorState 0 "BRAKING" 1 "RUNNING" 2 "COASTING" ;
VAL_ 611 VCRIGHT_hvacRHVaneActuatorState 0 "BRAKING" 1 "RUNNING" 2 "COASTING" ;
VAL_ 611 VCRIGHT_hvacUpperModeActState 0 "BRAKING" 1 "RUNNING" 2 "COASTING" ;
VAL_ 611 VCRIGHT_hvacLowerModeActState 0 "BRAKING" 1 "RUNNING" 2 "COASTING" ;
VAL_ 611 VCRIGHT_hvacIntakeActuatorState 0 "BRAKING" 1 "RUNNING" 2 "COASTING" ;
VAL_ 614 DIR_elecPower 4294966272 "SNA" ;
VAL_ 614 DIR_drivePowerMax 511 "SNA" ;
VAL_ 616 DI_sysDrivePowerMax 511 "SNA" ;
VAL_ 616 DI_primaryUnitSiliconType 0 "MOSFET" 1 "IGBT" ;
VAL_ 616 DI_sysRegenPowerMax 255 "SNA" ;
VAL_ 626 VCLEFT_epbmDebugIndex 0 "STATES" 1 "TRANSITIONS" ;
VAL_ 626 VCLEFT_epbmCaliperState 0 "UNSAVED" 1 "UNKNOWN" 2 "REAPPLY" 3 "PARK" 4 "OPEN" 5 "SERVICE" 6 "WINCHMODE" ;
VAL_ 626 VCLEFT_summonFaultReason 0 "NONE" 1 "DI_MIA" 2 "DAS_MIA" 3 "ESP_MIA" 4 "EPBM_MIA" 5 "DI_FAULT" 6 "DI_APC_FAULT" 7 "DAS_FAULT" 8 "ESP_FAULT" 9 "VEH_CAN_FAULT" 10 "EAC_NOT_ALLOWED" 11 "EPBM_REQUEST" 12 "SPEED" 13 "EXTERNAL" 14 "PARK_MIA" 15 "PM_MIA" 16 "PM_REQUEST" 17 "OOC" 18 "MISMATCH" 19 "EPB_FAULT" 20 "DI_STATE_INVALID" 21 "PASSIVE_REQUEST" 22 "EPBREMOTE_MIA" 23 "REMOTE_SUMMON_FAULTED" 24 "LOCAL_UNIT_FAULTED" 25 "REMOTE_UNIT_FAULTED" 26 "START_IN_UNAVAILABLE" 27 "INVALID_REMOTE_STATE" 28 "REMOTE_DID_NOT_START" ;
VAL_ 626 VCLEFT_epbSummonState 0 "INIT" 1 "IDLE" 2 "ARMED" 3 "ACTIVE" 4 "COMPLETE" 5 "FAULT" 6 "UNAVAILABLE" ;
VAL_ 626 VCLEFT_epbmSummonState 0 "INIT" 1 "IDLE" 2 "ARMED" 3 "ACTIVE" 4 "COMPLETE" 5 "FAULT" 6 "UNAVAILABLE" ;
VAL_ 626 VCLEFT_epbUnitStatus 0 "UNKNOWN" 1 "OPEN" 2 "DYNAMIC" 3 "PARK" 4 "START" 5 "SERVICE" 6 "WINCHMODE" 7 "WINCHMODE_RELEASING" 8 "PARKING" 9 "DYNAMIC_APPLYING" 10 "RELEASING" 11 "SERVICE_RELEASING" 12 "PARK_PENDING" 13 "WINCHMODE_PENDING" 14 "SUMMON" 15 "SUMMON_RELEASING" 16 "SUMMON_PARKING" 17 "EXTERNAL_DYNAMIC" 18 "RELEASING_FOR_EXTERNAL_PARK" 19 "EXTERNAL_PARKING" 20 "DYNAMIC_PARKING" 21 "FREE_ROLL_MODE" 22 "COUNT" ;
VAL_ 626 VCLEFT_epbmFaultStatus 0 "NOMINAL" 1 "RETRY" 2 "FAULT" 3 "FAULT_IDLE" ;
VAL_ 626 VCLEFT_epbFaultStatus 0 "NOMINAL" 1 "RETRY" 2 "FAULT" 3 "FAULT_IDLE" ;
VAL_ 626 VCLEFT_epbmSystemStatus 0 "UNKNOWN" 1 "RELEASED" 2 "PARKED" 3 "DYNAMIC" 4 "PARKING" 5 "RELEASING" 6 "FAULT" 7 "FAULT_SECURE" 8 "MISMATCH" ;
VAL_ 627 UI_powerStateRequest 0 "IDLE" 1 "ACCESSORY" 2 "ACCESSORY_PLUS" 3 "DRIVE_SUMMON" ;
VAL_ 627 UI_frunkRequest 0 "NONE" 1 "MOVE" 2 "STOP" 3 "SNA" ;
VAL_ 627 UI_wiperMode 0 "SNA" 1 "SERVICE" 2 "NORMAL" 3 "PARK" ;
VAL_ 627 UI_steeringBacklightEnabled 0 "DISABLED" 1 "ENABLED" ;
VAL_ 627 UI_steeringButtonMode 0 "OFF" 1 "STEERING_COLUMN_ADJ" 2 "MIRROR_LEFT" 3 "MIRROR_RIGHT" 4 "HEADLIGHT_LEFT" 5 "HEADLIGHT_RIGHT" 6 "WIPERS" ;
VAL_ 627 UI_lockRequest 0 "IDLE" 1 "LOCK" 2 "UNLOCK" 3 "REMOTE_UNLOCK" 4 "REMOTE_LOCK" 7 "SNA" ;
VAL_ 627 UI_mirrorFoldRequest 0 "IDLE" 1 "RETRACT" 2 "PRESENT" 3 "SNA" ;
VAL_ 627 UI_remoteStartRequest 0 "IDLE" 1 "START" 4 "SNA" ;
VAL_ 627 UI_displayBrightnessLevel 255 "SNA" ;
VAL_ 627 UI_frontLeftSeatHeatReq 0 "OFF" 1 "LEVEL1" 2 "LEVEL2" 3 "LEVEL3" ;
VAL_ 627 UI_frontRightSeatHeatReq 0 "OFF" 1 "LEVEL1" 2 "LEVEL2" 3 "LEVEL3" ;
VAL_ 627 UI_rearLeftSeatHeatReq 0 "OFF" 1 "LEVEL1" 2 "LEVEL2" 3 "LEVEL3" ;
VAL_ 627 UI_rearCenterSeatHeatReq 0 "OFF" 1 "LEVEL1" 2 "LEVEL2" 3 "LEVEL3" ;
VAL_ 627 UI_rearRightSeatHeatReq 0 "OFF" 1 "LEVEL1" 2 "LEVEL2" 3 "LEVEL3" ;
VAL_ 627 UI_remoteClosureRequest 0 "IDLE" 1 "REAR_TRUNK_MOVE" 2 "FRONT_TRUNK_MOVE" 3 "SNA" ;
VAL_ 627 UI_wiperRequest 0 "SNA" 1 "OFF" 2 "AUTO" 3 "SLOW_INTERMITTENT" 4 "FAST_INTERMITTENT" 5 "SLOW_CONTINUOUS" 6 "FAST_CONTINUOUS" ;
VAL_ 627 UI_domeLightSwitch 0 "OFF" 1 "ON" 2 "AUTO" ;
VAL_ 627 UI_driveStateRequest 0 "IDLE" 1 "START" ;
VAL_ 633 DIR_hvilStatus 0 "DISABLED" 1 "OPEN" 2 "CLOSED" 3 "SNA" ;
VAL_ 633 DIR_hvilSupplyState 0 "NOT_AVAILABLE" 1 "INACTIVE" 2 "ACTIVE" ;
VAL_ 633 DIR_vBatQF 0 "NOT_QUALIFIED" 1 "QUALIFIED" ;
VAL_ 633 DIR_powerStageSafeState 0 "NONE" 1 "ALL_OFF" 2 "3PS_HIGH" 3 "3PS_LOW" ;
VAL_ 633 DIR_gateDriveState 0 "INIT" 1 "SELFTEST" 2 "CONFIGURING" 3 "CONFIGURED" 4 "NOT_CONFIGURED" ;
VAL_ 633 DIR_gateDriveSupplyState 0 "DOWN" 1 "RISING" 2 "UP" 3 "FALLING" ;
VAL_ 634 DIF_hvilStatus 0 "DISABLED" 1 "OPEN" 2 "CLOSED" 3 "SNA" ;
VAL_ 634 DIF_hvilSupplyState 0 "NOT_AVAILABLE" 1 "INACTIVE" 2 "ACTIVE" ;
VAL_ 634 DIF_vBatQF 0 "NOT_QUALIFIED" 1 "QUALIFIED" ;
VAL_ 634 DIF_powerStageSafeState 0 "NONE" 1 "ALL_OFF" 2 "3PS_HIGH" 3 "3PS_LOW" ;
VAL_ 634 DIF_gateDriveState 0 "INIT" 1 "SELFTEST" 2 "CONFIGURING" 3 "CONFIGURED" 4 "NOT_CONFIGURED" ;
VAL_ 634 DIF_gateDriveSupplyState 0 "DOWN" 1 "RISING" 2 "UP" 3 "FALLING" ;
VAL_ 642 VCLEFT_hvacBlowerOutputDuty 127 "SNA" ;
VAL_ 642 VCLEFT_hvacBlowerRPMTarget 1023 "SNA" ;
VAL_ 642 VCLEFT_hvacBlowerTorque 1023 "SNA" ;
VAL_ 642 VCLEFT_hvacBlowerFETTemp 127 "SNA" ;
VAL_ 642 VCLEFT_hvacBlowerIDc 127 "SNA" ;
VAL_ 644 UI_factoryMode 0 "DISABLED" 1 "ENABLED" ;
VAL_ 644 UI_transportMode 0 "DISABLED" 1 "ENABLED" ;
VAL_ 644 UI_showroomMode 0 "DISABLED" 1 "ENABLED" ;
VAL_ 644 UI_serviceMode 0 "DISABLED" 1 "ENABLED" ;
VAL_ 644 UI_diagnosticsAllowed 0 "NOT_ALLOWED" 1 "ALLOWED" ;
VAL_ 644 UI_serviceModePlus 0 "DISABLED" 1 "ENABLED" ;
VAL_ 644 UI_closureEasterEggStatus 0 "IDLE" 1 "REQ_RECD_WAITING_STANDARD" 2 "REQ_RECD_WAITING_DYNAMIC" 3 "PLAYING" ;
VAL_ 645 UI_driverProfileRecallIndex 0 "SNA" 1 "1" 2 "2" 3 "3" 4 "4" 5 "5" ;
VAL_ 646 UI_driverProfileSelectionType 0 "MANUAL" 1 "AUTOMATIC" 2 "NONE" ;
VAL_ 648 EPBL_unitStatus 0 "UNKNOWN" 1 "OPEN" 2 "DYNAMIC" 3 "PARK" 4 "START" 5 "SERVICE" 6 "WINCHMODE" 7 "WINCHMODE_RELEASING" 8 "PARKING" 9 "DYNAMIC_APPLYING" 10 "RELEASING" 11 "SERVICE_RELEASING" 12 "PARK_PENDING" 13 "WINCHMODE_PENDING" 14 "SUMMON" 15 "SUMMON_RELEASING" 16 "SUMMON_PARKING" 17 "EXTERNAL_DYNAMIC" 18 "RELEASING_FOR_EXTERNAL_PARK" 19 "EXTERNAL_PARKING" 20 "DYNAMIC_PARKING" 21 "FREE_ROLL_MODE" 22 "COUNT" ;
VAL_ 648 EPBL_unitFaultStatus 0 "NOMINAL" 1 "RETRY" 2 "FAULT" 3 "FAULT_IDLE" ;
VAL_ 648 EPBL_summonState 0 "INIT" 1 "IDLE" 2 "ARMED" 3 "ACTIVE" 4 "COMPLETE" 5 "FAULT" 6 "UNAVAILABLE" ;
VAL_ 648 EPBL_csmFaultReason 0 "NONE" 1 "EPBM_DISABLED" 2 "EPBM_FAULTED" 3 "STATE_MISMATCH" 4 "TIMEOUT_CALIBRATE" 5 "APPLY_BLOCKED" 6 "RELEASE_BLOCKED" 7 "TIMEOUT_APPLY_COMPLETE" 8 "TIMEOUT_APPLY_INRUSH" 9 "TIMEOUT_EPB_WAIT_FOR_CLAMP" 10 "TIMEOUT_EPBM_WAIT_FOR_CLAMP" 11 "TIMEOUT_RELEASE_INRUSH" 12 "TIMEOUT_RELEASE_WAIT_FOR_ENDSTOP" 13 "TIMEOUT_RELEASE_NO_LOAD" 14 "TIMEOUT_RELEASE_COMPLETE" 15 "TIMEOUT_EPBM_CUTOFF" 16 "TIMEOUT_NO_RAMP" 17 "TIMEOUT_EPBM_START" 18 "MOTOR_IDLE_FAULT" 19 "MOTOR_ACTIVE_FAULT" 20 "MOTOR_NOT_READY" 21 "EPBM_MIA" 22 "NVM_MISMATCH" 23 "REMOTE_MIA" ;
VAL_ 648 EPBL_esmOperationTrigger 0 "PBUTTON_PRESSED_STOPPED" 1 "PBUTTON_PRESSED_OKTOPARK" 2 "PBUTTON_PRESSED_FAST" 3 "PBUTTON_PRESSED_UNKNOWN" 4 "PBUTTON_RELEASED" 5 "ACTIVE_PARK_REQUEST" 6 "DI_UNPARK" 7 "TOUCHSCREEN" 8 "WINCHMODE_EXIT" 9 "WINCHMODE_ENTER" 10 "WINCHMODE_UNAVAILABLE" 11 "SERVICE" 12 "DIAG_CLOSE" 13 "DIAG_OPEN" 14 "DIAG_EXIT" 15 "USER_CONFIRMED" 16 "USER_CANCEL" 17 "SPEED_STOPPED" 18 "SPEED_OKAYTOPARK" 19 "SPEED_FAST" 20 "TIMEOUT" 21 "SAVESTATE_ON_BOOT" 22 "REAPPLY" 23 "SUMMON_COMPLETE" 24 "FAULT" 25 "SUMMON_FAULT" 26 "DISQUALIFIED" 27 "EPBM_DISQUALIFIED" 28 "ACCELERATION" 29 "SYSTEM_APPLY" 30 "DRIVER_IS_LEAVING" 31 "AUTOPARK_END" 32 "UI_DOOR_OPEN_REQUEST" 33 "TOUCHSCREEN_INVALID" ;
VAL_ 648 EPBL_summonFaultReason 0 "NONE" 1 "DI_MIA" 2 "DAS_MIA" 3 "ESP_MIA" 4 "EPBM_MIA" 5 "DI_FAULT" 6 "DI_APC_FAULT" 7 "DAS_FAULT" 8 "ESP_FAULT" 9 "VEH_CAN_FAULT" 10 "EAC_NOT_ALLOWED" 11 "EPBM_REQUEST" 12 "SPEED" 13 "EXTERNAL" 14 "PARK_MIA" 15 "PM_MIA" 16 "PM_REQUEST" 17 "OOC" 18 "MISMATCH" 19 "EPB_FAULT" 20 "DI_STATE_INVALID" 21 "PASSIVE_REQUEST" 22 "EPBREMOTE_MIA" 23 "REMOTE_SUMMON_FAULTED" 24 "LOCAL_UNIT_FAULTED" 25 "REMOTE_UNIT_FAULTED" 26 "START_IN_UNAVAILABLE" 27 "INVALID_REMOTE_STATE" 28 "REMOTE_DID_NOT_START" ;
VAL_ 648 EPBL_telltaleLocal 0 "LAMP_OFF" 1 "LAMP_RED_ON" 2 "LAMP_AMBER_ON" 3 "LAMP_RED_FLASH" 7 "SNA" ;
VAL_ 648 EPBL_internalCDPRequest 0 "NOT_REQUESTED" 1 "REQUESTED" ;
VAL_ 648 EPBL_esmSpeedClass 0 "STOPPED" 1 "SYSTEM_APPLY_OK" 2 "USER_APPLY_OK" 3 "FAST" 4 "UNKNOWN" ;
VAL_ 648 EPBL_learnedEpbConfig 0 "UNKNOWN" 1 "MODEL3_BASE" 2 "MODEL3_PERFORMANCE" 3 "MODELS_BASE" 4 "MODELY_BASE" 5 "MODELY_PERFORMANCE" 6 "MODELX_BASE" 7 "MODEL3_PERFORMANCE_V2" 8 "MODELY_PERFORMANCE_V2" 9 "MODELS_CERAMIC" ;
VAL_ 649 VCLEFT_logging10HzIndex 0 "Mux0" 1 "Mux1" ;
VAL_ 649 VCLEFT_hvacBlowerRs 255 "SNA" ;
VAL_ 649 VCLEFT_hvacBlowerIPhase0 255 "SNA" ;
VAL_ 649 VCLEFT_hvacBlowerIPhase1 255 "SNA" ;
VAL_ 649 VCLEFT_hvacBlowerIPhase2 255 "SNA" ;
VAL_ 649 VCLEFT_hvacBlower_IO_CBC_Status 0 "IDLE" 1 "RX" ;
VAL_ 649 VCLEFT_hvacBlowerCBCEstState 0 "ERROR" 1 "IDLE" 2 "ROVERL" 3 "RS" 4 "RAMPUP" 5 "IDRATED" 6 "RATEDFLUX_OL" 7 "RATEDFLUX" 8 "RAMPDOWN" 9 "LOCKROTOR" 10 "INDUCTANCE_EST" 11 "ROTOR_RESISTANCE" 12 "MOTOR_IDENTIFIED" 13 "ONLINE" 14 "COUNT" ;
VAL_ 649 VCLEFT_hvacBlowerCBCCtrlState 0 "ERROR" 1 "IDLE" 2 "OFFLINE" 3 "ONLINE" 4 "COUNT" ;
VAL_ 649 VCLEFT_hvacBlowerITerm 127 "SNA" ;
VAL_ 659 UI_steeringTuneRequest 0 "COMFORT" 1 "STANDARD" 2 "SPORT" ;
VAL_ 659 UI_tractionControlMode 0 "NORMAL_SELECTED" 1 "SLIP_START_SELECTED" 2 "DEV_MODE_1_SELECTED" 3 "DEV_MODE_2_SELECTED" 4 "ROLLS_MODE_SELECTED" 5 "DYNO_MODE_SELECTED" 6 "OFFROAD_ASSIST_SELECTED" ;
VAL_ 659 UI_parkBrakeRequest 0 "IDLE" 1 "PRESSED" 3 "SNA" ;
VAL_ 659 UI_winchModeRequest 0 "IDLE" 1 "ENTER" 2 "EXIT" ;
VAL_ 659 UI_zeroSpeedConfirmed 0 "CANCELED" 1 "CONFIRMED" 2 "UNUSED" 3 "SNA" ;
VAL_ 659 UI_trailerMode 0 "OFF" 1 "ON" ;
VAL_ 659 UI_distanceUnits 0 "KM" 1 "MILES" ;
VAL_ 659 UI_accOvertakeEnable 0 "ACC_OVERTAKE_OFF" 1 "ACC_OVERTAKE_ON" 3 "SNA" ;
VAL_ 659 UI_aebEnable 0 "AEB_OFF" 1 "AEB_ON" 3 "SNA" ;
VAL_ 659 UI_aesEnable 0 "AES_OFF" 1 "AES_ON" 3 "SNA" ;
VAL_ 659 UI_ahlbEnable 0 "AHLB_OFF" 1 "AHLB_ON" 3 "SNA" ;
VAL_ 659 UI_autoLaneChangeEnable 0 "OFF" 1 "ON" 3 "SNA" ;
VAL_ 659 UI_autoParkRequest 0 "NONE" 1 "PARK_LEFT_PARALLEL" 2 "PARK_LEFT_CROSS" 3 "PARK_RIGHT_PARALLEL" 4 "PARK_RIGHT_CROSS" 5 "PARALLEL_PULL_OUT_TO_LEFT" 6 "PARALLEL_PULL_OUT_TO_RIGHT" 7 "ABORT" 8 "COMPLETE" 9 "SEARCH" 10 "PAUSE" 11 "RESUME" 12 "BEGIN_PARKING" 15 "SNA" ;
VAL_ 659 UI_bsdEnable 0 "BSD_OFF" 1 "BSD_ON" 3 "SNA" ;
VAL_ 659 UI_fcwEnable 0 "FCW_OFF" 1 "FCW_ON" 3 "SNA" ;
VAL_ 659 UI_fcwSensitivity 0 "AEB_SENSITIVITY_EARLY" 1 "AEB_SENSITIVITY_AVERAGE" 2 "AEB_SENSITIVITY_LATE" 3 "SNA" ;
VAL_ 659 UI_latControlEnable 0 "OFF" 1 "ON" 2 "UNAVAILABLE" 3 "SNA" ;
VAL_ 659 UI_ldwEnable 0 "NO_HAPTIC" 1 "LDW_TRIGGERS_HAPTIC" 3 "SNA" ;
VAL_ 659 UI_pedalSafetyEnable 0 "PEDAL_SAFETY_OFF" 1 "PEDAL_SAFETY_ON" 3 "SNA" ;
VAL_ 659 UI_pedalMap_epas 0 "CHILL" 1 "SPORT" 2 "PERFORMANCE" ;
VAL_ 659 UI_redLightStopSignEnable 0 "RLSSW_OFF" 1 "RLSSW_ON" 3 "SNA" ;
VAL_ 659 UI_selfParkTune 15 "SNA" ;
VAL_ 660 UI_lightFlashRequest 0 "INACTIVE" 1 "HOMELINK" 2 "MOBILE_APP" 3 "SENTRY" ;
VAL_ 660 UI_packTempLoggingRequest 0 "FALSE" 1 "TRUE" ;
VAL_ 660 UI_windowRequest 0 "IDLE" 1 "GOTO_PERCENT" 2 "GOTO_VENT" 3 "GOTO_CLOSED" 5 "GOTO_CLOSED_CARWASH" 6 "GOTO_PERCENT_RELATIVE" ;
VAL_ 663 UI_adaptiveRideRequest 0 "COMFORT" 1 "AUTO" 2 "SPORT" 3 "ADVANCED" ;
VAL_ 663 UI_suspensionLoweringRequest 0 "NEVER" 1 "ALWAYS" 2 "AUTO" 3 "SNA" ;
VAL_ 663 UI_geofenceLevelingRequest 0 "NONE" 1 "HIGH_TEMPORARY" 2 "VERY_HIGH_TEMPORARY" 3 "HIGH_PERSIST" 4 "VERY_HIGH_PERSIST" 5 "SNA" ;
VAL_ 663 UI_jackModeToggleRequest 0 "NONE" 1 "ACTIVE" ;
VAL_ 663 UI_roadRoughnessLookahead 127 "SNA" ;
VAL_ 663 UI_roadRoughnessStart 31 "SNA" ;
VAL_ 663 UI_suspensionLevelRequest 0 "NONE" 1 "VERY_LOW_LEVEL" 2 "LOW_LEVEL" 3 "STANDARD_LEVEL" 4 "HIGH_LEVEL_TEMPORARY" 5 "VERY_HIGH_LEVEL_TEMPORARY" 6 "HIGH_LEVEL_PERSIST" 7 "VERY_HIGH_LEVEL_PERSIST" ;
VAL_ 676 PCS_chgPhATemp 4294966273 "SNA" ;
VAL_ 676 PCS_chgPhBTemp 4294966273 "SNA" ;
VAL_ 676 PCS_chgPhCTemp 4294966273 "SNA" ;
VAL_ 676 PCS_dcdcTemp 4294966273 "SNA" ;
VAL_ 676 PCS_ambientTemp 4294966273 "SNA" ;
VAL_ 676 PCS_dcdcBusbarTemp 511 "SNA" ;
VAL_ 679 CMPD_state 0 "INIT" 1 "RUNNING" 2 "STANDBY" 3 "FAULT" 4 "IDLE" 15 "SNA" ;
VAL_ 679 CMPD_wasteHeatState 0 "OFF" 1 "ACTIVE" 2 "NOT_AVAILABLE" 3 "UNUSED" ;
VAL_ 680 EPBL_systemStatus 0 "UNKNOWN" 1 "RELEASED" 2 "PARKED" 3 "DYNAMIC" 4 "PARKING" 5 "RELEASING" 6 "FAULT" 7 "FAULT_SECURE" 8 "MISMATCH" ;
VAL_ 680 EPBL_freeRollModeStatus 0 "UNAVAILABLE" 1 "AVAILABLE" 2 "ENABLED" ;
VAL_ 680 EPBL_telltale 0 "LAMP_OFF" 1 "LAMP_RED_ON" 2 "LAMP_AMBER_ON" 3 "LAMP_RED_FLASH" 7 "SNA" ;
VAL_ 680 EPBL_cdpRequest 0 "NOT_REQUESTED" 1 "REQUESTED" ;
VAL_ 680 EPBL_brakeDiscWipeRequest 0 "NONE" 1 "LIGHT" 2 "STRONG" 3 "SNA" ;
